VERSION ""

NS_ :

BS_:

BU_: EMS EAS

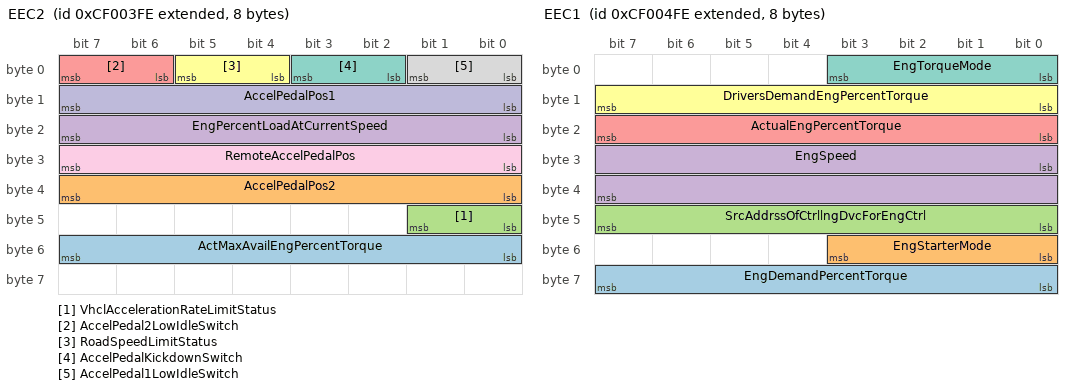
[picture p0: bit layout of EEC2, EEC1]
BO_ 2364539902 EEC2: 8 Vector__XXX
 SG_ ActMaxAvailEngPercentTorque : 48|8@1+ (0.4,0) [0|100] "%" Vector__XXX
 SG_ AccelPedalPos2 : 32|8@1+ (0.4,0) [0|100] "%" Vector__XXX
 SG_ VhclAccelerationRateLimitStatus : 40|2@1+ (1,0) [0|3] "" Vector__XXX
 SG_ EngPercentLoadAtCurrentSpeed : 16|8@1+ (1,0) [0|250] "%" Vector__XXX
 SG_ AccelPedal2LowIdleSwitch : 6|2@1+ (1,0) [0|3] "" Vector__XXX
 SG_ RoadSpeedLimitStatus : 4|2@1+ (1,0) [0|3] "" Vector__XXX
 SG_ AccelPedalKickdownSwitch : 2|2@1+ (1,0) [0|3] "" Vector__XXX
 SG_ AccelPedal1LowIdleSwitch : 0|2@1+ (1,0) [0|3] "" Vector__XXX
 SG_ RemoteAccelPedalPos : 24|8@1+ (0.4,0) [0|100] "%" Vector__XXX
 SG_ AccelPedalPos1 : 8|8@1+ (0.4,0) [0|100] "%" Vector__XXX

BO_ 2364540158 EEC1: 8 Vector__XXX
 SG_ EngDemandPercentTorque : 56|8@1+ (1,-125) [-125|125] "%" Vector__XXX
 SG_ EngStarterMode : 48|4@1+ (1,0) [0|15] "" Vector__XXX
 SG_ SrcAddrssOfCtrllngDvcForEngCtrl : 40|8@1+ (1,0) [0|255] "" Vector__XXX
 SG_ EngSpeed : 24|16@1+ (0.125,0) [0|8031.875] "rpm" Vector__XXX
 SG_ ActualEngPercentTorque : 16|8@1+ (1,-125) [-125|125] "%" Vector__XXX
 SG_ DriversDemandEngPercentTorque : 8|8@1+ (1,-125) [-125|125] "%" Vector__XXX
 SG_ EngTorqueMode : 0|4@1+ (1,0) [0|15] "" Vector__XXX

BO_ 2566768126 ECUID: 8 Vector__XXX

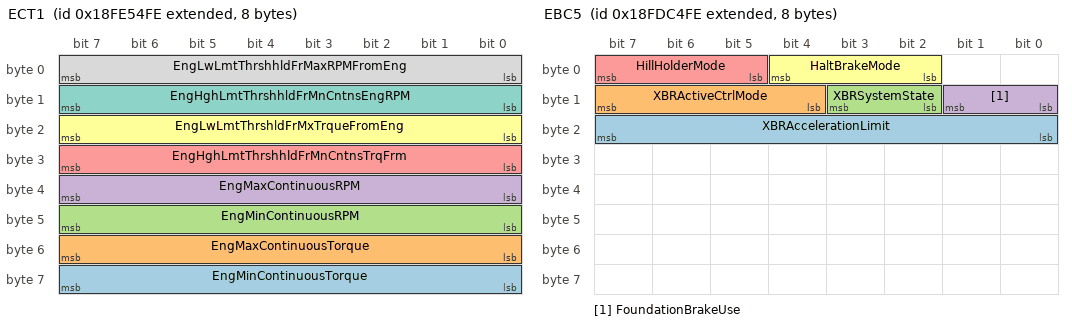
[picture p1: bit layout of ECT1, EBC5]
BO_ 2566804734 ECT1: 8 Vector__XXX
 SG_ EngMinContinuousTorque : 56|8@1+ (1,-125) [-125|125] "%" Vector__XXX
 SG_ EngMaxContinuousTorque : 48|8@1+ (1,-125) [-125|125] "%" Vector__XXX
 SG_ EngMinContinuousRPM : 40|8@1+ (32,0) [0|8000] "rpm" Vector__XXX
 SG_ EngMaxContinuousRPM : 32|8@1+ (32,0) [0|8000] "rpm" Vector__XXX
 SG_ EngHghLmtThrshhldFrMnCntnsTrqFrm : 24|8@1+ (1,-125) [-125|125] "%" Vector__XXX
 SG_ EngLwLmtThrshldFrMxTrqueFromEng : 16|8@1+ (1,-125) [-125|125] "%" Vector__XXX
 SG_ EngHghLmtThrshhldFrMnCntnsEngRPM : 8|8@1+ (32,0) [0|8000] "rpm" Vector__XXX
 SG_ EngLwLmtThrshhldFrMaxRPMFromEng : 0|8@1+ (32,0) [0|8000] "rpm" Vector__XXX

BO_ 2566841342 EC: 38 Vector__XXX
 SG_ SupportTSC1CtrlPurposeGroup4Of4 : 304|8@1+ (1,0) [0|255] "" Vector__XXX
 SG_ SupportVariableRateTSC1Message : 272|8@1+ (1,0) [0|255] "" Vector__XXX
 SG_ SupportTSC1CtrlPurposeGroup3Of4 : 296|8@1+ (1,0) [0|255] "" Vector__XXX
 SG_ SupportTSC1CtrlPurposeGroup2Of4 : 288|8@1+ (1,0) [0|255] "" Vector__XXX
 SG_ SupportTSC1CtrlPurposeGroup1Of4 : 280|8@1+ (1,0) [0|255] "" Vector__XXX
 SG_ EngDefaultTorqueLimit : 256|16@1+ (1,0) [0|64255] "Nm" Vector__XXX
 SG_ EngMomentOfInertia : 240|16@1+ (0.004,0) [0|257.02] "kg-m²" Vector__XXX
 SG_ EngExRngRqdSpdCtrlRngUpperLimit : 224|16@1+ (0.125,0) [0|8031.875] "rpm" Vector__XXX
 SG_ EngRqdTorqueCtrlRangeUpperLimit : 216|8@1+ (1,-125) [-125|125] "%" Vector__XXX
 SG_ EngRqdTorqueCtrlRangeLowerLimit : 208|8@1+ (1,-125) [-125|125] "%" Vector__XXX
 SG_ EngRqedSpeedCtrlRangeUpperLimit : 200|8@1+ (10,0) [0|2500] "rpm" Vector__XXX
 SG_ EngRqedSpeedCtrlRangeLowerLimit : 192|8@1+ (10,0) [0|2500] "rpm" Vector__XXX
 SG_ EngMxMomentaryOverrideTimeLimit : 184|8@1+ (0.1,0) [0|25] "s" Vector__XXX
 SG_ EngMxMmntaryOverrideSpeedPoint7 : 168|16@1+ (0.125,0) [0|8031.875] "rpm" Vector__XXX
 SG_ EngReferenceTorque : 152|16@1+ (1,0) [0|64255] "Nm" Vector__XXX
 SG_ EngSpeedAtHighIdlePoint6 : 120|16@1+ (0.125,0) [0|8031.875] "rpm" Vector__XXX
 SG_ EngGainOfEndspeedGovernor : 136|16@1+ (0.00078125,0) [0|50.2] "%/rpm" Vector__XXX
 SG_ EngPercentTorqueAtPoint5 : 112|8@1+ (1,-125) [-125|125] "%" Vector__XXX
 SG_ EngSpeedAtPoint5 : 96|16@1+ (0.125,0) [0|8031.875] "rpm" Vector__XXX
 SG_ EngPercentTorqueAtPoint4 : 88|8@1+ (1,-125) [-125|125] "%" Vector__XXX
 SG_ EngSpeedAtPoint4 : 72|16@1+ (0.125,0) [0|8031.875] "rpm" Vector__XXX
 SG_ EngPercentTorqueAtPoint3 : 64|8@1+ (1,-125) [-125|125] "%" Vector__XXX
 SG_ EngSpeedAtPoint3 : 48|16@1+ (0.125,0) [0|8031.875] "rpm" Vector__XXX
 SG_ EngPercentTorqueAtPoint2 : 40|8@1+ (1,-125) [-125|125] "%" Vector__XXX
 SG_ EngSpeedAtPoint2 : 24|16@1+ (0.125,0) [0|8031.875] "rpm" Vector__XXX
 SG_ EngPercentTorqueAtIdlePoint1 : 16|8@1+ (1,-125) [-125|125] "%" Vector__XXX
 SG_ EngSpeedAtIdlePoint1 : 0|16@1+ (0.125,0) [0|8031.875] "rpm" Vector__XXX

BO_ 2566767870 EBC5: 8 Vector__XXX
 SG_ XBRAccelerationLimit : 16|8@1+ (0.1,-12.5) [-12.5|12.5] "m/s²" Vector__XXX
 SG_ XBRActiveCtrlMode : 12|4@1+ (1,0) [0|15] "" Vector__XXX
 SG_ XBRSystemState : 10|2@1+ (1,0) [0|3] "" Vector__XXX
 SG_ FoundationBrakeUse : 8|2@1+ (1,0) [0|3] "" Vector__XXX
 SG_ HillHolderMode : 5|3@1+ (1,0) [0|7] "" Vector__XXX
 SG_ HaltBrakeMode : 2|3@1+ (1,0) [0|7] "" Vector__XXX

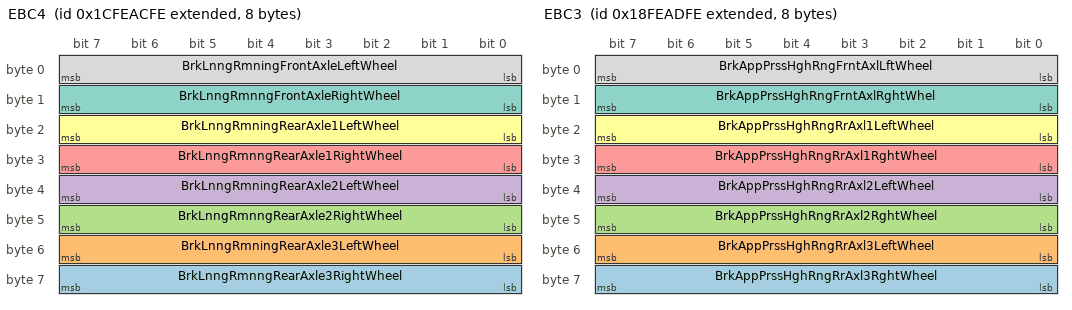
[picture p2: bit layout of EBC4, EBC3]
BO_ 2633936126 EBC4: 8 Vector__XXX
 SG_ BrkLnngRmnngRearAxle3RightWheel : 56|8@1+ (0.4,0) [0|100] "%" Vector__XXX
 SG_ BrkLnngRmningRearAxle3LeftWheel : 48|8@1+ (0.4,0) [0|100] "%" Vector__XXX
 SG_ BrkLnngRmnngRearAxle2RightWheel : 40|8@1+ (0.4,0) [0|100] "%" Vector__XXX
 SG_ BrkLnngRmningRearAxle2LeftWheel : 32|8@1+ (0.4,0) [0|100] "%" Vector__XXX
 SG_ BrkLnngRmnngRearAxle1RightWheel : 24|8@1+ (0.4,0) [0|100] "%" Vector__XXX
 SG_ BrkLnngRmningRearAxle1LeftWheel : 16|8@1+ (0.4,0) [0|100] "%" Vector__XXX
 SG_ BrkLnngRmnngFrontAxleRightWheel : 8|8@1+ (0.4,0) [0|100] "%" Vector__XXX
 SG_ BrkLnngRmningFrontAxleLeftWheel : 0|8@1+ (0.4,0) [0|100] "%" Vector__XXX

BO_ 2566827518 EBC3: 8 Vector__XXX
 SG_ BrkAppPrssHghRngRrAxl3RghtWheel : 56|8@1+ (5,0) [0|1250] "kPa" Vector__XXX
 SG_ BrkAppPrssHghRngRrAxl3LeftWheel : 48|8@1+ (5,0) [0|1250] "kPa" Vector__XXX
 SG_ BrkAppPrssHghRngRrAxl2RghtWheel : 40|8@1+ (5,0) [0|1250] "kPa" Vector__XXX
 SG_ BrkAppPrssHghRngRrAxl2LeftWheel : 32|8@1+ (5,0) [0|1250] "kPa" Vector__XXX
 SG_ BrkAppPrssHghRngRrAxl1RghtWheel : 24|8@1+ (5,0) [0|1250] "kPa" Vector__XXX
 SG_ BrkAppPrssHghRngRrAxl1LeftWheel : 16|8@1+ (5,0) [0|1250] "kPa" Vector__XXX
 SG_ BrkAppPrssHghRngFrntAxlRghtWhel : 8|8@1+ (5,0) [0|1250] "kPa" Vector__XXX
 SG_ BrkAppPrssHghRngFrntAxlLftWheel : 0|8@1+ (5,0) [0|1250] "kPa" Vector__XXX

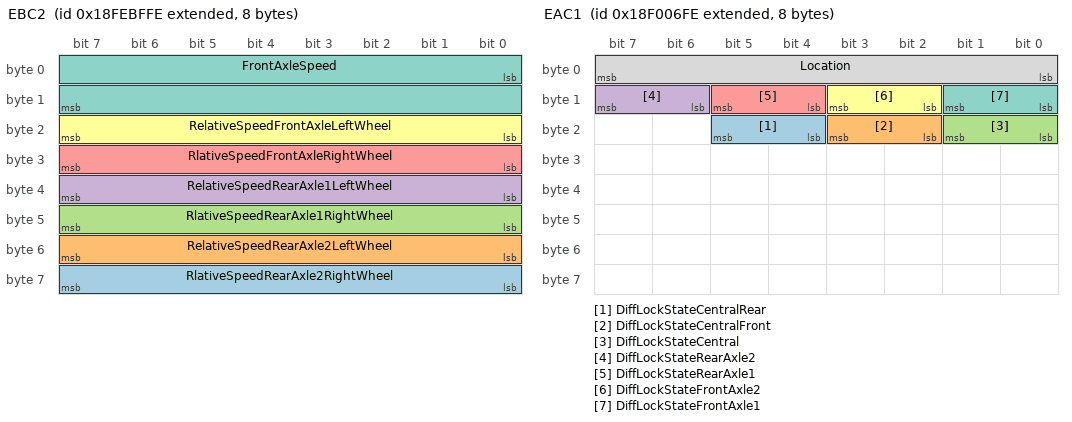
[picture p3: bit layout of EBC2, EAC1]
BO_ 2566832126 EBC2: 8 Vector__XXX
 SG_ RlativeSpeedRearAxle2RightWheel : 56|8@1+ (0.0625,-7.8125) [-7.8125|7.8125] "km/h" Vector__XXX
 SG_ RelativeSpeedRearAxle2LeftWheel : 48|8@1+ (0.0625,-7.8125) [-7.8125|7.8125] "km/h" Vector__XXX
 SG_ RlativeSpeedRearAxle1RightWheel : 40|8@1+ (0.0625,-7.8125) [-7.8125|7.8125] "km/h" Vector__XXX
 SG_ RelativeSpeedRearAxle1LeftWheel : 32|8@1+ (0.0625,-7.8125) [-7.8125|7.8125] "km/h" Vector__XXX
 SG_ RlativeSpeedFrontAxleRightWheel : 24|8@1+ (0.0625,-7.8125) [-7.8125|7.8125] "km/h" Vector__XXX
 SG_ RelativeSpeedFrontAxleLeftWheel : 16|8@1+ (0.0625,-7.8125) [-7.8125|7.8125] "km/h" Vector__XXX
 SG_ FrontAxleSpeed : 0|16@1+ (0.00390625,0) [0|250.996] "km/h" Vector__XXX

BO_ 2565865982 EBC1: 8 Vector__XXX
 SG_ SrcAddrssOfCtrllngDvcFrBrkCntrl : 48|8@1+ (1,0) [0|255] "" Vector__XXX
 SG_ BrakePedalPos : 8|8@1+ (0.4,0) [0|100] "%" Vector__XXX
 SG_ TrctrMntdTrilerABSWarningSignal : 62|2@1+ (1,0) [0|3] "" Vector__XXX
 SG_ TrailerABSStatus : 60|2@1+ (1,0) [0|3] "" Vector__XXX
 SG_ HaltBrakeSwitch : 58|2@1+ (1,0) [0|3] "" Vector__XXX
 SG_ ATC_ASRInformationSignal : 46|2@1+ (1,0) [0|3] "" Vector__XXX
 SG_ ABS_EBSAmberWarningSignal : 44|2@1+ (1,0) [0|3] "" Vector__XXX
 SG_ EBSRedWarningSignal : 42|2@1+ (1,0) [0|3] "" Vector__XXX
 SG_ ABSFullyOperational : 40|2@1+ (1,0) [0|3] "" Vector__XXX
 SG_ EngRetarderSelection : 32|8@1+ (0.4,0) [0|100] "%" Vector__XXX
 SG_ RemoteAccelEnableSwitch : 30|2@1+ (1,0) [0|3] "" Vector__XXX
 SG_ EngAuxEngShutdownSwitch : 28|2@1+ (1,0) [0|3] "" Vector__XXX
 SG_ EngDerateSwitch : 26|2@1+ (1,0) [0|3] "" Vector__XXX
 SG_ AccelInterlockSwitch : 24|2@1+ (1,0) [0|3] "" Vector__XXX
 SG_ TractionCtrlOverrideSwitch : 22|2@1+ (1,0) [0|3] "" Vector__XXX
 SG_ ASRHillHolderSwitch : 20|2@1+ (1,0) [0|3] "" Vector__XXX
 SG_ ASROffroadSwitch : 18|2@1+ (1,0) [0|3] "" Vector__XXX
 SG_ ABSOffroadSwitch : 16|2@1+ (1,0) [0|3] "" Vector__XXX
 SG_ EBSBrakeSwitch : 6|2@1+ (1,0) [0|3] "" Vector__XXX
 SG_ AntiLockBrakingActive : 4|2@1+ (1,0) [0|3] "" Vector__XXX
 SG_ ASRBrakeCtrlActive : 2|2@1+ (1,0) [0|3] "" Vector__XXX
 SG_ ASREngCtrlActive : 0|2@1+ (1,0) [0|3] "" Vector__XXX

BO_ 2565867262 EAC1: 8 Vector__XXX
 SG_ DiffLockStateCentralRear : 20|2@1+ (1,0) [0|3] "" Vector__XXX
 SG_ DiffLockStateCentralFront : 18|2@1+ (1,0) [0|3] "" Vector__XXX
 SG_ DiffLockStateCentral : 16|2@1+ (1,0) [0|3] "" Vector__XXX
 SG_ DiffLockStateRearAxle2 : 14|2@1+ (1,0) [0|3] "" Vector__XXX
 SG_ DiffLockStateRearAxle1 : 12|2@1+ (1,0) [0|3] "" Vector__XXX
 SG_ DiffLockStateFrontAxle2 : 10|2@1+ (1,0) [0|3] "" Vector__XXX
 SG_ DiffLockStateFrontAxle1 : 8|2@1+ (1,0) [0|3] "" Vector__XXX
 SG_ Location : 0|8@1+ (1,0) [0|255] "" Vector__XXX

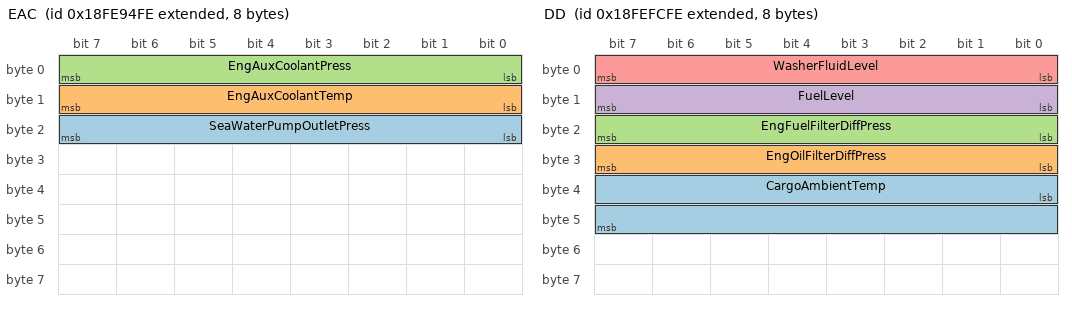
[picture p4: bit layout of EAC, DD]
BO_ 2566821118 EAC: 8 Vector__XXX
 SG_ SeaWaterPumpOutletPress : 16|8@1+ (2,0) [0|500] "kPa" Vector__XXX
 SG_ EngAuxCoolantTemp : 8|8@1+ (1,-40) [-40|210] "deg" Vector__XXX
 SG_ EngAuxCoolantPress : 0|8@1+ (4,0) [0|1000] "kPa" Vector__XXX

BO_ 2566810622 DI: 8 Vector__XXX

BO_ 2566847742 DD: 8 Vector__XXX
 SG_ CargoAmbientTemp : 32|16@1+ (0.03125,-273) [-273|1735] "deg" Vector__XXX
 SG_ EngOilFilterDiffPress : 24|8@1+ (0.5,0) [0|125] "kPa" Vector__XXX
 SG_ EngFuelFilterDiffPress : 16|8@1+ (2,0) [0|500] "kPa" Vector__XXX
 SG_ FuelLevel : 8|8@1+ (0.4,0) [0|100] "%" Vector__XXX
 SG_ WasherFluidLevel : 0|8@1+ (0.4,0) [0|100] "%" Vector__XXX

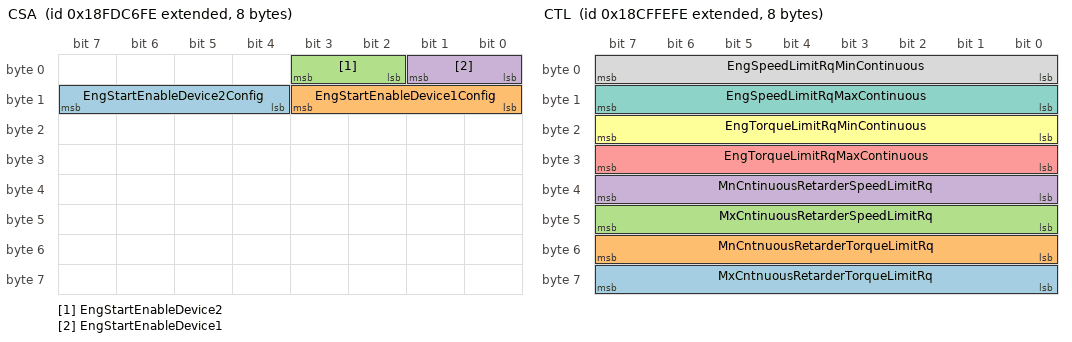
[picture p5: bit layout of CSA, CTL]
BO_ 2566768382 CSA: 8 Vector__XXX
 SG_ EngStartEnableDevice2Config : 12|4@1+ (1,0) [0|15] "" Vector__XXX
 SG_ EngStartEnableDevice1Config : 8|4@1+ (1,0) [0|15] "" Vector__XXX
 SG_ EngStartEnableDevice2 : 2|2@1+ (1,0) [0|3] "" Vector__XXX
 SG_ EngStartEnableDevice1 : 0|2@1+ (1,0) [0|3] "" Vector__XXX

BO_ 2566811902 CVW: 8 Vector__XXX
 SG_ PoweredVehicleWeight : 0|16@1+ (10,0) [0|642550] "kg" Vector__XXX
 SG_ GrossCombinationVehicleWeight : 16|16@1+ (10,0) [0|642550] "kg" Vector__XXX

BO_ 2563768062 CTL: 8 Vector__XXX
 SG_ MxCntnuousRetarderTorqueLimitRq : 56|8@1+ (1,-125) [-125|125] "%" Vector__XXX
 SG_ MnCntnuousRetarderTorqueLimitRq : 48|8@1+ (1,-125) [-125|125] "%" Vector__XXX
 SG_ MxCntinuousRetarderSpeedLimitRq : 40|8@1+ (32,0) [0|8000] "rpm" Vector__XXX
 SG_ MnCntinuousRetarderSpeedLimitRq : 32|8@1+ (32,0) [0|8000] "rpm" Vector__XXX
 SG_ EngTorqueLimitRqMaxContinuous : 24|8@1+ (1,-125) [-125|125] "%" Vector__XXX
 SG_ EngTorqueLimitRqMinContinuous : 16|8@1+ (1,-125) [-125|125] "%" Vector__XXX
 SG_ EngSpeedLimitRqMaxContinuous : 8|8@1+ (32,0) [0|8000] "rpm" Vector__XXX
 SG_ EngSpeedLimitRqMinContinuous : 0|8@1+ (32,0) [0|8000] "rpm" Vector__XXX

BO_ 2633924862 CT6: 8 Vector__XXX
 SG_ EngAverageCombustionTime : 16|16@1+ (0.01,0) [0|642.55] "ms" Vector__XXX
 SG_ EngDesiredCombustionTime : 0|16@1+ (0.01,0) [0|642.55] "ms" Vector__XXX

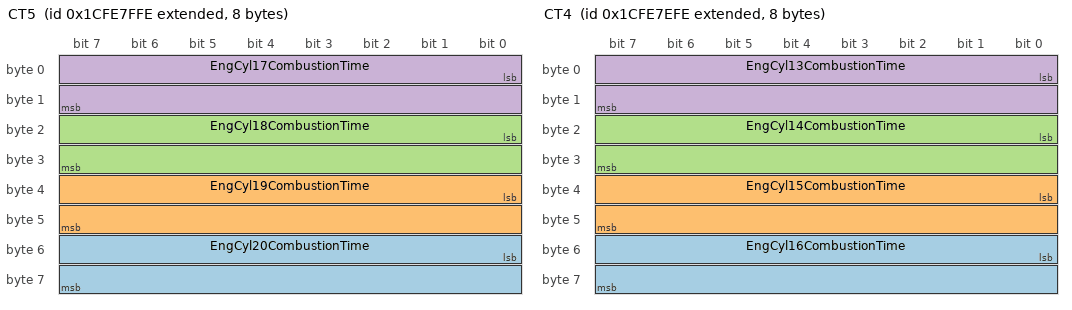
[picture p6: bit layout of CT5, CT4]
BO_ 2633924606 CT5: 8 Vector__XXX
 SG_ EngCyl20CombustionTime : 48|16@1+ (0.01,0) [0|642.55] "ms" Vector__XXX
 SG_ EngCyl19CombustionTime : 32|16@1+ (0.01,0) [0|642.55] "ms" Vector__XXX
 SG_ EngCyl18CombustionTime : 16|16@1+ (0.01,0) [0|642.55] "ms" Vector__XXX
 SG_ EngCyl17CombustionTime : 0|16@1+ (0.01,0) [0|642.55] "ms" Vector__XXX

BO_ 2633924350 CT4: 8 Vector__XXX
 SG_ EngCyl16CombustionTime : 48|16@1+ (0.01,0) [0|642.55] "ms" Vector__XXX
 SG_ EngCyl15CombustionTime : 32|16@1+ (0.01,0) [0|642.55] "ms" Vector__XXX
 SG_ EngCyl14CombustionTime : 16|16@1+ (0.01,0) [0|642.55] "ms" Vector__XXX
 SG_ EngCyl13CombustionTime : 0|16@1+ (0.01,0) [0|642.55] "ms" Vector__XXX

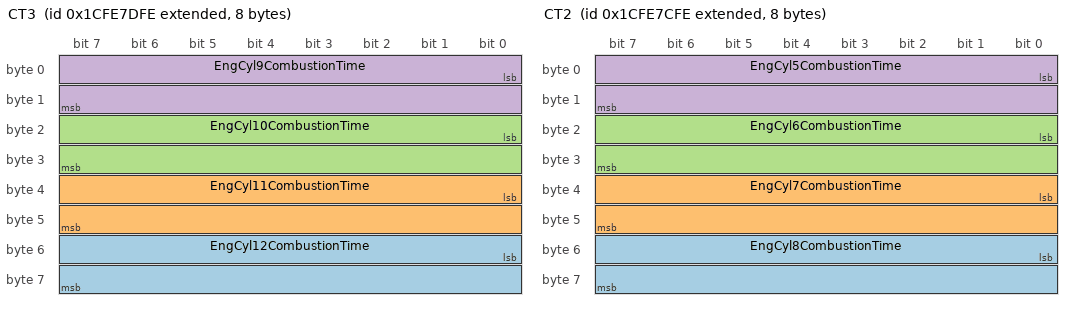
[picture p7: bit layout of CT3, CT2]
BO_ 2633924094 CT3: 8 Vector__XXX
 SG_ EngCyl12CombustionTime : 48|16@1+ (0.01,0) [0|642.55] "ms" Vector__XXX
 SG_ EngCyl11CombustionTime : 32|16@1+ (0.01,0) [0|642.55] "ms" Vector__XXX
 SG_ EngCyl10CombustionTime : 16|16@1+ (0.01,0) [0|642.55] "ms" Vector__XXX
 SG_ EngCyl9CombustionTime : 0|16@1+ (0.01,0) [0|642.55] "ms" Vector__XXX

BO_ 2633923838 CT2: 8 Vector__XXX
 SG_ EngCyl8CombustionTime : 48|16@1+ (0.01,0) [0|642.55] "ms" Vector__XXX
 SG_ EngCyl7CombustionTime : 32|16@1+ (0.01,0) [0|642.55] "ms" Vector__XXX
 SG_ EngCyl6CombustionTime : 16|16@1+ (0.01,0) [0|642.55] "ms" Vector__XXX
 SG_ EngCyl5CombustionTime : 0|16@1+ (0.01,0) [0|642.55] "ms" Vector__XXX

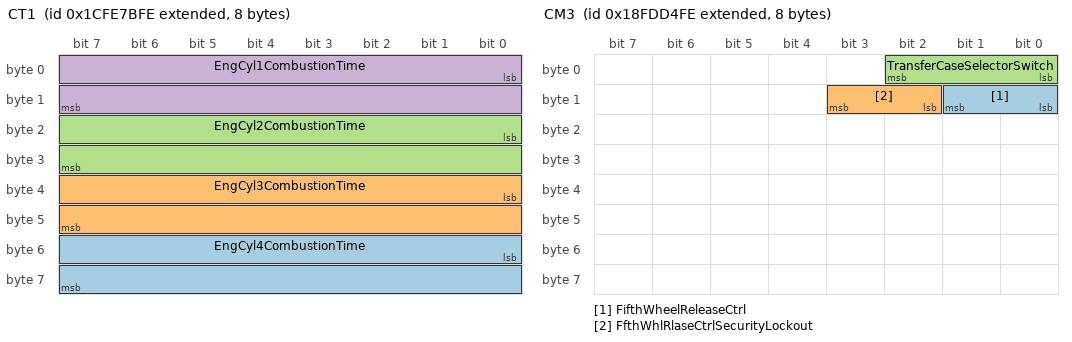
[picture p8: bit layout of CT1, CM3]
BO_ 2633923582 CT1: 8 Vector__XXX
 SG_ EngCyl4CombustionTime : 48|16@1+ (0.01,0) [0|642.55] "ms" Vector__XXX
 SG_ EngCyl3CombustionTime : 32|16@1+ (0.01,0) [0|642.55] "ms" Vector__XXX
 SG_ EngCyl2CombustionTime : 16|16@1+ (0.01,0) [0|642.55] "ms" Vector__XXX
 SG_ EngCyl1CombustionTime : 0|16@1+ (0.01,0) [0|642.55] "ms" Vector__XXX

BO_ 2633878014 CMI: 8 Vector__XXX
 SG_ TotalCountOfConfigChangesMade : 0|16@1+ (1,0) [0|64255] "counts" Vector__XXX

BO_ 2566771966 CM3: 8 Vector__XXX
 SG_ FifthWheelReleaseCtrl : 8|2@1+ (1,0) [0|3] "" Vector__XXX
 SG_ FfthWhlRlaseCtrlSecurityLockout : 10|2@1+ (1,0) [0|3] "" Vector__XXX
 SG_ TransferCaseSelectorSwitch : 0|3@1+ (1,0) [0|7] "" Vector__XXX

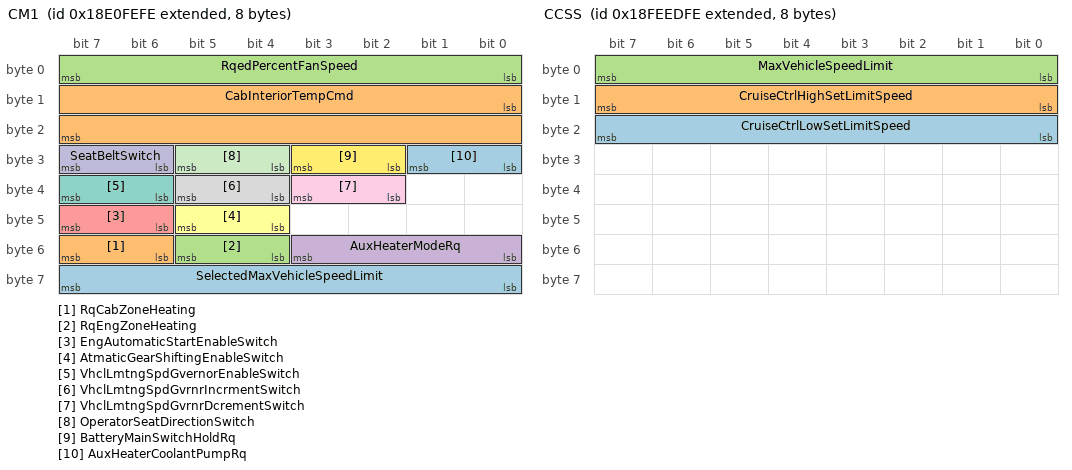
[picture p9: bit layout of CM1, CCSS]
BO_ 2564882174 CM1: 8 Vector__XXX
 SG_ SelectedMaxVehicleSpeedLimit : 56|8@1+ (1,0) [0|250] "" Vector__XXX
 SG_ RqCabZoneHeating : 54|2@1+ (1,0) [0|3] "" Vector__XXX
 SG_ RqEngZoneHeating : 52|2@1+ (1,0) [0|3] "" Vector__XXX
 SG_ AuxHeaterModeRq : 48|4@1+ (1,0) [0|15] "" Vector__XXX
 SG_ EngAutomaticStartEnableSwitch : 46|2@1+ (1,0) [0|3] "" Vector__XXX
 SG_ AtmaticGearShiftingEnableSwitch : 44|2@1+ (1,0) [0|3] "" Vector__XXX
 SG_ VhclLmtngSpdGvernorEnableSwitch : 38|2@1+ (1,0) [0|3] "" Vector__XXX
 SG_ VhclLmtngSpdGvrnrIncrmentSwitch : 36|2@1+ (1,0) [0|3] "" Vector__XXX
 SG_ VhclLmtngSpdGvrnrDcrementSwitch : 34|2@1+ (1,0) [0|3] "" Vector__XXX
 SG_ SeatBeltSwitch : 30|2@1+ (1,0) [0|3] "" Vector__XXX
 SG_ OperatorSeatDirectionSwitch : 28|2@1+ (1,0) [0|3] "" Vector__XXX
 SG_ BatteryMainSwitchHoldRq : 26|2@1+ (1,0) [0|3] "" Vector__XXX
 SG_ AuxHeaterCoolantPumpRq : 24|2@1+ (1,0) [0|3] "" Vector__XXX
 SG_ CabInteriorTempCmd : 8|16@1+ (0.03125,-273) [-273|1735] "deg" Vector__XXX
 SG_ RqedPercentFanSpeed : 0|8@1+ (0.4,0) [0|100] "%" Vector__XXX

BO_ 2563833598 CL: 8 Vector__XXX
 SG_ IlluminationBrightnessPercent : 0|8@1+ (0.4,0) [0|100] "%" Vector__XXX

BO_ 2566843390 CI: 8 Vector__XXX

BO_ 2566844926 CCVS: 8 Vector__XXX
 SG_ EngShutdownOverrideSwitch : 62|2@1+ (1,0) [0|3] "" Vector__XXX
 SG_ EngTestModeSwitch : 60|2@1+ (1,0) [0|3] "" Vector__XXX
 SG_ EngIdleDecrementSwitch : 58|2@1+ (1,0) [0|3] "" Vector__XXX
 SG_ EngIdleIncrementSwitch : 56|2@1+ (1,0) [0|3] "" Vector__XXX
 SG_ CruiseCtrlStates : 53|3@1+ (1,0) [0|7] "" Vector__XXX
 SG_ PTOState : 48|5@1+ (1,0) [0|31] "" Vector__XXX
 SG_ CruiseCtrlSetSpeed : 40|8@1+ (1,0) [0|250] "km/h" Vector__XXX
 SG_ CruiseCtrlAccelerateSwitch : 38|2@1+ (1,0) [0|3] "" Vector__XXX
 SG_ CruiseCtrlResumeSwitch : 36|2@1+ (1,0) [0|3] "" Vector__XXX
 SG_ CruiseCtrlCoastSwitch : 34|2@1+ (1,0) [0|3] "" Vector__XXX
 SG_ CruiseCtrlSetSwitch : 32|2@1+ (1,0) [0|3] "" Vector__XXX
 SG_ ClutchSwitch : 30|2@1+ (1,0) [0|3] "" Vector__XXX
 SG_ BrakeSwitch : 28|2@1+ (1,0) [0|3] "" Vector__XXX
 SG_ CruiseCtrlEnableSwitch : 26|2@1+ (1,0) [0|3] "" Vector__XXX
 SG_ CruiseCtrlActive : 24|2@1+ (1,0) [0|3] "" Vector__XXX
 SG_ WheelBasedVehicleSpeed : 8|16@1+ (0.00390625,0) [0|250.996] "km/h" Vector__XXX
 SG_ CruiseCtrlPauseSwitch : 4|2@1+ (1,0) [0|3] "" Vector__XXX
 SG_ ParkingBrakeSwitch : 2|2@1+ (1,0) [0|3] "" Vector__XXX
 SG_ TwoSpeedAxleSwitch : 0|2@1+ (1,0) [0|3] "" Vector__XXX

BO_ 2566843902 CCSS: 8 Vector__XXX
 SG_ CruiseCtrlLowSetLimitSpeed : 16|8@1+ (1,0) [0|250] "km/h" Vector__XXX
 SG_ CruiseCtrlHighSetLimitSpeed : 8|8@1+ (1,0) [0|250] "km/h" Vector__XXX
 SG_ MaxVehicleSpeedLimit : 0|8@1+ (1,0) [0|250] "km/h" Vector__XXX

BO_ 2566809598 CCC: 8 Vector__XXX
 SG_ AuxHeaterMaxOutputPower : 0|16@1+ (2,0) [0|128510] "W" Vector__XXX

BO_ 2633940222 CBI: 16 Vector__XXX
 SG_ TripServiceBrakeApps : 96|2@1+ (1,0) [0|3] "" Vector__XXX
 SG_ TripServiceBrakeDistance : 64|32@1+ (0.125,0) [0|526385151.9] "km" Vector__XXX
 SG_ TripCompressionBrakeDistance : 32|32@1+ (0.125,0) [0|526385151.9] "km" Vector__XXX
 SG_ TotalCompressionBrakeDistance : 0|32@1+ (0.125,0) [0|526385151.9] "km" Vector__XXX

BO_ 2566775294 CACI: 8 Vector__XXX
 SG_ CbA_CRfrgrntCmprssorOutletPress : 0|8@1+ (16,0) [0|4000] "kPa" Vector__XXX

BO_ 2566803710 BT1: 8 Vector__XXX
 SG_ Battery2Temp : 8|8@1+ (1,-40) [-40|210] "deg" Vector__XXX
 SG_ Battery1Temp : 0|8@1+ (1,-40) [-40|210] "deg" Vector__XXX

BO_ 2566809342 BM: 8 Vector__XXX
 SG_ BatteryMainSwitchHoldState : 0|2@1+ (1,0) [0|3] "" Vector__XXX

BO_ 2365446910 BJM3: 8 Vector__XXX
 SG_ Joystick3XAxisDetentPosStatus : 38|2@1+ (1,0) [0|3] "" Vector__XXX
 SG_ Joystick3Button9PressedStatus : 62|2@1+ (1,0) [0|3] "" Vector__XXX
 SG_ Joystick3Button10PressedStatus : 60|2@1+ (1,0) [0|3] "" Vector__XXX
 SG_ Joystick3Button11PressedStatus : 58|2@1+ (1,0) [0|3] "" Vector__XXX
 SG_ Joystick3Button12PressedStatus : 56|2@1+ (1,0) [0|3] "" Vector__XXX
 SG_ Joystick3YAxisDetentPosStatus : 36|2@1+ (1,0) [0|3] "" Vector__XXX
 SG_ Joystick3YAxisPos : 22|10@1+ (0.1,0) [0|102] "%" Vector__XXX
 SG_ Jystck3YAxsLvrFrwrdPstvPsStatus : 20|2@1+ (1,0) [0|3] "" Vector__XXX
 SG_ Jystck3YAxsLvrBckNgtvePosStatus : 18|2@1+ (1,0) [0|3] "" Vector__XXX
 SG_ Joystick3YAxisNeutralPosStatus : 16|2@1+ (1,0) [0|3] "" Vector__XXX
 SG_ Joystick3XAxisPos : 6|10@1+ (0.1,0) [0|102] "%" Vector__XXX
 SG_ Jystck3XAxsLvrRghtPstvPosStatus : 4|2@1+ (1,0) [0|3] "" Vector__XXX
 SG_ Jystck3XAxsLvrLftNgtvePosStatus : 2|2@1+ (1,0) [0|3] "" Vector__XXX
 SG_ Joystick3XAxisNeutralPosStatus : 0|2@1+ (1,0) [0|3] "" Vector__XXX
 SG_ Joystick3Button5PressedStatus : 54|2@1+ (1,0) [0|3] "" Vector__XXX
 SG_ Joystick3Button6PressedStatus : 52|2@1+ (1,0) [0|3] "" Vector__XXX
 SG_ Joystick3Button7PressedStatus : 50|2@1+ (1,0) [0|3] "" Vector__XXX
 SG_ Joystick3Button8PressedStatus : 48|2@1+ (1,0) [0|3] "" Vector__XXX
 SG_ Joystick3Button1PressedStatus : 46|2@1+ (1,0) [0|3] "" Vector__XXX
 SG_ Joystick3Button2PressedStatus : 44|2@1+ (1,0) [0|3] "" Vector__XXX
 SG_ Joystick3Button3PressedStatus : 42|2@1+ (1,0) [0|3] "" Vector__XXX
 SG_ Joystick3Button4PressedStatus : 40|2@1+ (1,0) [0|3] "" Vector__XXX

BO_ 2365446398 BJM2: 8 Vector__XXX
 SG_ Joystick2XAxisDetentPosStatus : 38|2@1+ (1,0) [0|3] "" Vector__XXX
 SG_ Joystick2YAxisDetentPosStatus : 36|2@1+ (1,0) [0|3] "" Vector__XXX
 SG_ Joystick2YAxisPos : 22|10@1+ (0.1,0) [0|102] "%" Vector__XXX
 SG_ Jystck2YAxsLvrFrwrdPstvPsStatus : 20|2@1+ (1,0) [0|3] "" Vector__XXX
 SG_ Jystck2YAxsLvrBckNgtvePosStatus : 18|2@1+ (1,0) [0|3] "" Vector__XXX
 SG_ Joystick2YAxisNeutralPosStatus : 16|2@1+ (1,0) [0|3] "" Vector__XXX
 SG_ Joystick2XAxisPos : 6|10@1+ (0.1,0) [0|102] "%" Vector__XXX
 SG_ Jystck2XAxsLvrRghtPstvPosStatus : 4|2@1+ (1,0) [0|3] "" Vector__XXX
 SG_ Jystck2XAxsLvrLftNgtvePosStatus : 2|2@1+ (1,0) [0|3] "" Vector__XXX
 SG_ Joystick2XAxisNeutralPosStatus : 0|2@1+ (1,0) [0|3] "" Vector__XXX
 SG_ Joystick2Button9PressedStatus : 62|2@1+ (1,0) [0|3] "" Vector__XXX
 SG_ Joystick2Button10PressedStatus : 60|2@1+ (1,0) [0|3] "" Vector__XXX
 SG_ Joystick2Button11PressedStatus : 58|2@1+ (1,0) [0|3] "" Vector__XXX
 SG_ Joystick2Button12PressedStatus : 56|2@1+ (1,0) [0|3] "" Vector__XXX
 SG_ Joystick2Button5PressedStatus : 54|2@1+ (1,0) [0|3] "" Vector__XXX
 SG_ Joystick2Button6PressedStatus : 52|2@1+ (1,0) [0|3] "" Vector__XXX
 SG_ Joystick2Button7PressedStatus : 50|2@1+ (1,0) [0|3] "" Vector__XXX
 SG_ Joystick2Button8PressedStatus : 48|2@1+ (1,0) [0|3] "" Vector__XXX
 SG_ Joystick2Button1PressedStatus : 46|2@1+ (1,0) [0|3] "" Vector__XXX
 SG_ Joystick2Button2PressedStatus : 44|2@1+ (1,0) [0|3] "" Vector__XXX
 SG_ Joystick2Button3PressedStatus : 42|2@1+ (1,0) [0|3] "" Vector__XXX
 SG_ Joystick2Button4PressedStatus : 40|2@1+ (1,0) [0|3] "" Vector__XXX

BO_ 2365445886 BJM1: 8 Vector__XXX
 SG_ Joystick1XAxisDetentPosStatus : 38|2@1+ (1,0) [0|3] "" Vector__XXX
 SG_ Joystick1YAxisDetentPosStatus : 36|2@1+ (1,0) [0|3] "" Vector__XXX
 SG_ Joystick1YAxisPos : 22|10@1+ (0.1,0) [0|102] "%" Vector__XXX
 SG_ Jystck1YAxsLvrFrwrdPstvPsStatus : 20|2@1+ (1,0) [0|3] "" Vector__XXX
 SG_ Jystck1YAxsLvrBckNgtvePosStatus : 18|2@1+ (1,0) [0|3] "" Vector__XXX
 SG_ Joystick1YAxisNeutralPosStatus : 16|2@1+ (1,0) [0|3] "" Vector__XXX
 SG_ Joystick1XAxisPos : 6|10@1+ (0.1,0) [0|102] "%" Vector__XXX
 SG_ Joystick1Button9PressedStatus : 62|2@1+ (1,0) [0|3] "" Vector__XXX
 SG_ Joystick1Button10PressedStatus : 60|2@1+ (1,0) [0|3] "" Vector__XXX
 SG_ Joystick1Button11PressedStatus : 58|2@1+ (1,0) [0|3] "" Vector__XXX
 SG_ Joystick1Button12PressedStatus : 56|2@1+ (1,0) [0|3] "" Vector__XXX
 SG_ Joystick1Button5PressedStatus : 54|2@1+ (1,0) [0|3] "" Vector__XXX
 SG_ Joystick1Button6PressedStatus : 52|2@1+ (1,0) [0|3] "" Vector__XXX
 SG_ Joystick1Button7PressedStatus : 50|2@1+ (1,0) [0|3] "" Vector__XXX
 SG_ Joystick1Button8PressedStatus : 48|2@1+ (1,0) [0|3] "" Vector__XXX
 SG_ Joystick1Button1PressedStatus : 46|2@1+ (1,0) [0|3] "" Vector__XXX
 SG_ Joystick1Button2PressedStatus : 44|2@1+ (1,0) [0|3] "" Vector__XXX
 SG_ Joystick1Button3PressedStatus : 42|2@1+ (1,0) [0|3] "" Vector__XXX
 SG_ Joystick1Button4PressedStatus : 40|2@1+ (1,0) [0|3] "" Vector__XXX
 SG_ Jystck1XAxsLvrRghtPstvPosStatus : 4|2@1+ (1,0) [0|3] "" Vector__XXX
 SG_ Jystck1XAxsLvrLftNgtvePosStatus : 2|2@1+ (1,0) [0|3] "" Vector__XXX
 SG_ Joystick1XAxisNeutralPosStatus : 0|2@1+ (1,0) [0|3] "" Vector__XXX

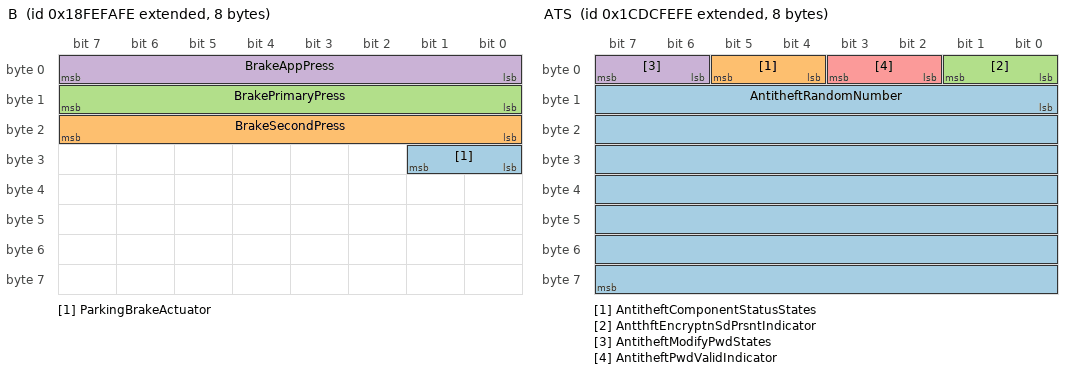
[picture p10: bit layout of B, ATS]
BO_ 2566847230 B: 8 Vector__XXX
 SG_ ParkingBrakeActuator : 24|2@1+ (1,0) [0|3] "" Vector__XXX
 SG_ BrakeSecondPress : 16|8@1+ (4,0) [0|1000] "kPa" Vector__XXX
 SG_ BrakePrimaryPress : 8|8@1+ (4,0) [0|1000] "kPa" Vector__XXX
 SG_ BrakeAppPress : 0|8@1+ (4,0) [0|1000] "kPa" Vector__XXX

BO_ 2566848254 AWPP: 8 Vector__XXX
 SG_ AuxPumpPress : 0|8@1+ (16,0) [0|4000] "kPa" Vector__XXX

BO_ 2566838782 AUXIO: 8 Vector__XXX
 SG_ AuxI_OChannel2 : 48|16@1+ (1,0) [0|64255] "counts" Vector__XXX
 SG_ AuxI_OChannel1 : 32|16@1+ (1,0) [0|64255] "counts" Vector__XXX
 SG_ AuxI_O13 : 30|2@1+ (1,0) [0|3] "" Vector__XXX
 SG_ AuxI_O14 : 28|2@1+ (1,0) [0|3] "" Vector__XXX
 SG_ AuxI_O15 : 26|2@1+ (1,0) [0|3] "" Vector__XXX
 SG_ AuxI_O16 : 24|2@1+ (1,0) [0|3] "" Vector__XXX
 SG_ AuxI_O09 : 22|2@1+ (1,0) [0|3] "" Vector__XXX
 SG_ AuxI_O10 : 20|2@1+ (1,0) [0|3] "" Vector__XXX
 SG_ AuxI_O11 : 18|2@1+ (1,0) [0|3] "" Vector__XXX
 SG_ AuxI_O12 : 16|2@1+ (1,0) [0|3] "" Vector__XXX
 SG_ AuxI_O05 : 14|2@1+ (1,0) [0|3] "" Vector__XXX
 SG_ AuxI_O06 : 12|2@1+ (1,0) [0|3] "" Vector__XXX
 SG_ AuxI_O07 : 10|2@1+ (1,0) [0|3] "" Vector__XXX
 SG_ AuxI_O08 : 8|2@1+ (1,0) [0|3] "" Vector__XXX
 SG_ AuxI_O01 : 6|2@1+ (1,0) [0|3] "" Vector__XXX
 SG_ AuxI_O02 : 4|2@1+ (1,0) [0|3] "" Vector__XXX
 SG_ AuxI_O03 : 2|2@1+ (1,0) [0|3] "" Vector__XXX
 SG_ AuxI_O04 : 0|2@1+ (1,0) [0|3] "" Vector__XXX

BO_ 2631728894 ATS: 8 Vector__XXX
 SG_ AntitheftRandomNumber : 8|56@1+ (1,0) [0|255] "" Vector__XXX
 SG_ AntitheftComponentStatusStates : 4|2@1+ (1,0) [0|3] "" Vector__XXX
 SG_ AntthftEncryptnSdPrsntIndicator : 0|2@1+ (1,0) [0|3] "" Vector__XXX
 SG_ AntitheftModifyPwdStates : 6|2@1+ (1,0) [0|3] "" Vector__XXX
 SG_ AntitheftPwdValidIndicator : 2|2@1+ (1,0) [0|3] "" Vector__XXX

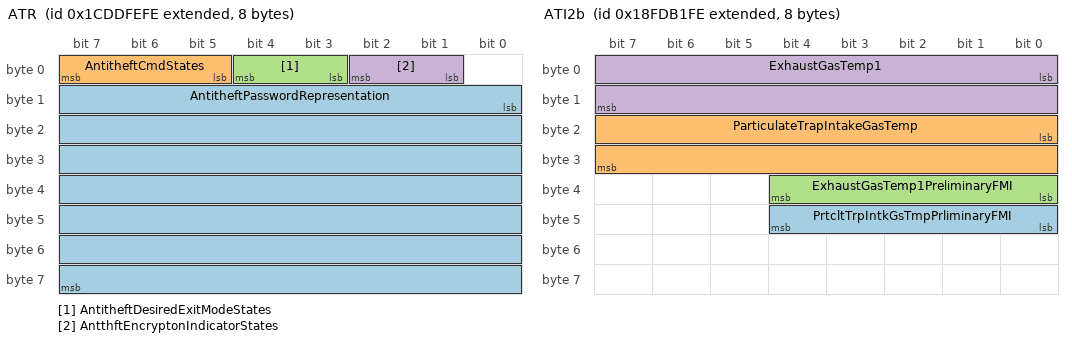
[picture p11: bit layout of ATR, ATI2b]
BO_ 2631794430 ATR: 8 Vector__XXX
 SG_ AntitheftPasswordRepresentation : 8|56@1+ (1,0) [0|255] "" Vector__XXX
 SG_ AntitheftCmdStates : 5|3@1+ (1,0) [0|7] "" Vector__XXX
 SG_ AntitheftDesiredExitModeStates : 3|2@1+ (1,0) [0|3] "" Vector__XXX
 SG_ AntthftEncryptonIndicatorStates : 1|2@1+ (1,0) [0|3] "" Vector__XXX

BO_ 2566763006 ATI2b: 8 Vector__XXX
 SG_ PrtcltTrpIntkGsTmpPrliminaryFMI : 40|5@1+ (1,0) [0|31] "" Vector__XXX
 SG_ ParticulateTrapIntakeGasTemp : 16|16@1+ (0.03125,-273) [-273|1735] "deg" Vector__XXX
 SG_ ExhaustGasTemp1PreliminaryFMI : 32|5@1+ (1,0) [0|31] "" Vector__XXX
 SG_ ExhaustGasTemp1 : 0|16@1+ (0.03125,-273) [-273|1735] "deg" Vector__XXX

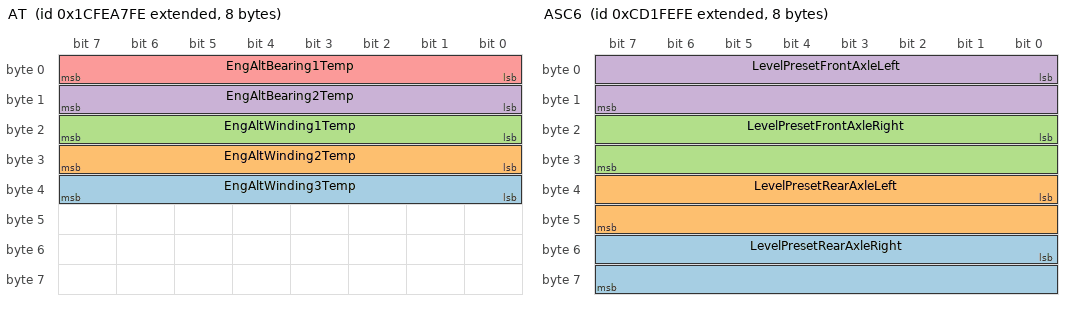
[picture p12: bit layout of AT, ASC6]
BO_ 2633934846 AT: 8 Vector__XXX
 SG_ EngAltWinding3Temp : 32|8@1+ (1,-40) [-40|210] "deg" Vector__XXX
 SG_ EngAltWinding2Temp : 24|8@1+ (1,-40) [-40|210] "deg" Vector__XXX
 SG_ EngAltWinding1Temp : 16|8@1+ (1,-40) [-40|210] "deg" Vector__XXX
 SG_ EngAltBearing2Temp : 8|8@1+ (1,-40) [-40|210] "deg" Vector__XXX
 SG_ EngAltBearing1Temp : 0|8@1+ (1,-40) [-40|210] "deg" Vector__XXX

BO_ 2362572542 ASC6: 8 Vector__XXX
 SG_ LevelPresetRearAxleRight : 48|16@1+ (0.1,-2800) [-2800|3225.5] "mm" Vector__XXX
 SG_ LevelPresetRearAxleLeft : 32|16@1+ (0.1,-2800) [-2800|3225.5] "mm" Vector__XXX
 SG_ LevelPresetFrontAxleRight : 16|16@1+ (0.1,-2800) [-2800|3225.5] "mm" Vector__XXX
 SG_ LevelPresetFrontAxleLeft : 0|16@1+ (0.1,-2800) [-2800|3225.5] "mm" Vector__XXX

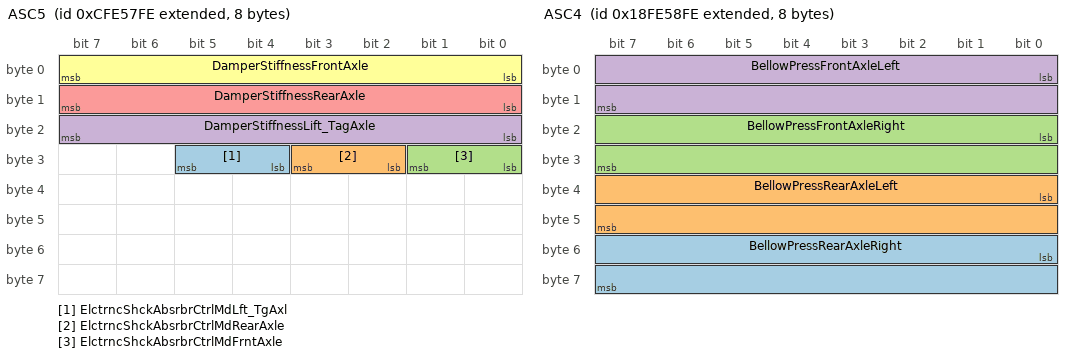
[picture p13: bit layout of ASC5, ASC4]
BO_ 2365478910 ASC5: 8 Vector__XXX
 SG_ ElctrncShckAbsrbrCtrlMdLft_TgAxl : 28|2@1+ (1,0) [0|3] "" Vector__XXX
 SG_ ElctrncShckAbsrbrCtrlMdRearAxle : 26|2@1+ (1,0) [0|3] "" Vector__XXX
 SG_ ElctrncShckAbsrbrCtrlMdFrntAxle : 24|2@1+ (1,0) [0|3] "" Vector__XXX
 SG_ DamperStiffnessLift_TagAxle : 16|8@1+ (0.4,0) [0|100] "%" Vector__XXX
 SG_ DamperStiffnessRearAxle : 8|8@1+ (0.4,0) [0|100] "%" Vector__XXX
 SG_ DamperStiffnessFrontAxle : 0|8@1+ (0.4,0) [0|100] "%" Vector__XXX

BO_ 2566805758 ASC4: 8 Vector__XXX
 SG_ BellowPressRearAxleRight : 48|16@1+ (0.1,0) [0|6425.5] "kPa" Vector__XXX
 SG_ BellowPressRearAxleLeft : 32|16@1+ (0.1,0) [0|6425.5] "kPa" Vector__XXX
 SG_ BellowPressFrontAxleRight : 16|16@1+ (0.1,0) [0|6425.5] "kPa" Vector__XXX
 SG_ BellowPressFrontAxleLeft : 0|16@1+ (0.1,0) [0|6425.5] "kPa" Vector__XXX

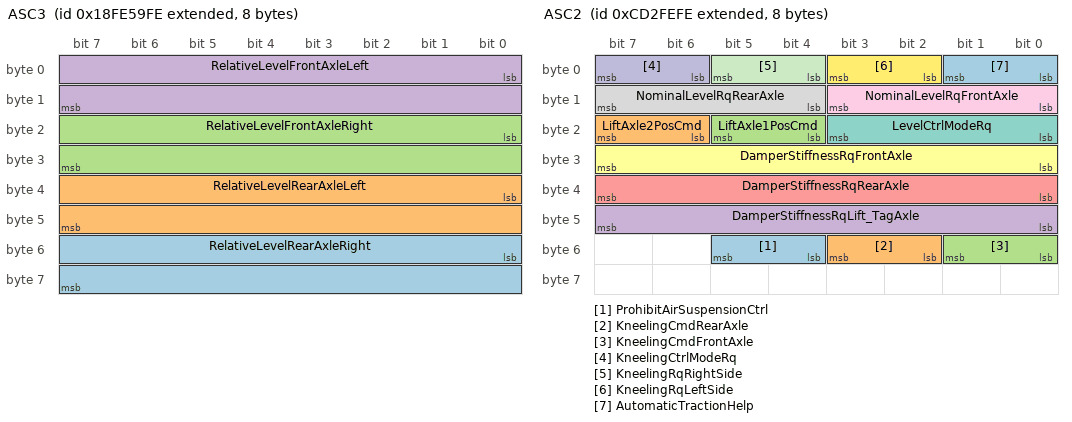
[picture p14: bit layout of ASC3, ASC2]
BO_ 2566806014 ASC3: 8 Vector__XXX
 SG_ RelativeLevelRearAxleRight : 48|16@1+ (0.1,-2800) [-2800|3225.5] "mm" Vector__XXX
 SG_ RelativeLevelRearAxleLeft : 32|16@1+ (0.1,-2800) [-2800|3225.5] "mm" Vector__XXX
 SG_ RelativeLevelFrontAxleRight : 16|16@1+ (0.1,-2800) [-2800|3225.5] "mm" Vector__XXX
 SG_ RelativeLevelFrontAxleLeft : 0|16@1+ (0.1,-2800) [-2800|3225.5] "mm" Vector__XXX

BO_ 2362638078 ASC2: 8 Vector__XXX
 SG_ ProhibitAirSuspensionCtrl : 52|2@1+ (1,0) [0|3] "" Vector__XXX
 SG_ KneelingCmdRearAxle : 50|2@1+ (1,0) [0|3] "" Vector__XXX
 SG_ KneelingCmdFrontAxle : 48|2@1+ (1,0) [0|3] "" Vector__XXX
 SG_ DamperStiffnessRqLift_TagAxle : 40|8@1+ (0.4,0) [0|100] "%" Vector__XXX
 SG_ DamperStiffnessRqRearAxle : 32|8@1+ (0.4,0) [0|100] "%" Vector__XXX
 SG_ DamperStiffnessRqFrontAxle : 24|8@1+ (0.4,0) [0|100] "%" Vector__XXX
 SG_ LevelCtrlModeRq : 16|4@1+ (1,0) [0|15] "" Vector__XXX
 SG_ NominalLevelRqRearAxle : 12|4@1+ (1,0) [0|15] "" Vector__XXX
 SG_ NominalLevelRqFrontAxle : 8|4@1+ (1,0) [0|15] "" Vector__XXX
 SG_ KneelingCtrlModeRq : 6|2@1+ (1,0) [0|3] "" Vector__XXX
 SG_ KneelingRqRightSide : 4|2@1+ (1,0) [0|3] "" Vector__XXX
 SG_ KneelingRqLeftSide : 2|2@1+ (1,0) [0|3] "" Vector__XXX
 SG_ AutomaticTractionHelp : 0|2@1+ (1,0) [0|3] "" Vector__XXX
 SG_ LiftAxle2PosCmd : 22|2@1+ (1,0) [0|3] "" Vector__XXX
 SG_ LiftAxle1PosCmd : 20|2@1+ (1,0) [0|3] "" Vector__XXX

BO_ 2365479678 ASC1: 8 Vector__XXX
 SG_ SspensionCtrlRefusalInformation : 56|4@1+ (1,0) [0|15] "" Vector__XXX
 SG_ SuspensionRemoteCtrl2 : 50|2@1+ (1,0) [0|3] "" Vector__XXX
 SG_ SuspensionRemoteCtrl1 : 48|2@1+ (1,0) [0|3] "" Vector__XXX
 SG_ RearAxleInBumperRange : 42|2@1+ (1,0) [0|3] "" Vector__XXX
 SG_ FrontAxleInBumperRange : 40|2@1+ (1,0) [0|3] "" Vector__XXX
 SG_ DoorRelease : 36|2@1+ (1,0) [0|3] "" Vector__XXX
 SG_ VehicleMotionInhibit : 34|2@1+ (1,0) [0|3] "" Vector__XXX
 SG_ SecurityDevice : 32|2@1+ (1,0) [0|3] "" Vector__XXX
 SG_ LevelCtrlMode : 28|4@1+ (1,0) [0|15] "" Vector__XXX
 SG_ KneelingInformation : 24|4@1+ (1,0) [0|15] "" Vector__XXX
 SG_ LiftingCtrlModeRearAxle : 22|2@1+ (1,0) [0|3] "" Vector__XXX
 SG_ LiftingCtrlModeFrontAxle : 20|2@1+ (1,0) [0|3] "" Vector__XXX
 SG_ LoweringCtrlModeRearAxle : 18|2@1+ (1,0) [0|3] "" Vector__XXX
 SG_ LoweringCtrlModeFrontAxle : 16|2@1+ (1,0) [0|3] "" Vector__XXX
 SG_ AboveNominalLevelRearAxle : 14|2@1+ (1,0) [0|3] "" Vector__XXX
 SG_ AboveNominalLevelFrontAxle : 12|2@1+ (1,0) [0|3] "" Vector__XXX
 SG_ BelowNominalLevelRearAxle : 10|2@1+ (1,0) [0|3] "" Vector__XXX
 SG_ BelowNominalLevelFrontAxle : 8|2@1+ (1,0) [0|3] "" Vector__XXX
 SG_ NominalLevelRearAxle : 4|4@1+ (1,0) [0|15] "" Vector__XXX
 SG_ NominalLevelFrontAxle : 0|4@1+ (1,0) [0|15] "" Vector__XXX
 SG_ LiftAxle2Pos : 46|2@1+ (1,0) [0|3] "" Vector__XXX
 SG_ LiftAxle1Pos : 38|2@1+ (1,0) [0|3] "" Vector__XXX

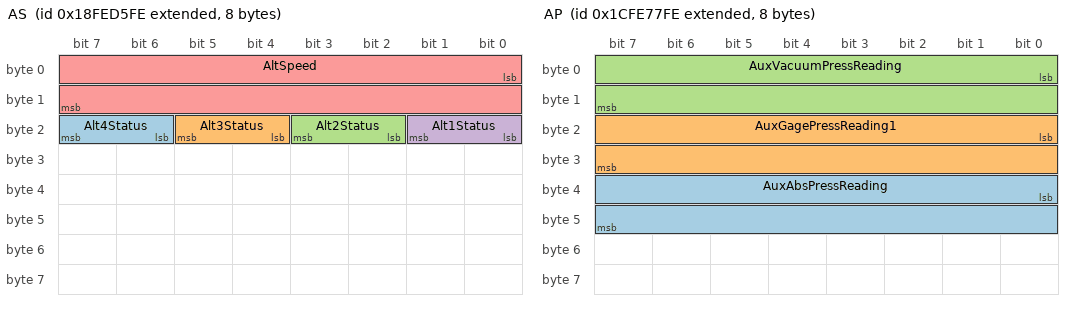
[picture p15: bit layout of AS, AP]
BO_ 2566837758 AS: 8 Vector__XXX
 SG_ Alt4Status : 22|2@1+ (1,0) [0|3] "" Vector__XXX
 SG_ Alt3Status : 20|2@1+ (1,0) [0|3] "" Vector__XXX
 SG_ Alt2Status : 18|2@1+ (1,0) [0|3] "" Vector__XXX
 SG_ Alt1Status : 16|2@1+ (1,0) [0|3] "" Vector__XXX
 SG_ AltSpeed : 0|16@1+ (0.5,0) [0|32127.5] "rpm" Vector__XXX

BO_ 2633922558 AP: 8 Vector__XXX
 SG_ AuxAbsPressReading : 32|16@1+ (0.5,0) [0|32127.5] "kPa" Vector__XXX
 SG_ AuxGagePressReading1 : 16|16@1+ (0.5,0) [0|32127.5] "kPa" Vector__XXX
 SG_ AuxVacuumPressReading : 0|16@1+ (0.5,0) [0|32127.5] "kPa" Vector__XXX

BO_ 2566775038 AMB2: 8 Vector__XXX
 SG_ SolarSensorMax : 8|8@1+ (0.4,0) [0|100] "mW/cm²" Vector__XXX
 SG_ SolarIntensityPercent : 0|8@1+ (0.4,0) [0|100] "%" Vector__XXX

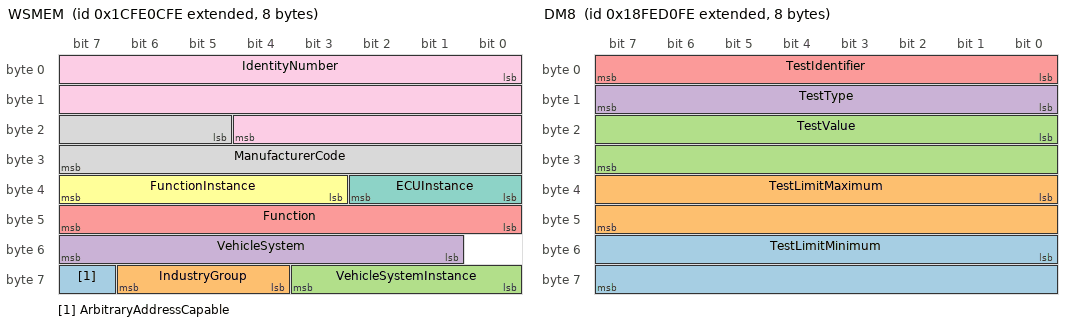
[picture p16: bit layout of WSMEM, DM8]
BO_ 2633895166 WSMEM: 8 Vector__XXX
 SG_ ArbitraryAddressCapable : 63|1@1+ (1,0) [0|1] "" Vector__XXX
 SG_ IndustryGroup : 60|3@1+ (1,0) [0|7] "" Vector__XXX
 SG_ VehicleSystemInstance : 56|4@1+ (1,0) [0|15] "" Vector__XXX
 SG_ VehicleSystem : 49|7@1+ (1,0) [0|127] "" Vector__XXX
 SG_ Function : 40|8@1+ (1,0) [0|255] "" Vector__XXX
 SG_ FunctionInstance : 35|5@1+ (1,0) [0|31] "" Vector__XXX
 SG_ ECUInstance : 32|3@1+ (1,0) [0|7] "" Vector__XXX
 SG_ ManufacturerCode : 21|11@1+ (1,0) [0|2047] "" Vector__XXX
 SG_ IdentityNumber : 0|21@1+ (1,0) [0|2097152] "" Vector__XXX

BO_ 2566836478 DM8: 8 Vector__XXX
 SG_ TestLimitMinimum : 48|16@1+ (1,0) [0|64255] "" Vector__XXX
 SG_ TestLimitMaximum : 32|16@1+ (1,0) [0|64255] "" Vector__XXX
 SG_ TestValue : 16|16@1+ (1,0) [0|64255] "" Vector__XXX
 SG_ TestType : 8|8@1+ (1,0) [1|64] "" Vector__XXX
 SG_ TestIdentifier : 0|8@1+ (1,0) [1|64] "" Vector__XXX

BO_ 2565078782 DM7: 8 Vector__XXX
 SG_ TestIdentifier : 0|8@1+ (1,0) [1|64] "" Vector__XXX

BO_ 2566836222 DM6: 22 Vector__XXX
 SG_ SPN5 : 144|16@1+ (1,0) [0|65536] "" Vector__XXX
 SG_ SPN4 : 112|16@1+ (1,0) [0|65536] "" Vector__XXX
 SG_ SPN3 : 80|16@1+ (1,0) [0|65536] "" Vector__XXX
 SG_ SPN2 : 48|16@1+ (1,0) [0|65536] "" Vector__XXX
 SG_ FailureModeIdentifier5 : 160|5@1+ (1,0) [0|0] "" Vector__XXX
 SG_ FailureModeIdentifier4 : 128|5@1+ (1,0) [0|0] "" Vector__XXX
 SG_ FlashRedStopLamp : 12|2@1+ (1,0) [0|3] "" Vector__XXX
 SG_ FlashProtectLamp : 8|2@1+ (1,0) [0|3] "" Vector__XXX
 SG_ FlashMalfuncIndicatorLamp : 14|2@1+ (1,0) [0|3] "" Vector__XXX
 SG_ FlashAmberWarningLamp : 10|2@1+ (1,0) [0|3] "" Vector__XXX
 SG_ FailureModeIdentifier3 : 96|5@1+ (1,0) [0|0] "" Vector__XXX
 SG_ FailureModeIdentifier2 : 64|5@1+ (1,0) [0|0] "" Vector__XXX
 SG_ SPNConversionMethod5 : 175|1@1+ (1,0) [0|1] "" Vector__XXX
 SG_ SPNConversionMethod4 : 143|1@1+ (1,0) [0|1] "" Vector__XXX
 SG_ SPNConversionMethod3 : 111|1@1+ (1,0) [0|1] "" Vector__XXX
 SG_ SPNConversionMethod2 : 79|1@1+ (1,0) [0|1] "" Vector__XXX
 SG_ OccurenceCount5 : 168|7@1+ (1,0) [0|126] "" Vector__XXX
 SG_ OccurenceCount4 : 136|7@1+ (1,0) [0|126] "" Vector__XXX
 SG_ OccurenceCount3 : 104|7@1+ (1,0) [0|126] "" Vector__XXX
 SG_ OccurenceCount2 : 72|7@1+ (1,0) [0|126] "" Vector__XXX
 SG_ OccurenceCount1 : 40|7@1+ (1,0) [0|126] "" Vector__XXX
 SG_ SPNConversionMethod1 : 47|1@1+ (1,0) [0|1] "" Vector__XXX
 SG_ FailureModeIdentifier1 : 32|5@1+ (1,0) [0|0] "" Vector__XXX
 SG_ SPN1 : 16|16@1+ (1,0) [0|65536] "" Vector__XXX
 SG_ MalfunctionIndicatorLampStatus : 6|2@1+ (1,0) [0|3] "" Vector__XXX
 SG_ RedStopLampState : 4|2@1+ (1,0) [0|3] "" Vector__XXX
 SG_ AmberWarningLampStatus : 2|2@1+ (1,0) [0|3] "" Vector__XXX
 SG_ ProtectLampStatus : 0|2@1+ (1,0) [0|3] "" Vector__XXX
 SG_ SPN5High : 165|3@1+ (1,0) [0|7] "" Vector__XXX
 SG_ SPN4High : 133|3@1+ (1,0) [0|7] "" Vector__XXX
 SG_ SPN3High : 101|3@1+ (1,0) [0|7] "" Vector__XXX
 SG_ SPN2High : 69|3@1+ (1,0) [0|7] "" Vector__XXX
 SG_ SPN1High : 37|3@1+ (1,0) [0|7] "" Vector__XXX

BO_ 2566835966 DM5: 8 Vector__XXX
 SG_ MisfireMonitoringSupport : 24|1@1+ (1,0) [0|0] "" Vector__XXX
 SG_ OBDCompliance : 16|8@1+ (1,0) [0|240] "" Vector__XXX
 SG_ PreviouslyActiveTroubleCodes : 8|8@1+ (1,0) [0|240] "" Vector__XXX
 SG_ ActiveTroubleCodes : 0|8@1+ (1,0) [0|240] "" Vector__XXX
 SG_ SecondAirSystemMonStatus : 51|1@1+ (1,0) [0|1] "" Vector__XXX
 SG_ EvaporativeSystemMonStatus : 50|1@1+ (1,0) [0|1] "" Vector__XXX
 SG_ ACSystemRefrigerantMonStatus : 52|1@1+ (1,0) [0|1] "" Vector__XXX
 SG_ OxygenSensorHeaterMonStatus : 54|1@1+ (1,0) [0|1] "" Vector__XXX
 SG_ OxygenSensorMonStatus : 53|1@1+ (1,0) [0|1] "" Vector__XXX
 SG_ EGRSystemMonitoringStatus : 55|1@1+ (1,0) [0|1] "" Vector__XXX
 SG_ CatalystMonStatus : 48|1@1+ (1,0) [0|1] "" Vector__XXX
 SG_ ColdStartAidSystemMonStatus : 56|1@1+ (1,0) [0|1] "" Vector__XXX
 SG_ HeatedCatalystMonStatus : 49|1@1+ (1,0) [0|0] "" Vector__XXX
 SG_ CatalystMonSupp : 32|1@1+ (1,0) [0|1] "" Vector__XXX
 SG_ ColdStartAidSystemMonSupp : 40|1@1+ (1,0) [0|1] "" Vector__XXX
 SG_ HeatedCatalystMonSupp : 33|1@1+ (1,0) [0|0] "" Vector__XXX
 SG_ EvaporativeSystemMonSupp : 34|1@1+ (1,0) [0|1] "" Vector__XXX
 SG_ SecondAirSystemMonSupp : 35|1@1+ (1,0) [0|1] "" Vector__XXX
 SG_ ACSystemRefrigerantMonSupp : 36|1@1+ (1,0) [0|1] "" Vector__XXX
 SG_ OxygenSensorMonSupp : 37|1@1+ (1,0) [0|1] "" Vector__XXX
 SG_ OxygenSensorHeaterMonSupp : 38|1@1+ (1,0) [0|1] "" Vector__XXX
 SG_ EGRSystemMonitoringSupp : 39|1@1+ (1,0) [0|1] "" Vector__XXX
 SG_ MisfireMonitoringStatus : 28|1@1+ (1,0) [0|0] "" Vector__XXX
 SG_ ComprehensiveCompMonStatus : 30|1@1+ (1,0) [0|1] "" Vector__XXX
 SG_ FuelSystemMonitoringStatus : 29|1@1+ (1,0) [0|1] "" Vector__XXX
 SG_ ComprehensiveComponentMonSupp : 26|1@1+ (1,0) [0|0] "" Vector__XXX
 SG_ FuelSystemMonitoringSupport : 25|1@1+ (1,0) [0|1] "" Vector__XXX

BO_ 2566835710 DM4: 13 Vector__XXX
 SG_ OccurenceCount1 : 32|7@1+ (1,0) [0|126] "" Vector__XXX
 SG_ SPNConversionMethod1 : 39|1@1+ (1,0) [0|1] "" Vector__XXX
 SG_ FailureModeIdentifier1 : 24|5@1+ (1,0) [0|0] "" Vector__XXX
 SG_ SPN1 : 8|16@1+ (1,0) [0|65536] "" Vector__XXX
 SG_ FreezeFrameLength : 0|8@1+ (1,0) [0|255] "byte" Vector__XXX
 SG_ EngSpeed : 56|16@1+ (0.125,0) [0|8031.875] "rpm" Vector__XXX
 SG_ EngTorqueMode : 40|4@1+ (1,0) [0|15] "" Vector__XXX
 SG_ EngTurboBoostPress : 48|8@1+ (2,0) [0|500] "kPa" Vector__XXX
 SG_ WheelBasedVehicleSpeed : 88|16@1+ (0.00390625,0) [0|250.996] "km/h" Vector__XXX
 SG_ EngPercentLoadAtCurrentSpeed : 72|8@1+ (1,0) [0|250] "%" Vector__XXX
 SG_ EngineCoolantTemperature : 80|8@1+ (1,-40) [-40|210] "°C" Vector__XXX
 SG_ SPN1High : 29|3@1+ (1,0) [0|7] "" Vector__XXX

BO_ 2566835454 DM3: 0 Vector__XXX

CM_ BO_ 2364539902 "Electronic Engine Controller 2";
CM_ SG_ 2364539902 ActMaxAvailEngPercentTorque "This is the maximum amount of torque that the engine can immediately deliver as a percentage of the reference engine torque.";
CM_ SG_ 2364539902 VhclAccelerationRateLimitStatus "Status (active or not active) of the system used to limit maximum forward vehicle acceleration.";
CM_ SG_ 2364539902 AccelPedal2LowIdleSwitch "Switch signal which indicates the state of the accelerator pedal 2 low idle switch.";
CM_ SG_ 2364539902 RoadSpeedLimitStatus "Status (active or not active) of the system used to limit maximum vehicle velocity.";
CM_ SG_ 2364539902 AccelPedalKickdownSwitch "Switch signal which indicates whether the accelerator pedal kickdown switch is opened or closed.";
CM_ SG_ 2364539902 AccelPedal1LowIdleSwitch "Switch signal which indicates the state of the accelerator pedal 1 low idle switch.";
CM_ BO_ 2364540158 "Electronic Engine Controller 1";
CM_ SG_ 2364540158 EngStarterMode "There are several phases in a starting action and different reasons why a start cannot take place.";
CM_ SG_ 2364540158 SrcAddrssOfCtrllngDvcForEngCtrl "The source address of the SAE J1939 device currently controlling the engine.";
CM_ SG_ 2364540158 EngSpeed "Actual engine speed which is calculated over a minimum crankshaft angle of 720 degrees divided by the number of cylinders.";
CM_ SG_ 2364540158 ActualEngPercentTorque "The calculated output torque of the engine.";
CM_ SG_ 2364540158 DriversDemandEngPercentTorque "The requested torque output of the engine by the driver.";
CM_ SG_ 2364540158 EngTorqueMode "State signal which indicates which engine torque mode is currently generating, limiting, or controlling the torque.";
CM_ BO_ 2566768126 "ECU Identification Information";
CM_ BO_ 2566804734 "Engine Continuous Torque & Speed Limit";
CM_ SG_ 2566804734 EngMaxContinuousTorque "Applied limit for maximum continuous engine torque.";
CM_ SG_ 2566804734 EngHghLmtThrshhldFrMnCntnsTrqFrm "Maximum allowable value for minimum continuous torque.";
CM_ SG_ 2566804734 EngLwLmtThrshldFrMxTrqueFromEng "Minimum allowable value for maximum continuous torque.";
CM_ BO_ 2566841342 "Engine Configuration";
CM_ SG_ 2566841342 SupportTSC1CtrlPurposeGroup4Of4 "This parameter indicates which TSC1 control purposes are supported in group 4 of 4.";
CM_ SG_ 2566841342 SupportTSC1CtrlPurposeGroup3Of4 "This parameter indicates which TSC1 control purposes are supported in group 3 of 4.";
CM_ SG_ 2566841342 SupportTSC1CtrlPurposeGroup2Of4 "This parameter indicates which TSC1 control purposes are supported in group 2 of 4.";
CM_ SG_ 2566841342 SupportTSC1CtrlPurposeGroup1Of4 "This parameter indicates which TSC1 control purposes are supported in group 1 of 4.";
CM_ SG_ 2566841342 EngDefaultTorqueLimit "Companion parameter to Transmission Torque Limit (SPN 1845).";
CM_ SG_ 2566841342 EngMomentOfInertia "Moment of inertia for the engine, including items driven full-time by the engine such as fuel, oil and cooling pumps.";
CM_ SG_ 2566841342 EngRqdTorqueCtrlRangeUpperLimit "The maximum engine torque that the engine will allow when operating in a torque control/limit mode.";
CM_ SG_ 2566841342 EngRqdTorqueCtrlRangeLowerLimit "The minimum engine torque that the engine will allow when operating in a torque control/limit mode.";
CM_ SG_ 2566841342 EngRqedSpeedCtrlRangeLowerLimit "The minimum engine speed that the engine will allow when operating in a speed control/limit mode.";
CM_ SG_ 2566841342 EngMxMomentaryOverrideTimeLimit "The maximum time limit allowed to override the engine's high idle speed.";
CM_ SG_ 2566841342 EngMxMmntaryOverrideSpeedPoint7 "The maximum engine speed above high idle allowed by the engine control during a momentary high idle override.";
CM_ SG_ 2566841342 EngReferenceTorque "This parameter is the 100% reference value for all defined indicated engine torque parameters.";
CM_ SG_ 2566841342 EngSpeedAtHighIdlePoint6 "Engine speed of high idle (point 6) of the engine torque map (see PGN 65251 and supporting document).";
CM_ SG_ 2566841342 EngSpeedAtPoint5 "Engine speed of point 3, 4, and 5 of the engine torque map (see PGN 65251 and supporting document).";
CM_ SG_ 2566841342 EngSpeedAtPoint4 "Engine speed of point 3, 4, and 5 of the engine torque map (see PGN 65251 and supporting document).";
CM_ SG_ 2566841342 EngSpeedAtPoint3 "Engine speed of point 3, 4, and 5 of the engine torque map (see PGN 65251 and supporting document).";
CM_ SG_ 2566841342 EngSpeedAtPoint2 "Engine speed of point 2 of the engine torque map (see PGN 65251 and supporting document).";
CM_ SG_ 2566841342 EngPercentTorqueAtIdlePoint1 "The torque limit that indicates the available engine torque which can be provided by the engine at idle speed.";
CM_ BO_ 2566767870 "Electronic Brake Controller 5";
CM_ SG_ 2566767870 XBRAccelerationLimit "The brake system may temporarily or generally limit the maximum brake performance available for external systems.";
CM_ SG_ 2566767870 XBRActiveCtrlMode "This parameter indicates which XBR Control Mode is executed by the brake system.";
CM_ SG_ 2566767870 XBRSystemState "This parameter indicates which external brake control is allowed.";
CM_ SG_ 2566767870 FoundationBrakeUse "This parameter indicates if the brake system presently uses the foundation brakes.";
CM_ SG_ 2566767870 HillHolderMode "Signal which indicates the current mode of the hill holder function.";
CM_ SG_ 2566767870 HaltBrakeMode "Signal which indicates the current mode of the halt brake function.";
CM_ BO_ 2633936126 "Wheel Brake Lining Remaining Information";
CM_ SG_ 2633936126 BrkLnngRmnngRearAxle3RightWheel "The percentage of brake lining which can still be measured for the right wheel on the rear axle #3.";
CM_ SG_ 2633936126 BrkLnngRmningRearAxle3LeftWheel "The percentage of brake lining which can still be measured for the left wheel on the rear axle #3.";
CM_ SG_ 2633936126 BrkLnngRmnngRearAxle2RightWheel "The percentage of brake lining which can still be measured for the right wheel on the rear axle #2.";
CM_ SG_ 2633936126 BrkLnngRmningRearAxle2LeftWheel "The percentage of brake lining which can still be measured for the left wheel on the rear axle #2.";
CM_ SG_ 2633936126 BrkLnngRmnngRearAxle1RightWheel "The percentage of brake lining which can still be measured for the right wheel on the rear axle #1.";
CM_ SG_ 2633936126 BrkLnngRmningRearAxle1LeftWheel "The percentage of brake lining which can still be measured for the left wheel on the rear axle #1.";
CM_ SG_ 2633936126 BrkLnngRmnngFrontAxleRightWheel "The percentage of brake lining which can still be measured for the right wheel on the front axle.";
CM_ SG_ 2633936126 BrkLnngRmningFrontAxleLeftWheel "The percentage of brake lining which can still be measured for the left wheel on the front axle.";
CM_ BO_ 2566827518 "Wheel Application Pressure High Range Information";
CM_ SG_ 2566827518 BrkAppPrssHghRngRrAxl3RghtWheel "The brake application pressure for the right wheel on the rear axle #3.";
CM_ SG_ 2566827518 BrkAppPrssHghRngRrAxl3LeftWheel "The brake application pressure for the left wheel on the rear axle #3.";
CM_ SG_ 2566827518 BrkAppPrssHghRngRrAxl2RghtWheel "The brake application pressure for the right wheel on the rear axle #2.";
CM_ SG_ 2566827518 BrkAppPrssHghRngRrAxl2LeftWheel "The brake application pressure for the left wheel on the rear axle #2.";
CM_ SG_ 2566827518 BrkAppPrssHghRngRrAxl1RghtWheel "The brake application pressure for the right wheel on the rear axle #1.";
CM_ SG_ 2566827518 BrkAppPrssHghRngRrAxl1LeftWheel "The brake application pressure for the left wheel on the rear axle #1.";
CM_ SG_ 2566827518 BrkAppPrssHghRngFrntAxlRghtWhel "The brake application pressure for the right wheel on the front axle.";
CM_ SG_ 2566827518 BrkAppPrssHghRngFrntAxlLftWheel "The brake application pressure for the left wheel on the front axle.";
CM_ BO_ 2566832126 "Wheel Speed Information";
CM_ SG_ 2566832126 RlativeSpeedRearAxle2RightWheel "The speed of the rear axle #2, right wheel relative to the front axle speed, SPN 904.";
CM_ SG_ 2566832126 RelativeSpeedRearAxle2LeftWheel "The speed of the rear axle #2, left wheel relative to the front axle speed, SPN 904.";
CM_ SG_ 2566832126 RlativeSpeedRearAxle1RightWheel "The speed of the rear axle #1, right wheel relative to the front axle speed, SPN 904.";
CM_ SG_ 2566832126 RelativeSpeedRearAxle1LeftWheel "The speed of the rear axle #1, left wheel relative to the front axle speed, SPN 904.";
CM_ SG_ 2566832126 RlativeSpeedFrontAxleRightWheel "The speed of the front axle, right wheel relative to the front axle speed, SPN 904.";
CM_ SG_ 2566832126 RelativeSpeedFrontAxleLeftWheel "The speed of the front axle, left wheel relative to the front axle speed, SPN 904.";
CM_ SG_ 2566832126 FrontAxleSpeed "The average speed of the two front wheels.";
CM_ BO_ 2565865982 "Electronic Brake Controller 1";
CM_ SG_ 2565865982 SrcAddrssOfCtrllngDvcFrBrkCntrl "The source address of the SAE J1939 device currently controlling the brake system.";
CM_ SG_ 2565865982 BrakePedalPos "Ratio of brake pedal position to maximum pedal position.";
CM_ SG_ 2565865982 TrctrMntdTrilerABSWarningSignal "This parameter commands the tractor-mounted trailer ABS optical warning signal.";
CM_ SG_ 2565865982 TrailerABSStatus "State signal which indicates that ABS in the trailer is actively controlling the brakes.";
CM_ SG_ 2565865982 HaltBrakeSwitch "Switch signal which indicates the position of the halt brake switch.";
CM_ SG_ 2565865982 ATC_ASRInformationSignal "This parameter commands the ATC/ASR driver information signal, for example a dash lamp.";
CM_ SG_ 2565865982 RemoteAccelEnableSwitch "Switch signal which indicates that the remote accelerator has been enabled and controls the engine.";
CM_ SG_ 2565865982 EngAuxEngShutdownSwitch "Switch signal which requests that all engine fueling stop.";
CM_ SG_ 2565865982 EngDerateSwitch "Switch signal used to activate the torque limiting feature of the engine.";
CM_ SG_ 2565865982 AccelInterlockSwitch "Switch signal used to disable the accelerator and remote accelerator inputs, causing the engine to return to idle.";
CM_ SG_ 2565865982 TractionCtrlOverrideSwitch "Switch signal which indicates the position of the traction control override switch.";
CM_ SG_ 2565865982 ASRHillHolderSwitch "Switch signal which indicates the position of the ASR “hill holder” switch.";
CM_ SG_ 2565865982 ASROffroadSwitch "Switch signal which indicates the position of the ASR off-road switch.";
CM_ SG_ 2565865982 ABSOffroadSwitch "Switch signal which indicates the position of the ABS off-road switch.";
CM_ SG_ 2565865982 EBSBrakeSwitch "Switch signal which indicates that the brake pedal is being pressed.";
CM_ SG_ 2565865982 AntiLockBrakingActive "State signal which indicates that the ABS is active.";
CM_ SG_ 2565865982 ASRBrakeCtrlActive "State signal which indicates that ASR brake control is active.";
CM_ SG_ 2565865982 ASREngCtrlActive "State signal which indicates that ASR engine control has been commanded to be active.";
CM_ BO_ 2565867262 "Electronic Axle Controller 1";
CM_ SG_ 2565867262 DiffLockStateCentralRear "State used which indicates the condition of the central rear differential lock.";
CM_ SG_ 2565867262 DiffLockStateCentralFront "State used which indicates the condition of the central front differential lock.";
CM_ SG_ 2565867262 DiffLockStateCentral "State used which indicates the condition of the central differential lock.";
CM_ SG_ 2565867262 DiffLockStateRearAxle2 "State used which indicates the condition of the rear axle 2 differential lock.";
CM_ SG_ 2565867262 DiffLockStateRearAxle1 "State used which indicates the condition of the rear axle 1 differential lock.";
CM_ SG_ 2565867262 DiffLockStateFrontAxle2 "State used which indicates the condition of the front axle 2 differential lock.";
CM_ SG_ 2565867262 DiffLockStateFrontAxle1 "State used which indicates the condition of the front axle 1 differential lock.";
CM_ SG_ 2565867262 Location "To identify to which of several similar devices (such as tires or fuel tanks) the information applies.";
CM_ BO_ 2566821118 "Engine Auxiliary Coolant";
CM_ SG_ 2566821118 SeaWaterPumpOutletPress "Gauge pressure of liquid found at outlet of sea water pump in sea water cooling system.";
CM_ SG_ 2566821118 EngAuxCoolantTemp "Temperature of coolant found in the intercooler which is located after the turbocharger.";
CM_ SG_ 2566821118 EngAuxCoolantPress "Gage pressure of coolant found in the intercooler which is located after the turbocharger.";
CM_ BO_ 2566810622 "Driver's Identification";
CM_ BO_ 2566847742 "Dash Display";
CM_ SG_ 2566847742 CargoAmbientTemp "Temperature of air inside vehicle container used to accommodate cargo.";
CM_ SG_ 2566847742 EngFuelFilterDiffPress "Differential pressure measured across the fuel filter located between the fuel tank and the supply pump.";
CM_ SG_ 2566847742 FuelLevel "Ratio of volume of fuel to the total volume of fuel storage container.";
CM_ SG_ 2566847742 WasherFluidLevel "Ratio of volume of liquid to total container volume of fluid reservoir in windshield wash system.";
CM_ BO_ 2566768382 "Cold Start Aids";
CM_ SG_ 2566768382 EngStartEnableDevice2Config "The start enable device installed for start enable device 2.";
CM_ SG_ 2566768382 EngStartEnableDevice1Config "The start enable device installed for start enable device 1.";
CM_ SG_ 2566768382 EngStartEnableDevice2 "Devices that assist an engine in starting, e.";
CM_ SG_ 2566768382 EngStartEnableDevice1 "Devices that assist an Engine in starting, e.";
CM_ BO_ 2566811902 "Combination Vehicle Weight";
CM_ SG_ 2566811902 PoweredVehicleWeight "Total mass imposed by the tires of the powered vehicle on the road surface.";
CM_ SG_ 2566811902 GrossCombinationVehicleWeight "The total weight of the truck and all attached trailers.";
CM_ BO_ 2563768062 "Continuous Torque & Speed Limit Request";
CM_ BO_ 2633924862 "Combustion Time 6";
CM_ SG_ 2633924862 EngAverageCombustionTime "The average combustion time of all cylinders of an engine.";
CM_ SG_ 2633924862 EngDesiredCombustionTime "The desired combustion time based upon engine load and speed lookup maps.";
CM_ BO_ 2633924606 "Combustion Time 5";
CM_ SG_ 2633924606 EngCyl20CombustionTime "The amount of time from when the ignition of the fuel is initiated to when the fuel is completely ignited (i.";
CM_ SG_ 2633924606 EngCyl19CombustionTime "The amount of time from when the ignition of the fuel is initiated to when the fuel is completely ignited (i.";
CM_ SG_ 2633924606 EngCyl18CombustionTime "The amount of time from when the ignition of the fuel is initiated to when the fuel is completely ignited (i.";
CM_ SG_ 2633924606 EngCyl17CombustionTime "The amount of time from when the ignition of the fuel is initiated to when the fuel is completely ignited (i.";
CM_ BO_ 2633924350 "Combustion Time 4";
CM_ SG_ 2633924350 EngCyl16CombustionTime "The amount of time from when the ignition of the fuel is initiated to when the fuel is completely ignited (i.";
CM_ SG_ 2633924350 EngCyl15CombustionTime "The amount of time from when the ignition of the fuel is initiated to when the fuel is completely ignited (i.";
CM_ SG_ 2633924350 EngCyl14CombustionTime "The amount of time from when the ignition of the fuel is initiated to when the fuel is completely ignited (i.";
CM_ SG_ 2633924350 EngCyl13CombustionTime "The amount of time from when the ignition of the fuel is initiated to when the fuel is completely ignited (i.";
CM_ BO_ 2633924094 "Combustion Time 3";
CM_ SG_ 2633924094 EngCyl12CombustionTime "The amount of time from when the ignition of the fuel is initiated to when the fuel is completely ignited (i.";
CM_ SG_ 2633924094 EngCyl11CombustionTime "The amount of time from when the ignition of the fuel is initiated to when the fuel is completely ignited (i.";
CM_ SG_ 2633924094 EngCyl10CombustionTime "The amount of time from when the ignition of the fuel is initiated to when the fuel is completely ignited (i.";
CM_ SG_ 2633924094 EngCyl9CombustionTime "The amount of time from when the ignition of the fuel is initiated to when the fuel is completely ignited (i.";
CM_ BO_ 2633923838 "Combustion Time 2";
CM_ SG_ 2633923838 EngCyl8CombustionTime "The amount of time from when the ignition of the fuel is initiated to when the fuel is completely ignited (i.";
CM_ SG_ 2633923838 EngCyl7CombustionTime "The amount of time from when the ignition of the fuel is initiated to when the fuel is completely ignited (i.";
CM_ SG_ 2633923838 EngCyl6CombustionTime "The amount of time from when the ignition of the fuel is initiated to when the fuel is completely ignited (i.";
CM_ SG_ 2633923838 EngCyl5CombustionTime "The amount of time from when the ignition of the fuel is initiated to when the fuel is completely ignited (i.";
CM_ BO_ 2633923582 "Combustion Time 1";
CM_ SG_ 2633923582 EngCyl4CombustionTime "The amount of time from when the ignition of the fuel is initiated to when the fuel is completely ignited (i.";
CM_ SG_ 2633923582 EngCyl3CombustionTime "The amount of time from when the ignition of the fuel is initiated to when the fuel is completely ignited (i.";
CM_ SG_ 2633923582 EngCyl2CombustionTime "The amount of time from when the ignition of the fuel is initiated to when the fuel is completely ignited (i.";
CM_ SG_ 2633923582 EngCyl1CombustionTime "The amount of time from when the ignition of the fuel is initiated to when the fuel is completely ignited (i.";
CM_ BO_ 2633878014 "Electronic Control Module Information";
CM_ SG_ 2633878014 TotalCountOfConfigChangesMade "Total number of times changes have been made to any of the configurable parameters.";
CM_ BO_ 2566771966 "Cab Message 3";
CM_ SG_ 2566771966 FifthWheelReleaseCtrl "Operator input used to release the fifth wheel.";
CM_ SG_ 2566771966 FfthWhlRlaseCtrlSecurityLockout "Operator's fifth wheel release control interlock.";
CM_ SG_ 2566771966 TransferCaseSelectorSwitch "Operator switch to select the condition of the transfer case.";
CM_ BO_ 2564882174 "Cab Message 1";
CM_ SG_ 2564882174 RqCabZoneHeating "Request to activate cab zone heating.";
CM_ SG_ 2564882174 RqEngZoneHeating "Request to activate engine zone heating.";
CM_ SG_ 2564882174 AuxHeaterModeRq "Request to activate the auxiliary heater.";
CM_ SG_ 2564882174 EngAutomaticStartEnableSwitch "Switch signal which enables the idle management system to be enabled.";
CM_ SG_ 2564882174 VhclLmtngSpdGvrnrIncrmentSwitch "Switch signal which increases the Vehicle Limiting Speed Governor (VLSG).";
CM_ SG_ 2564882174 VhclLmtngSpdGvrnrDcrementSwitch "Switch signal which decreases the Vehicle Limiting Speed Governor (VLSG).";
CM_ SG_ 2564882174 BatteryMainSwitchHoldRq "Request to hold the battery main switch.";
CM_ SG_ 2564882174 AuxHeaterCoolantPumpRq "Indicates whether to activate the auxiliary heater coolant water pump.";
CM_ SG_ 2564882174 CabInteriorTempCmd "Parameter used to command a certain cab interior temperature.";
CM_ SG_ 2564882174 RqedPercentFanSpeed "Fan speed as a ratio of the actual fan drive (current speed) to the fully engaged fan drive (maximum fan speed).";
CM_ BO_ 2563833598 "Cab Illumination Message";
CM_ BO_ 2566843390 "Component Identification";
CM_ BO_ 2566844926 "Cruise Control/Vehicle Speed";
CM_ SG_ 2566844926 EngShutdownOverrideSwitch "Switch signal which indicates the position of the engine shutdown override switch.";
CM_ SG_ 2566844926 EngTestModeSwitch "Switch signal which indicates the position of the engine test mode switch.";
CM_ SG_ 2566844926 EngIdleDecrementSwitch "Switch signal which indicates the position of the idle decrement switch.";
CM_ SG_ 2566844926 EngIdleIncrementSwitch "Switch signal which indicates the position of the idle increment switch.";
CM_ SG_ 2566844926 CruiseCtrlStates "This parameter is used to indicate the current state, or mode, of operation by the cruise control device.";
CM_ SG_ 2566844926 PTOState "This parameter is used to indicate the current state or mode of operation by the power takeoff (PTO) device.";
CM_ SG_ 2566844926 CruiseCtrlSetSpeed "Value of set (chosen) velocity of velocity control system.";
CM_ SG_ 2566844926 CruiseCtrlAccelerateSwitch "Switch signal of the cruise control activator which indicates that the activator is in the position “accelerate.";
CM_ SG_ 2566844926 CruiseCtrlResumeSwitch "Switch signal of the cruise control activator which indicates that the activator is in the position “resume.";
CM_ SG_ 2566844926 CruiseCtrlCoastSwitch "Switch signal of the cruise control activator which indicates that the activator is in the position “coast (decelerate).";
CM_ SG_ 2566844926 CruiseCtrlSetSwitch "Switch signal of the cruise control activator which indicates that the activator is in the position “set.";
CM_ SG_ 2566844926 ClutchSwitch "Switch signal which indicates that the clutch pedal is being pressed.";
CM_ SG_ 2566844926 BrakeSwitch "Switch signal which indicates that the driver operated brake foot pedal is being pressed.";
CM_ SG_ 2566844926 CruiseCtrlEnableSwitch "Switch signal which indicates that it is possible to manage the cruise control function.";
CM_ SG_ 2566844926 CruiseCtrlActive "Cruise control is switched on.";
CM_ SG_ 2566844926 WheelBasedVehicleSpeed "Speed of the vehicle as calculated from wheel or tailshaft speed.";
CM_ SG_ 2566844926 CruiseCtrlPauseSwitch "Switch signal which indicates the position of the Cruise Control Pause Switch used on Remote Cruise Control applications.";
CM_ SG_ 2566844926 ParkingBrakeSwitch "Switch signal which indicates when the parking brake is set.";
CM_ SG_ 2566844926 TwoSpeedAxleSwitch "Switch signal which indicates the current axle range.";
CM_ BO_ 2566843902 "Cruise Control/Vehicle Speed Setup";
CM_ SG_ 2566843902 CruiseCtrlHighSetLimitSpeed "Maximum vehicle velocity at which cruise can be set.";
CM_ SG_ 2566843902 MaxVehicleSpeedLimit "Maximum vehicle velocity allowed.";
CM_ BO_ 2566809598 "Climate Control Configuration";
CM_ SG_ 2566809598 AuxHeaterMaxOutputPower "The maximum output power of the auxiliary heater.";
CM_ BO_ 2633940222 "Compression/Service Brake Information";
CM_ SG_ 2633940222 TripServiceBrakeApps "Total number of times the service brakes have been activated since the last trip reset.";
CM_ SG_ 2633940222 TripServiceBrakeDistance "Total distance over which the service brakes have been active since the last trip reset.";
CM_ SG_ 2633940222 TripCompressionBrakeDistance "Total distance over which the compression brakes have been active since the last trip reset.";
CM_ SG_ 2633940222 TotalCompressionBrakeDistance "Total distance over which the compression brakes have been active for the life of the engine.";
CM_ BO_ 2566775294 "Cab A/C Climate System Information";
CM_ SG_ 2566775294 CbA_CRfrgrntCmprssorOutletPress "This is the gage pressure at the compressor outlet in the cab air conditioning system.";
CM_ BO_ 2566803710 "Battery Temperature";
CM_ SG_ 2566803710 Battery2Temp "Temperature of the battery 2.";
CM_ SG_ 2566803710 Battery1Temp "Temperature of the battery 1.";
CM_ BO_ 2566809342 "Battery Main Switch Information";
CM_ SG_ 2566809342 BatteryMainSwitchHoldState "Parameter indicating whether the battery main switch is held due to an external request or not.";
CM_ BO_ 2365446910 "Basic Joystick Message 3";
CM_ SG_ 2365446910 Joystick3XAxisDetentPosStatus "Reports when the current joystick position is in the detent position for that axis of travel.";
CM_ SG_ 2365446910 Joystick3Button9PressedStatus "Reports when the joystick button has been pressed.";
CM_ SG_ 2365446910 Joystick3Button10PressedStatus "Reports when the joystick button has been pressed.";
CM_ SG_ 2365446910 Joystick3Button11PressedStatus "Reports when the joystick button has been pressed.";
CM_ SG_ 2365446910 Joystick3Button12PressedStatus "Reports when the joystick button has been pressed.";
CM_ SG_ 2365446910 Joystick3YAxisDetentPosStatus "Reports when the current joystick position is in the detent position for that axis of travel.";
CM_ SG_ 2365446910 Joystick3YAxisPos "The position of the joystick in the relative motion of travel from the neutral position.";
CM_ SG_ 2365446910 Joystick3YAxisNeutralPosStatus "Reports when the current joystick position is in the neutral position for that axis of travel.";
CM_ SG_ 2365446910 Joystick3XAxisPos "The position of the joystick in the relative motion of travel from the neutral position.";
CM_ SG_ 2365446910 Joystick3XAxisNeutralPosStatus "Reports when the current joystick position is in the neutral position for that axis of travel.";
CM_ SG_ 2365446910 Joystick3Button5PressedStatus "Reports when the joystick button has been pressed.";
CM_ SG_ 2365446910 Joystick3Button6PressedStatus "Reports when the joystick button has been pressed.";
CM_ SG_ 2365446910 Joystick3Button7PressedStatus "Reports when the joystick button has been pressed.";
CM_ SG_ 2365446910 Joystick3Button8PressedStatus "Reports when the joystick button has been pressed.";
CM_ SG_ 2365446910 Joystick3Button1PressedStatus "Reports when the joystick button has been pressed.";
CM_ SG_ 2365446910 Joystick3Button2PressedStatus "Reports when the joystick button has been pressed.";
CM_ SG_ 2365446910 Joystick3Button3PressedStatus "Reports when the joystick button has been pressed.";
CM_ SG_ 2365446910 Joystick3Button4PressedStatus "Reports when the joystick button has been pressed.";
CM_ BO_ 2365446398 "Basic Joystick Message 2";
CM_ SG_ 2365446398 Joystick2XAxisDetentPosStatus "Reports when the current joystick position is in the detent position for that axis of travel.";
CM_ SG_ 2365446398 Joystick2YAxisDetentPosStatus "Reports when the current joystick position is in the detent position for that axis of travel.";
CM_ SG_ 2365446398 Joystick2YAxisPos "The position of the joystick in the relative motion of travel from the neutral position.";
CM_ SG_ 2365446398 Joystick2YAxisNeutralPosStatus "Reports when the current joystick position is in the neutral position for that axis of travel.";
CM_ SG_ 2365446398 Joystick2XAxisPos "The position of the joystick in the relative motion of travel from the neutral position.";
CM_ SG_ 2365446398 Joystick2XAxisNeutralPosStatus "Reports when the current joystick position is in the neutral position for that axis of travel.";
CM_ SG_ 2365446398 Joystick2Button9PressedStatus "Reports when the joystick button has been pressed.";
CM_ SG_ 2365446398 Joystick2Button10PressedStatus "Reports when the joystick button has been pressed.";
CM_ SG_ 2365446398 Joystick2Button11PressedStatus "Reports when the joystick button has been pressed.";
CM_ SG_ 2365446398 Joystick2Button12PressedStatus "Reports when the joystick button has been pressed.";
CM_ SG_ 2365446398 Joystick2Button5PressedStatus "Reports when the joystick button has been pressed.";
CM_ SG_ 2365446398 Joystick2Button6PressedStatus "Reports when the joystick button has been pressed.";
CM_ SG_ 2365446398 Joystick2Button7PressedStatus "Reports when the joystick button has been pressed.";
CM_ SG_ 2365446398 Joystick2Button8PressedStatus "Reports when the joystick button has been pressed.";
CM_ SG_ 2365446398 Joystick2Button1PressedStatus "Reports when the joystick button has been pressed.";
CM_ SG_ 2365446398 Joystick2Button2PressedStatus "Reports when the joystick button has been pressed.";
CM_ SG_ 2365446398 Joystick2Button3PressedStatus "Reports when the joystick button has been pressed.";
CM_ SG_ 2365446398 Joystick2Button4PressedStatus "Reports when the joystick button has been pressed.";
CM_ BO_ 2365445886 "Basic Joystick Message 1";
CM_ SG_ 2365445886 Joystick1XAxisDetentPosStatus "Reports when the current joystick position is in the detent position for that axis of travel.";
CM_ SG_ 2365445886 Joystick1YAxisDetentPosStatus "Reports when the current joystick position is in the detent position for that axis of travel.";
CM_ SG_ 2365445886 Joystick1YAxisPos "The position of the joystick in the relative motion of travel from the neutral position.";
CM_ SG_ 2365445886 Joystick1YAxisNeutralPosStatus "Reports when the current joystick position is in the neutral position for that axis of travel.";
CM_ SG_ 2365445886 Joystick1XAxisPos "The position of the joystick in the relative motion of travel from the neutral position.";
CM_ SG_ 2365445886 Joystick1Button9PressedStatus "Reports when the joystick button has been pressed.";
CM_ SG_ 2365445886 Joystick1Button10PressedStatus "Reports when the joystick button has been pressed.";
CM_ SG_ 2365445886 Joystick1Button11PressedStatus "Reports when the joystick button has been pressed.";
CM_ SG_ 2365445886 Joystick1Button12PressedStatus "Reports when the joystick button has been pressed.";
CM_ SG_ 2365445886 Joystick1Button5PressedStatus "Reports when the joystick button has been pressed.";
CM_ SG_ 2365445886 Joystick1Button6PressedStatus "Reports when the joystick button has been pressed.";
CM_ SG_ 2365445886 Joystick1Button7PressedStatus "Reports when the joystick button has been pressed.";
CM_ SG_ 2365445886 Joystick1Button8PressedStatus "Reports when the joystick button has been pressed.";
CM_ SG_ 2365445886 Joystick1Button1PressedStatus "Reports when the joystick button has been pressed.";
CM_ SG_ 2365445886 Joystick1Button2PressedStatus "Reports when the joystick button has been pressed.";
CM_ SG_ 2365445886 Joystick1Button3PressedStatus "Reports when the joystick button has been pressed.";
CM_ SG_ 2365445886 Joystick1Button4PressedStatus "Reports when the joystick button has been pressed.";
CM_ SG_ 2365445886 Joystick1XAxisNeutralPosStatus "Reports when the current joystick position is in the neutral position for that axis of travel.";
CM_ BO_ 2566847230 "Brakes";
CM_ SG_ 2566847230 ParkingBrakeActuator "Signal which indicates the current state of the actuator(s) that control the parking brake (see also SPN 70).";
CM_ SG_ 2566847230 BrakeSecondPress "Gage pressure of air in the secondary, or service side, of the air brake system.";
CM_ SG_ 2566847230 BrakePrimaryPress "Gage pressure of air in the primary, or supply side, of the air brake system.";
CM_ BO_ 2566848254 "Auxiliary Water Pump Pressure";
CM_ SG_ 2566848254 AuxPumpPress "Gage pressure of auxiliary water pump driven as a PTO device.";
CM_ BO_ 2566838782 "Auxiliary Input/Output Status";
CM_ SG_ 2566838782 AuxI_OChannel2 "Auxiliary channel of data (16 bit) read by the ECU.";
CM_ SG_ 2566838782 AuxI_OChannel1 "Auxiliary channel of data (16 bit) read by the ECU.";
CM_ SG_ 2566838782 AuxI_O13 "Identifies the current status of auxiliary input/output functions that are configured uniquely per application.";
CM_ SG_ 2566838782 AuxI_O14 "Identifies the current status of auxiliary input/output functions that are configured uniquely per application.";
CM_ SG_ 2566838782 AuxI_O15 "Identifies the current status of auxiliary input/output functions that are configured uniquely per application.";
CM_ SG_ 2566838782 AuxI_O16 "Identifies the current status of auxiliary input/output functions that are configured uniquely per application.";
CM_ SG_ 2566838782 AuxI_O09 "Identifies the current status of auxiliary input/output functions that are configured uniquely per application.";
CM_ SG_ 2566838782 AuxI_O10 "Identifies the current status of auxiliary input/output functions that are configured uniquely per application.";
CM_ SG_ 2566838782 AuxI_O11 "Identifies the current status of auxiliary input/output functions that are configured uniquely per application.";
CM_ SG_ 2566838782 AuxI_O12 "Identifies the current status of auxiliary input/output functions that are configured uniquely per application.";
CM_ SG_ 2566838782 AuxI_O05 "Identifies the current status of auxiliary input/output functions that are configured uniquely per application.";
CM_ SG_ 2566838782 AuxI_O06 "Identifies the current status of auxiliary input/output functions that are configured uniquely per application.";
CM_ SG_ 2566838782 AuxI_O07 "Identifies the current status of auxiliary input/output functions that are configured uniquely per application.";
CM_ SG_ 2566838782 AuxI_O08 "Identifies the current status of auxiliary input/output functions that are configured uniquely per application.";
CM_ SG_ 2566838782 AuxI_O01 "Identifies the current status of auxiliary input/output functions that are configured uniquely per application.";
CM_ SG_ 2566838782 AuxI_O02 "Identifies the current status of auxiliary input/output functions that are configured uniquely per application.";
CM_ SG_ 2566838782 AuxI_O03 "Identifies the current status of auxiliary input/output functions that are configured uniquely per application.";
CM_ SG_ 2566838782 AuxI_O04 "Identifies the current status of auxiliary input/output functions that are configured uniquely per application.";
CM_ BO_ 2631728894 "Anti-theft Status";
CM_ SG_ 2631728894 AntitheftRandomNumber "A seven byte random numeric code provided by the component in response to an anti-theft request.";
CM_ SG_ 2631728894 AntitheftComponentStatusStates "Indicates whether or not the component can be started.";
CM_ SG_ 2631728894 AntthftEncryptnSdPrsntIndicator "Indicates the presence of the encryption seed random number.";
CM_ SG_ 2631728894 AntitheftPwdValidIndicator "Indicates the presence of a validated password.";
CM_ BO_ 2631794430 "Anti-theft Request";
CM_ SG_ 2631794430 AntitheftPasswordRepresentation "This parameter is the seven byte numeric code (i.";
CM_ SG_ 2631794430 AntitheftCmdStates "This parameter is used to identify the specific requests being sent to the component.";
CM_ BO_ 2566763006 "After Treatment Intake Gas 2-b";
CM_ SG_ 2566763006 ParticulateTrapIntakeGasTemp "Temperature of engine combustion byproducts entering the particulate trap.";
CM_ SG_ 2566763006 ExhaustGasTemp1 "The reading from the exhaust gas temperature sensor located farthest upstream in the after-treatment system.";
CM_ BO_ 2633934846 "Alternator Temperature";
CM_ SG_ 2633934846 EngAltWinding3Temp "Temperature of the windings inside the alternator.";
CM_ SG_ 2633934846 EngAltWinding2Temp "Temperature of the windings inside the alternator.";
CM_ SG_ 2633934846 EngAltWinding1Temp "Temperature of the windings inside the alternator.";
CM_ SG_ 2633934846 EngAltBearing2Temp "Temperature of the bearing inside the alternator.";
CM_ SG_ 2633934846 EngAltBearing1Temp "Temperature of the bearing inside the alternator.";
CM_ BO_ 2362572542 "Air Suspension Control 6";
CM_ SG_ 2362572542 LevelPresetRearAxleRight "Set value for nominal level 'preset level' at the right side of the rear axle.";
CM_ SG_ 2362572542 LevelPresetRearAxleLeft "Set value for nominal level 'preset level' at the left side of the rear axle.";
CM_ SG_ 2362572542 LevelPresetFrontAxleRight "Set value for nominal level 'preset level' at the right side of the front axle.";
CM_ SG_ 2362572542 LevelPresetFrontAxleLeft "Set value for nominal level 'preset level' at the left side of the front axle.";
CM_ BO_ 2365478910 "Air Suspension Control 5";
CM_ SG_ 2365478910 ElctrncShckAbsrbrCtrlMdLft_TgAxl "Signal which indicates the current mode of operation of the electronic shock absorber control at the lift/tag axle.";
CM_ SG_ 2365478910 ElctrncShckAbsrbrCtrlMdRearAxle "Signal which indicates the current mode of operation of the electronic shock absorber control at the rear axle.";
CM_ SG_ 2365478910 ElctrncShckAbsrbrCtrlMdFrntAxle "Signal which indicates the current mode of operation of the electronic shock absorber control at the front axle.";
CM_ BO_ 2566805758 "Air Suspension Control 4";
CM_ BO_ 2566806014 "Air Suspension Control 3";
CM_ SG_ 2566806014 RelativeLevelRearAxleRight "Information of the height at the left side of the rear axle referred to normal level 1.";
CM_ SG_ 2566806014 RelativeLevelRearAxleLeft "Information of the height at the left side of the rear axle referred to normal level 1.";
CM_ SG_ 2566806014 RelativeLevelFrontAxleRight "Information of the height at the right side of the front axle referred to normal level 1.";
CM_ SG_ 2566806014 RelativeLevelFrontAxleLeft "Information of the height at the left side of the front axle referred to normal level 1.";
CM_ BO_ 2362638078 "Air Suspension Control 2";
CM_ SG_ 2362638078 ProhibitAirSuspensionCtrl "This parameter contains an external request to prohibit all air suspension control.";
CM_ SG_ 2362638078 KneelingCmdRearAxle "Command signal to activate the kneeling functionality at the rear axle of the vehicle.";
CM_ SG_ 2362638078 DamperStiffnessRqRearAxle "Demand value for the shock absorber control at the rear axle.";
CM_ SG_ 2362638078 DamperStiffnessRqFrontAxle "Demand value for the shock absorber control at the front axle.";
CM_ SG_ 2362638078 NominalLevelRqRearAxle "Command signal to activate a level of the rear axle programmed and/or memorised in the ECU.";
CM_ SG_ 2362638078 LiftAxle2PosCmd "Signal to command the position / load condition of lift / tag axle #2.";
CM_ SG_ 2362638078 LiftAxle1PosCmd "Signal to command the position/load condition of lift/tag axle #1.";
CM_ BO_ 2365479678 "Air Suspension Control 1";
CM_ SG_ 2365479678 SspensionCtrlRefusalInformation "Signal which indicates that the air suspension control cannot perform a request due to the operating conditions.";
CM_ SG_ 2365479678 SuspensionRemoteCtrl2 "Signal which indicates that the suspension system is controlled by remote control #2.";
CM_ SG_ 2365479678 SuspensionRemoteCtrl1 "Signal which indicates that the suspension system is controlled by remote control #1.";
CM_ SG_ 2365479678 RearAxleInBumperRange "Signal which indicates that the vehicle height at the rear axle (SPNs 1723 and 1724) is within the bumper range.";
CM_ SG_ 2365479678 FrontAxleInBumperRange "Signal which indicates that the vehicle height at the front axle (SPNs 1721 and 1722) is within the bumper range.";
CM_ SG_ 2365479678 DoorRelease "Signal which indicates that the doors may be opened.";
CM_ SG_ 2365479678 VehicleMotionInhibit "Signal which indicates whether vehicle motion is inhibited.";
CM_ SG_ 2365479678 SecurityDevice "The signal which indicates the status of the security device.";
CM_ SG_ 2365479678 AboveNominalLevelRearAxle "Signal which indicates whether the actual height of the rear axle is above the nominal (desired) level of the rear axle.";
CM_ SG_ 2365479678 AboveNominalLevelFrontAxle "Signal which indicates whether the actual height of the front axle is above the nominal (desired) level of the front axle.";
CM_ SG_ 2365479678 BelowNominalLevelRearAxle "Signal which indicates whether the actual height of the rear axle is below the nominal (desired) level for the rear axle.";
CM_ SG_ 2365479678 BelowNominalLevelFrontAxle "Signal which indicates whether the actual height of the front axle is below the nominal (desired) level for the front axle.";
CM_ SG_ 2365479678 NominalLevelRearAxle "Signal which indicates the nominal (desired) height of the rear axle to be controlled by the suspension system.";
CM_ SG_ 2365479678 NominalLevelFrontAxle "Signal which indicates the nominal (desired) height of the front axle to be controlled by the suspension system.";
CM_ SG_ 2365479678 LiftAxle2Pos "Signal which indicates the position / load condition of lift axle / tag axle #2.";
CM_ SG_ 2365479678 LiftAxle1Pos "Signal which indicates the position / load condition of lift axle / tag axle #1.";
CM_ BO_ 2566837758 "Alternator Information";
CM_ SG_ 2566837758 Alt4Status "Alternator 4 operating status.";
CM_ SG_ 2566837758 Alt3Status "Alternator 3 operating status.";
CM_ SG_ 2566837758 Alt2Status "Alternator 2 operating status.";
CM_ SG_ 2566837758 Alt1Status "Alternator 1 operating status.";
CM_ SG_ 2566837758 AltSpeed "Actual rotation speed of the alternator.";
CM_ BO_ 2633922558 "Auxiliary Pressures";
CM_ SG_ 2633922558 AuxAbsPressReading "Identifies the current absolute pressure (relative to 0 pressure) that is configured uniquely per application.";
CM_ SG_ 2633922558 AuxGagePressReading1 "Identifies the current gage pressure (relative to atmosphere) that is configured uniquely per application.";
CM_ SG_ 2633922558 AuxVacuumPressReading "Identifies the current vacuum pressure (relative to atmosphere) that is configured uniquely per application.";
CM_ BO_ 2566775038 "Ambient Conditions 2";
CM_ SG_ 2566775038 SolarSensorMax "This is the maximum value which can be reported by the sensor for the solar intensity.";
CM_ SG_ 2566775038 SolarIntensityPercent "This is the solar radiation (power density) falling on the vehicle in percent of the maximum sensor value (SPN 2611).";
CM_ BO_ 2633895166 "Working Set Member";
CM_ BO_ 2566836478 "Test results for non-continously monitored systems.";
CM_ SG_ 2566836478 TestLimitMinimum "The threshold which the test value must be above to pass the test.";
CM_ SG_ 2566836478 TestLimitMaximum "The threshold which the test value must be below to pass the test.";
CM_ SG_ 2566836478 TestValue "The test value collected during the test.";
CM_ SG_ 2566836478 TestType "Identifies the non-continously monitored component identifier that was tested.";
CM_ SG_ 2566836478 TestIdentifier "Designates the test to be run.";
CM_ BO_ 2565078782 "Command non-continously monitored test";
CM_ SG_ 2565078782 TestIdentifier "Designates the test to be run.";
CM_ BO_ 2566836222 "Continously monitored systems test results";
CM_ SG_ 2566836222 SPN5 "SPN #5 (Conversion Version 4)";
CM_ SG_ 2566836222 SPN4 "SPN #4 (Conversion Version 4)";
CM_ SG_ 2566836222 SPN3 "SPN #3 (Conversion Version 4)";
CM_ SG_ 2566836222 SPN2 "SPN #2 (Conversion Version 4)";
CM_ SG_ 2566836222 FailureModeIdentifier5 "The FMI defines the type of failure detected in the subsystem identified by an SPN.";
CM_ SG_ 2566836222 FailureModeIdentifier4 "The FMI defines the type of failure detected in the subsystem identified by an SPN.";
CM_ SG_ 2566836222 FlashRedStopLamp "This parameter provides the capability to flash the RSL (SPN 3039).";
CM_ SG_ 2566836222 FlashProtectLamp "This parameter provides the capability to flash the engine protect lamp (SPN 3041).";
CM_ SG_ 2566836222 FlashMalfuncIndicatorLamp "This parameter provides the capability to flash the MIL (SPN 3038).";
CM_ SG_ 2566836222 FlashAmberWarningLamp "This parameter provides the capability to flash the AWL (SPN 3040). ";
CM_ SG_ 2566836222 FailureModeIdentifier3 "The FMI defines the type of failure detected in the subsystem identified by an SPN.";
CM_ SG_ 2566836222 FailureModeIdentifier2 "The FMI defines the type of failure detected in the subsystem identified by an SPN.";
CM_ SG_ 2566836222 OccurenceCount5 "The 7 bit occurence count field contains the number of times a fault has gone from active to previously active.";
CM_ SG_ 2566836222 OccurenceCount4 "The 7 bit occurence count field contains the number of times a fault has gone from active to previously active.";
CM_ SG_ 2566836222 OccurenceCount3 "The 7 bit occurence count field contains the number of times a fault has gone from active to previously active.";
CM_ SG_ 2566836222 OccurenceCount2 "The 7 bit occurence count field contains the number of times a fault has gone from active to previously active.";
CM_ SG_ 2566836222 OccurenceCount1 "The 7 bit occurence count field contains the number of times a fault has gone from active to previously active.";
CM_ SG_ 2566836222 FailureModeIdentifier1 "The FMI defines the type of failure detected in the subsystem identified by an SPN.";
CM_ SG_ 2566836222 SPN1 "SPN #1 (Conversion Version 4)";
CM_ SG_ 2566836222 MalfunctionIndicatorLampStatus "A lamp used to relay only emissions-related trouble code information.";
CM_ SG_ 2566836222 RedStopLampState "This lamp is uesed to relay trouble code information that is of a severe enought condition that it warrants stopping the vehicle.";
CM_ SG_ 2566836222 AmberWarningLampStatus "This lamp is used to relay trouble code information that is reporting a problem with the vehicle system but the vehicle need
not be immediately stopped.";
CM_ SG_ 2566836222 ProtectLampStatus "This lamp is used to relay trouble code informatio that is reporting a problem with a vehicle system that is most
probably not electronic subsystem related.";
CM_ SG_ 2566836222 SPN5High "SPN #5 (Conversion Version 4)";
CM_ SG_ 2566836222 SPN4High "SPN #4 (Conversion Version 4)";
CM_ SG_ 2566836222 SPN3High "SPN #3 (Conversion Version 4)";
CM_ SG_ 2566836222 SPN2High "SPN #2 (Conversion Version 4)";
CM_ SG_ 2566836222 SPN1High "SPN #1 (Conversion Version 4)";
CM_ BO_ 2566835966 "Diagnostic readiness 1";
CM_ SG_ 2566835966 OBDCompliance "Identifies the OBD compliance capabilityof the responding controller.";
CM_ SG_ 2566835966 PreviouslyActiveTroubleCodes "Identifies the number of previously active trouble codes that are present in a specific controller.";
CM_ SG_ 2566835966 ActiveTroubleCodes "Identifies the number of active trouble codes that are present in a specific controller.";
CM_ BO_ 2566835710 "Freeze frame parameters";
CM_ SG_ 2566835710 OccurenceCount1 "The 7 bit occurence count field contains the number of times a fault has gone from active to previously active.";
CM_ SG_ 2566835710 FailureModeIdentifier1 "The FMI defines the type of failure detected in the subsystem identified by an SPN.";
CM_ SG_ 2566835710 SPN1 "SPN #1 (Conversion Version 4)";
CM_ SG_ 2566835710 FreezeFrameLength "The freeze frame length shall be equal to the number of bytes in the required parameters plus the number of bytes in the
manufacturer specific parameters.";
CM_ SG_ 2566835710 EngSpeed "Actual engine speed which is calculated over a minimum crankshaft angle of 720 degrees divided by the number of cylinders.";
CM_ SG_ 2566835710 EngTorqueMode "State signal which indicates which engine torque mode is currently generating, limiting, or controlling the torque.";
CM_ SG_ 2566835710 EngTurboBoostPress "Gage pressure of air measured downstream on the compressor discharge side of the turbocharger.";
CM_ SG_ 2566835710 WheelBasedVehicleSpeed "Speed of the vehicle as calculated from wheel or tailshaft speed.";
CM_ SG_ 2566835710 SPN1High "SPN #1 (Conversion Version 4)";
CM_ BO_ 2566835454 "Diagnostic data clear/reset of previously active DTCs.";
BA_DEF_ BO_  "FrameFormat" ENUM  "StandardCAN","ExtendedCAN","reserved","J1939PG";
BA_DEF_ SG_  "SigType" STRING ;
BA_DEF_ SG_  "SPN" INT 0 524287;
BA_DEF_ BO_  "GenMsgRequestable" INT 0 1;
BA_DEF_ BO_  "GenMsgSendType" ENUM  "cyclic","spontan","cyclicIfActive","spontanWithDelay","cyclicAndSpontan","cyclicAndSpontanWithDelay","spontanWithRepetition","cyclicIfActiveAndSpontanWD","noMsgSendType";
BA_DEF_ BO_  "VFrameFormat" ENUM  "StandardCAN","ExtendedCAN","reserved","J1939PG";
BA_DEF_ BO_  "GenMsgCycleTime" INT 0 3600000;
BA_DEF_DEF_  "FrameFormat" "J1939PG";
BA_DEF_DEF_  "SigType" "";
BA_DEF_DEF_  "SPN" 0;
BA_DEF_DEF_  "GenMsgRequestable" 1;
BA_DEF_DEF_  "GenMsgSendType" "noMsgSendType";
BA_DEF_DEF_  "VFrameFormat" "J1939PG";
BA_DEF_DEF_  "GenMsgCycleTime" 0;
BA_ "GenMsgSendType" BO_ 2364539902 0;
BA_ "GenMsgCycleTime" BO_ 2364539902 50;
BA_ "GenMsgSendType" BO_ 2364540158 0;
BA_ "GenMsgCycleTime" BO_ 2364540158 100;
BA_ "GenMsgSendType" BO_ 2566804734 0;
BA_ "GenMsgCycleTime" BO_ 2566804734 5000;
BA_ "GenMsgSendType" BO_ 2566767870 0;
BA_ "GenMsgCycleTime" BO_ 2566767870 100;
BA_ "GenMsgSendType" BO_ 2566827518 0;
BA_ "GenMsgCycleTime" BO_ 2566827518 100;
BA_ "GenMsgSendType" BO_ 2566832126 0;
BA_ "GenMsgCycleTime" BO_ 2566832126 100;
BA_ "GenMsgSendType" BO_ 2565865982 0;
BA_ "GenMsgCycleTime" BO_ 2565865982 100;
BA_ "GenMsgSendType" BO_ 2565867262 0;
BA_ "GenMsgCycleTime" BO_ 2565867262 500;
BA_ "GenMsgSendType" BO_ 2566821118 0;
BA_ "GenMsgCycleTime" BO_ 2566821118 500;
BA_ "GenMsgSendType" BO_ 2566847742 0;
BA_ "GenMsgCycleTime" BO_ 2566847742 1000;
BA_ "GenMsgSendType" BO_ 2563768062 0;
BA_ "GenMsgCycleTime" BO_ 2563768062 5000;
BA_ "GenMsgSendType" BO_ 2564882174 0;
BA_ "GenMsgCycleTime" BO_ 2564882174 1000;
BA_ "GenMsgSendType" BO_ 2566844926 0;
BA_ "GenMsgCycleTime" BO_ 2566844926 100;
BA_ "GenMsgSendType" BO_ 2566775294 0;
BA_ "GenMsgCycleTime" BO_ 2566775294 1000;
BA_ "GenMsgSendType" BO_ 2566803710 0;
BA_ "GenMsgCycleTime" BO_ 2566803710 1000;
BA_ "GenMsgSendType" BO_ 2566809342 0;
BA_ "GenMsgCycleTime" BO_ 2566809342 1000;
BA_ "GenMsgSendType" BO_ 2365446910 0;
BA_ "GenMsgCycleTime" BO_ 2365446910 100;
BA_ "GenMsgSendType" BO_ 2365446398 0;
BA_ "GenMsgCycleTime" BO_ 2365446398 100;
BA_ "GenMsgSendType" BO_ 2365445886 0;
BA_ "GenMsgCycleTime" BO_ 2365445886 100;
BA_ "GenMsgSendType" BO_ 2566847230 0;
BA_ "GenMsgCycleTime" BO_ 2566847230 1000;
BA_ "GenMsgSendType" BO_ 2566848254 0;
BA_ "GenMsgCycleTime" BO_ 2566848254 1000;
BA_ "GenMsgSendType" BO_ 2566763006 0;
BA_ "GenMsgCycleTime" BO_ 2566763006 500;
BA_ "GenMsgSendType" BO_ 2633934846 0;
BA_ "GenMsgCycleTime" BO_ 2633934846 1000;
BA_ "GenMsgSendType" BO_ 2362572542 2;
BA_ "GenMsgCycleTime" BO_ 2362572542 100;
BA_ "GenMsgSendType" BO_ 2365478910 0;
BA_ "GenMsgCycleTime" BO_ 2365478910 100;
BA_ "GenMsgSendType" BO_ 2566805758 0;
BA_ "GenMsgCycleTime" BO_ 2566805758 100;
BA_ "GenMsgSendType" BO_ 2566806014 0;
BA_ "GenMsgCycleTime" BO_ 2566806014 100;
BA_ "GenMsgSendType" BO_ 2362638078 0;
BA_ "GenMsgCycleTime" BO_ 2362638078 100;
BA_ "GenMsgSendType" BO_ 2365479678 0;
BA_ "GenMsgCycleTime" BO_ 2365479678 100;
BA_ "GenMsgSendType" BO_ 2566837758 0;
BA_ "GenMsgCycleTime" BO_ 2566837758 1000;
BA_ "GenMsgSendType" BO_ 2566775038 0;
BA_ "GenMsgCycleTime" BO_ 2566775038 1000;
BA_ "SigType" SG_ 2364539902 ActMaxAvailEngPercentTorque "RANGE";
BA_ "SPN" SG_ 2364539902 ActMaxAvailEngPercentTorque 3357;
BA_ "SigType" SG_ 2364539902 AccelPedalPos2 "RANGE";
BA_ "SPN" SG_ 2364539902 AccelPedalPos2 29;
BA_ "SigType" SG_ 2364539902 VhclAccelerationRateLimitStatus "DISCRETE";
BA_ "SPN" SG_ 2364539902 VhclAccelerationRateLimitStatus 2979;
BA_ "SigType" SG_ 2364539902 EngPercentLoadAtCurrentSpeed "RANGE";
BA_ "SPN" SG_ 2364539902 EngPercentLoadAtCurrentSpeed 92;
BA_ "SigType" SG_ 2364539902 AccelPedal2LowIdleSwitch "DISCRETE";
BA_ "SPN" SG_ 2364539902 AccelPedal2LowIdleSwitch 2970;
BA_ "SigType" SG_ 2364539902 RoadSpeedLimitStatus "DISCRETE";
BA_ "SPN" SG_ 2364539902 RoadSpeedLimitStatus 1437;
BA_ "SigType" SG_ 2364539902 AccelPedalKickdownSwitch "DISCRETE";
BA_ "SPN" SG_ 2364539902 AccelPedalKickdownSwitch 559;
BA_ "SigType" SG_ 2364539902 AccelPedal1LowIdleSwitch "DISCRETE";
BA_ "SPN" SG_ 2364539902 AccelPedal1LowIdleSwitch 558;
BA_ "SigType" SG_ 2364539902 RemoteAccelPedalPos "RANGE";
BA_ "SPN" SG_ 2364539902 RemoteAccelPedalPos 974;
BA_ "SigType" SG_ 2364539902 AccelPedalPos1 "RANGE";
BA_ "SPN" SG_ 2364539902 AccelPedalPos1 91;
BA_ "SigType" SG_ 2364540158 EngDemandPercentTorque "RANGE";
BA_ "SPN" SG_ 2364540158 EngDemandPercentTorque 2432;
BA_ "SigType" SG_ 2364540158 EngStarterMode "DISCRETE";
BA_ "SPN" SG_ 2364540158 EngStarterMode 1675;
BA_ "SigType" SG_ 2364540158 SrcAddrssOfCtrllngDvcForEngCtrl "RANGE";
BA_ "SPN" SG_ 2364540158 SrcAddrssOfCtrllngDvcForEngCtrl 1483;
BA_ "SigType" SG_ 2364540158 EngSpeed "RANGE";
BA_ "SPN" SG_ 2364540158 EngSpeed 190;
BA_ "SigType" SG_ 2364540158 ActualEngPercentTorque "RANGE";
BA_ "SPN" SG_ 2364540158 ActualEngPercentTorque 513;
BA_ "SigType" SG_ 2364540158 DriversDemandEngPercentTorque "RANGE";
BA_ "SPN" SG_ 2364540158 DriversDemandEngPercentTorque 512;
BA_ "SigType" SG_ 2364540158 EngTorqueMode "DISCRETE";
BA_ "SPN" SG_ 2364540158 EngTorqueMode 899;
BA_ "SigType" SG_ 2566804734 EngMinContinuousTorque "RANGE";
BA_ "SPN" SG_ 2566804734 EngMinContinuousTorque 1775;
BA_ "SigType" SG_ 2566804734 EngMaxContinuousTorque "RANGE";
BA_ "SPN" SG_ 2566804734 EngMaxContinuousTorque 1774;
BA_ "SigType" SG_ 2566804734 EngMinContinuousRPM "RANGE";
BA_ "SPN" SG_ 2566804734 EngMinContinuousRPM 1773;
BA_ "SigType" SG_ 2566804734 EngMaxContinuousRPM "RANGE";
BA_ "SPN" SG_ 2566804734 EngMaxContinuousRPM 1772;
BA_ "SigType" SG_ 2566804734 EngHghLmtThrshhldFrMnCntnsTrqFrm "RANGE";
BA_ "SPN" SG_ 2566804734 EngHghLmtThrshhldFrMnCntnsTrqFrm 1771;
BA_ "SigType" SG_ 2566804734 EngLwLmtThrshldFrMxTrqueFromEng "RANGE";
BA_ "SPN" SG_ 2566804734 EngLwLmtThrshldFrMxTrqueFromEng 1770;
BA_ "SigType" SG_ 2566804734 EngHghLmtThrshhldFrMnCntnsEngRPM "RANGE";
BA_ "SPN" SG_ 2566804734 EngHghLmtThrshhldFrMnCntnsEngRPM 1769;
BA_ "SigType" SG_ 2566804734 EngLwLmtThrshhldFrMaxRPMFromEng "RANGE";
BA_ "SPN" SG_ 2566804734 EngLwLmtThrshhldFrMaxRPMFromEng 1768;
BA_ "SigType" SG_ 2566841342 SupportTSC1CtrlPurposeGroup4Of4 "RANGE";
BA_ "SPN" SG_ 2566841342 SupportTSC1CtrlPurposeGroup4Of4 3348;
BA_ "SigType" SG_ 2566841342 SupportVariableRateTSC1Message "RANGE";
BA_ "SPN" SG_ 2566841342 SupportVariableRateTSC1Message 3344;
BA_ "SigType" SG_ 2566841342 SupportTSC1CtrlPurposeGroup3Of4 "RANGE";
BA_ "SPN" SG_ 2566841342 SupportTSC1CtrlPurposeGroup3Of4 3347;
BA_ "SigType" SG_ 2566841342 SupportTSC1CtrlPurposeGroup2Of4 "RANGE";
BA_ "SPN" SG_ 2566841342 SupportTSC1CtrlPurposeGroup2Of4 3346;
BA_ "SigType" SG_ 2566841342 SupportTSC1CtrlPurposeGroup1Of4 "RANGE";
BA_ "SPN" SG_ 2566841342 SupportTSC1CtrlPurposeGroup1Of4 3345;
BA_ "SigType" SG_ 2566841342 EngDefaultTorqueLimit "RANGE";
BA_ "SPN" SG_ 2566841342 EngDefaultTorqueLimit 1846;
BA_ "SigType" SG_ 2566841342 EngMomentOfInertia "RANGE";
BA_ "SPN" SG_ 2566841342 EngMomentOfInertia 1794;
BA_ "SigType" SG_ 2566841342 EngExRngRqdSpdCtrlRngUpperLimit "RANGE";
BA_ "SPN" SG_ 2566841342 EngExRngRqdSpdCtrlRngUpperLimit 1712;
BA_ "SigType" SG_ 2566841342 EngRqdTorqueCtrlRangeUpperLimit "RANGE";
BA_ "SPN" SG_ 2566841342 EngRqdTorqueCtrlRangeUpperLimit 538;
BA_ "SigType" SG_ 2566841342 EngRqdTorqueCtrlRangeLowerLimit "RANGE";
BA_ "SPN" SG_ 2566841342 EngRqdTorqueCtrlRangeLowerLimit 537;
BA_ "SigType" SG_ 2566841342 EngRqedSpeedCtrlRangeUpperLimit "RANGE";
BA_ "SPN" SG_ 2566841342 EngRqedSpeedCtrlRangeUpperLimit 536;
BA_ "SigType" SG_ 2566841342 EngRqedSpeedCtrlRangeLowerLimit "RANGE";
BA_ "SPN" SG_ 2566841342 EngRqedSpeedCtrlRangeLowerLimit 535;
BA_ "SigType" SG_ 2566841342 EngMxMomentaryOverrideTimeLimit "RANGE";
BA_ "SPN" SG_ 2566841342 EngMxMomentaryOverrideTimeLimit 534;
BA_ "SigType" SG_ 2566841342 EngMxMmntaryOverrideSpeedPoint7 "RANGE";
BA_ "SPN" SG_ 2566841342 EngMxMmntaryOverrideSpeedPoint7 533;
BA_ "SigType" SG_ 2566841342 EngReferenceTorque "RANGE";
BA_ "SPN" SG_ 2566841342 EngReferenceTorque 544;
BA_ "SigType" SG_ 2566841342 EngSpeedAtHighIdlePoint6 "RANGE";
BA_ "SPN" SG_ 2566841342 EngSpeedAtHighIdlePoint6 532;
BA_ "SigType" SG_ 2566841342 EngGainOfEndspeedGovernor "RANGE";
BA_ "SPN" SG_ 2566841342 EngGainOfEndspeedGovernor 545;
BA_ "SigType" SG_ 2566841342 EngPercentTorqueAtPoint5 "RANGE";
BA_ "SPN" SG_ 2566841342 EngPercentTorqueAtPoint5 543;
BA_ "SigType" SG_ 2566841342 EngSpeedAtPoint5 "RANGE";
BA_ "SPN" SG_ 2566841342 EngSpeedAtPoint5 531;
BA_ "SigType" SG_ 2566841342 EngPercentTorqueAtPoint4 "RANGE";
BA_ "SPN" SG_ 2566841342 EngPercentTorqueAtPoint4 542;
BA_ "SigType" SG_ 2566841342 EngSpeedAtPoint4 "RANGE";
BA_ "SPN" SG_ 2566841342 EngSpeedAtPoint4 530;
BA_ "SigType" SG_ 2566841342 EngPercentTorqueAtPoint3 "RANGE";
BA_ "SPN" SG_ 2566841342 EngPercentTorqueAtPoint3 541;
BA_ "SigType" SG_ 2566841342 EngSpeedAtPoint3 "RANGE";
BA_ "SPN" SG_ 2566841342 EngSpeedAtPoint3 529;
BA_ "SigType" SG_ 2566841342 EngPercentTorqueAtPoint2 "RANGE";
BA_ "SPN" SG_ 2566841342 EngPercentTorqueAtPoint2 540;
BA_ "SigType" SG_ 2566841342 EngSpeedAtPoint2 "RANGE";
BA_ "SPN" SG_ 2566841342 EngSpeedAtPoint2 528;
BA_ "SigType" SG_ 2566841342 EngPercentTorqueAtIdlePoint1 "RANGE";
BA_ "SPN" SG_ 2566841342 EngPercentTorqueAtIdlePoint1 539;
BA_ "SigType" SG_ 2566841342 EngSpeedAtIdlePoint1 "RANGE";
BA_ "SPN" SG_ 2566841342 EngSpeedAtIdlePoint1 188;
BA_ "SigType" SG_ 2566767870 XBRAccelerationLimit "RANGE";
BA_ "SPN" SG_ 2566767870 XBRAccelerationLimit 2921;
BA_ "SigType" SG_ 2566767870 XBRActiveCtrlMode "DISCRETE";
BA_ "SPN" SG_ 2566767870 XBRActiveCtrlMode 2918;
BA_ "SigType" SG_ 2566767870 XBRSystemState "DISCRETE";
BA_ "SPN" SG_ 2566767870 XBRSystemState 2917;
BA_ "SigType" SG_ 2566767870 FoundationBrakeUse "DISCRETE";
BA_ "SPN" SG_ 2566767870 FoundationBrakeUse 2919;
BA_ "SigType" SG_ 2566767870 HillHolderMode "DISCRETE";
BA_ "SPN" SG_ 2566767870 HillHolderMode 2912;
BA_ "SigType" SG_ 2566767870 HaltBrakeMode "DISCRETE";
BA_ "SPN" SG_ 2566767870 HaltBrakeMode 2913;
BA_ "SigType" SG_ 2633936126 BrkLnngRmnngRearAxle3RightWheel "RANGE";
BA_ "SPN" SG_ 2633936126 BrkLnngRmnngRearAxle3RightWheel 1106;
BA_ "SigType" SG_ 2633936126 BrkLnngRmningRearAxle3LeftWheel "RANGE";
BA_ "SPN" SG_ 2633936126 BrkLnngRmningRearAxle3LeftWheel 1105;
BA_ "SigType" SG_ 2633936126 BrkLnngRmnngRearAxle2RightWheel "RANGE";
BA_ "SPN" SG_ 2633936126 BrkLnngRmnngRearAxle2RightWheel 1104;
BA_ "SigType" SG_ 2633936126 BrkLnngRmningRearAxle2LeftWheel "RANGE";
BA_ "SPN" SG_ 2633936126 BrkLnngRmningRearAxle2LeftWheel 1103;
BA_ "SigType" SG_ 2633936126 BrkLnngRmnngRearAxle1RightWheel "RANGE";
BA_ "SPN" SG_ 2633936126 BrkLnngRmnngRearAxle1RightWheel 1102;
BA_ "SigType" SG_ 2633936126 BrkLnngRmningRearAxle1LeftWheel "RANGE";
BA_ "SPN" SG_ 2633936126 BrkLnngRmningRearAxle1LeftWheel 1101;
BA_ "SigType" SG_ 2633936126 BrkLnngRmnngFrontAxleRightWheel "RANGE";
BA_ "SPN" SG_ 2633936126 BrkLnngRmnngFrontAxleRightWheel 1100;
BA_ "SigType" SG_ 2633936126 BrkLnngRmningFrontAxleLeftWheel "RANGE";
BA_ "SPN" SG_ 2633936126 BrkLnngRmningFrontAxleLeftWheel 1099;
BA_ "SigType" SG_ 2566827518 BrkAppPrssHghRngRrAxl3RghtWheel "RANGE";
BA_ "SPN" SG_ 2566827518 BrkAppPrssHghRngRrAxl3RghtWheel 1098;
BA_ "SigType" SG_ 2566827518 BrkAppPrssHghRngRrAxl3LeftWheel "RANGE";
BA_ "SPN" SG_ 2566827518 BrkAppPrssHghRngRrAxl3LeftWheel 1097;
BA_ "SigType" SG_ 2566827518 BrkAppPrssHghRngRrAxl2RghtWheel "RANGE";
BA_ "SPN" SG_ 2566827518 BrkAppPrssHghRngRrAxl2RghtWheel 1096;
BA_ "SigType" SG_ 2566827518 BrkAppPrssHghRngRrAxl2LeftWheel "RANGE";
BA_ "SPN" SG_ 2566827518 BrkAppPrssHghRngRrAxl2LeftWheel 1095;
BA_ "SigType" SG_ 2566827518 BrkAppPrssHghRngRrAxl1RghtWheel "RANGE";
BA_ "SPN" SG_ 2566827518 BrkAppPrssHghRngRrAxl1RghtWheel 1094;
BA_ "SigType" SG_ 2566827518 BrkAppPrssHghRngRrAxl1LeftWheel "RANGE";
BA_ "SPN" SG_ 2566827518 BrkAppPrssHghRngRrAxl1LeftWheel 1093;
BA_ "SigType" SG_ 2566827518 BrkAppPrssHghRngFrntAxlRghtWhel "RANGE";
BA_ "SPN" SG_ 2566827518 BrkAppPrssHghRngFrntAxlRghtWhel 1092;
BA_ "SigType" SG_ 2566827518 BrkAppPrssHghRngFrntAxlLftWheel "RANGE";
BA_ "SPN" SG_ 2566827518 BrkAppPrssHghRngFrntAxlLftWheel 1091;
BA_ "SigType" SG_ 2566832126 RlativeSpeedRearAxle2RightWheel "RANGE";
BA_ "SPN" SG_ 2566832126 RlativeSpeedRearAxle2RightWheel 910;
BA_ "SigType" SG_ 2566832126 RelativeSpeedRearAxle2LeftWheel "RANGE";
BA_ "SPN" SG_ 2566832126 RelativeSpeedRearAxle2LeftWheel 909;
BA_ "SigType" SG_ 2566832126 RlativeSpeedRearAxle1RightWheel "RANGE";
BA_ "SPN" SG_ 2566832126 RlativeSpeedRearAxle1RightWheel 908;
BA_ "SigType" SG_ 2566832126 RelativeSpeedRearAxle1LeftWheel "RANGE";
BA_ "SPN" SG_ 2566832126 RelativeSpeedRearAxle1LeftWheel 907;
BA_ "SigType" SG_ 2566832126 RlativeSpeedFrontAxleRightWheel "RANGE";
BA_ "SPN" SG_ 2566832126 RlativeSpeedFrontAxleRightWheel 906;
BA_ "SigType" SG_ 2566832126 RelativeSpeedFrontAxleLeftWheel "RANGE";
BA_ "SPN" SG_ 2566832126 RelativeSpeedFrontAxleLeftWheel 905;
BA_ "SigType" SG_ 2566832126 FrontAxleSpeed "RANGE";
BA_ "SPN" SG_ 2566832126 FrontAxleSpeed 904;
BA_ "SigType" SG_ 2565865982 SrcAddrssOfCtrllngDvcFrBrkCntrl "RANGE";
BA_ "SPN" SG_ 2565865982 SrcAddrssOfCtrllngDvcFrBrkCntrl 1481;
BA_ "SigType" SG_ 2565865982 BrakePedalPos "RANGE";
BA_ "SPN" SG_ 2565865982 BrakePedalPos 521;
BA_ "SigType" SG_ 2565865982 TrctrMntdTrilerABSWarningSignal "DISCRETE";
BA_ "SPN" SG_ 2565865982 TrctrMntdTrilerABSWarningSignal 1792;
BA_ "SigType" SG_ 2565865982 TrailerABSStatus "DISCRETE";
BA_ "SPN" SG_ 2565865982 TrailerABSStatus 1836;
BA_ "SigType" SG_ 2565865982 HaltBrakeSwitch "DISCRETE";
BA_ "SPN" SG_ 2565865982 HaltBrakeSwitch 2911;
BA_ "SigType" SG_ 2565865982 ATC_ASRInformationSignal "DISCRETE";
BA_ "SPN" SG_ 2565865982 ATC_ASRInformationSignal 1793;
BA_ "SigType" SG_ 2565865982 ABS_EBSAmberWarningSignal "DISCRETE";
BA_ "SPN" SG_ 2565865982 ABS_EBSAmberWarningSignal 1438;
BA_ "SigType" SG_ 2565865982 EBSRedWarningSignal "DISCRETE";
BA_ "SPN" SG_ 2565865982 EBSRedWarningSignal 1439;
BA_ "SigType" SG_ 2565865982 ABSFullyOperational "DISCRETE";
BA_ "SPN" SG_ 2565865982 ABSFullyOperational 1243;
BA_ "SigType" SG_ 2565865982 EngRetarderSelection "RANGE";
BA_ "SPN" SG_ 2565865982 EngRetarderSelection 973;
BA_ "SigType" SG_ 2565865982 RemoteAccelEnableSwitch "DISCRETE";
BA_ "SPN" SG_ 2565865982 RemoteAccelEnableSwitch 969;
BA_ "SigType" SG_ 2565865982 EngAuxEngShutdownSwitch "DISCRETE";
BA_ "SPN" SG_ 2565865982 EngAuxEngShutdownSwitch 970;
BA_ "SigType" SG_ 2565865982 EngDerateSwitch "DISCRETE";
BA_ "SPN" SG_ 2565865982 EngDerateSwitch 971;
BA_ "SigType" SG_ 2565865982 AccelInterlockSwitch "DISCRETE";
BA_ "SPN" SG_ 2565865982 AccelInterlockSwitch 972;
BA_ "SigType" SG_ 2565865982 TractionCtrlOverrideSwitch "DISCRETE";
BA_ "SPN" SG_ 2565865982 TractionCtrlOverrideSwitch 1238;
BA_ "SigType" SG_ 2565865982 ASRHillHolderSwitch "DISCRETE";
BA_ "SPN" SG_ 2565865982 ASRHillHolderSwitch 577;
BA_ "SigType" SG_ 2565865982 ASROffroadSwitch "DISCRETE";
BA_ "SPN" SG_ 2565865982 ASROffroadSwitch 576;
BA_ "SigType" SG_ 2565865982 ABSOffroadSwitch "DISCRETE";
BA_ "SPN" SG_ 2565865982 ABSOffroadSwitch 575;
BA_ "SigType" SG_ 2565865982 EBSBrakeSwitch "DISCRETE";
BA_ "SPN" SG_ 2565865982 EBSBrakeSwitch 1121;
BA_ "SigType" SG_ 2565865982 AntiLockBrakingActive "DISCRETE";
BA_ "SPN" SG_ 2565865982 AntiLockBrakingActive 563;
BA_ "SigType" SG_ 2565865982 ASRBrakeCtrlActive "DISCRETE";
BA_ "SPN" SG_ 2565865982 ASRBrakeCtrlActive 562;
BA_ "SigType" SG_ 2565865982 ASREngCtrlActive "DISCRETE";
BA_ "SPN" SG_ 2565865982 ASREngCtrlActive 561;
BA_ "SigType" SG_ 2565867262 DiffLockStateCentralRear "DISCRETE";
BA_ "SPN" SG_ 2565867262 DiffLockStateCentralRear 566;
BA_ "SigType" SG_ 2565867262 DiffLockStateCentralFront "DISCRETE";
BA_ "SPN" SG_ 2565867262 DiffLockStateCentralFront 565;
BA_ "SigType" SG_ 2565867262 DiffLockStateCentral "DISCRETE";
BA_ "SPN" SG_ 2565867262 DiffLockStateCentral 564;
BA_ "SigType" SG_ 2565867262 DiffLockStateRearAxle2 "DISCRETE";
BA_ "SPN" SG_ 2565867262 DiffLockStateRearAxle2 570;
BA_ "SigType" SG_ 2565867262 DiffLockStateRearAxle1 "DISCRETE";
BA_ "SPN" SG_ 2565867262 DiffLockStateRearAxle1 569;
BA_ "SigType" SG_ 2565867262 DiffLockStateFrontAxle2 "DISCRETE";
BA_ "SPN" SG_ 2565867262 DiffLockStateFrontAxle2 568;
BA_ "SigType" SG_ 2565867262 DiffLockStateFrontAxle1 "DISCRETE";
BA_ "SPN" SG_ 2565867262 DiffLockStateFrontAxle1 567;
BA_ "SigType" SG_ 2565867262 Location "RANGE";
BA_ "SPN" SG_ 2565867262 Location 927;
BA_ "SigType" SG_ 2566821118 SeaWaterPumpOutletPress "RANGE";
BA_ "SPN" SG_ 2566821118 SeaWaterPumpOutletPress 2435;
BA_ "SigType" SG_ 2566821118 EngAuxCoolantTemp "RANGE";
BA_ "SPN" SG_ 2566821118 EngAuxCoolantTemp 1212;
BA_ "SigType" SG_ 2566821118 EngAuxCoolantPress "RANGE";
BA_ "SPN" SG_ 2566821118 EngAuxCoolantPress 1203;
BA_ "SigType" SG_ 2566847742 CargoAmbientTemp "RANGE";
BA_ "SPN" SG_ 2566847742 CargoAmbientTemp 169;
BA_ "SigType" SG_ 2566847742 EngOilFilterDiffPress "RANGE";
BA_ "SPN" SG_ 2566847742 EngOilFilterDiffPress 99;
BA_ "SigType" SG_ 2566847742 EngFuelFilterDiffPress "RANGE";
BA_ "SPN" SG_ 2566847742 EngFuelFilterDiffPress 95;
BA_ "SigType" SG_ 2566847742 FuelLevel "RANGE";
BA_ "SPN" SG_ 2566847742 FuelLevel 96;
BA_ "SigType" SG_ 2566847742 WasherFluidLevel "RANGE";
BA_ "SPN" SG_ 2566847742 WasherFluidLevel 80;
BA_ "SigType" SG_ 2566768382 EngStartEnableDevice2Config "DISCRETE";
BA_ "SPN" SG_ 2566768382 EngStartEnableDevice2Config 2898;
BA_ "SigType" SG_ 2566768382 EngStartEnableDevice1Config "DISCRETE";
BA_ "SPN" SG_ 2566768382 EngStartEnableDevice1Config 2899;
BA_ "SigType" SG_ 2566768382 EngStartEnableDevice2 "DISCRETE";
BA_ "SPN" SG_ 2566768382 EngStartEnableDevice2 1804;
BA_ "SigType" SG_ 2566768382 EngStartEnableDevice1 "DISCRETE";
BA_ "SPN" SG_ 2566768382 EngStartEnableDevice1 626;
BA_ "SigType" SG_ 2566811902 PoweredVehicleWeight "RANGE";
BA_ "SPN" SG_ 2566811902 PoweredVehicleWeight 1585;
BA_ "SigType" SG_ 2566811902 GrossCombinationVehicleWeight "RANGE";
BA_ "SPN" SG_ 2566811902 GrossCombinationVehicleWeight 1760;
BA_ "SigType" SG_ 2563768062 MxCntnuousRetarderTorqueLimitRq "RANGE";
BA_ "SPN" SG_ 2563768062 MxCntnuousRetarderTorqueLimitRq 1791;
BA_ "SigType" SG_ 2563768062 MnCntnuousRetarderTorqueLimitRq "RANGE";
BA_ "SPN" SG_ 2563768062 MnCntnuousRetarderTorqueLimitRq 1790;
BA_ "SigType" SG_ 2563768062 MxCntinuousRetarderSpeedLimitRq "RANGE";
BA_ "SPN" SG_ 2563768062 MxCntinuousRetarderSpeedLimitRq 1789;
BA_ "SigType" SG_ 2563768062 MnCntinuousRetarderSpeedLimitRq "RANGE";
BA_ "SPN" SG_ 2563768062 MnCntinuousRetarderSpeedLimitRq 1788;
BA_ "SigType" SG_ 2563768062 EngTorqueLimitRqMaxContinuous "RANGE";
BA_ "SPN" SG_ 2563768062 EngTorqueLimitRqMaxContinuous 1787;
BA_ "SigType" SG_ 2563768062 EngTorqueLimitRqMinContinuous "RANGE";
BA_ "SPN" SG_ 2563768062 EngTorqueLimitRqMinContinuous 1786;
BA_ "SigType" SG_ 2563768062 EngSpeedLimitRqMaxContinuous "RANGE";
BA_ "SPN" SG_ 2563768062 EngSpeedLimitRqMaxContinuous 1785;
BA_ "SigType" SG_ 2563768062 EngSpeedLimitRqMinContinuous "RANGE";
BA_ "SPN" SG_ 2563768062 EngSpeedLimitRqMinContinuous 1784;
BA_ "SigType" SG_ 2633924862 EngAverageCombustionTime "RANGE";
BA_ "SPN" SG_ 2633924862 EngAverageCombustionTime 1465;
BA_ "SigType" SG_ 2633924862 EngDesiredCombustionTime "RANGE";
BA_ "SPN" SG_ 2633924862 EngDesiredCombustionTime 1464;
BA_ "SigType" SG_ 2633924606 EngCyl20CombustionTime "RANGE";
BA_ "SPN" SG_ 2633924606 EngCyl20CombustionTime 1463;
BA_ "SigType" SG_ 2633924606 EngCyl19CombustionTime "RANGE";
BA_ "SPN" SG_ 2633924606 EngCyl19CombustionTime 1462;
BA_ "SigType" SG_ 2633924606 EngCyl18CombustionTime "RANGE";
BA_ "SPN" SG_ 2633924606 EngCyl18CombustionTime 1461;
BA_ "SigType" SG_ 2633924606 EngCyl17CombustionTime "RANGE";
BA_ "SPN" SG_ 2633924606 EngCyl17CombustionTime 1460;
BA_ "SigType" SG_ 2633924350 EngCyl16CombustionTime "RANGE";
BA_ "SPN" SG_ 2633924350 EngCyl16CombustionTime 1459;
BA_ "SigType" SG_ 2633924350 EngCyl15CombustionTime "RANGE";
BA_ "SPN" SG_ 2633924350 EngCyl15CombustionTime 1458;
BA_ "SigType" SG_ 2633924350 EngCyl14CombustionTime "RANGE";
BA_ "SPN" SG_ 2633924350 EngCyl14CombustionTime 1457;
BA_ "SigType" SG_ 2633924350 EngCyl13CombustionTime "RANGE";
BA_ "SPN" SG_ 2633924350 EngCyl13CombustionTime 1456;
BA_ "SigType" SG_ 2633924094 EngCyl12CombustionTime "RANGE";
BA_ "SPN" SG_ 2633924094 EngCyl12CombustionTime 1455;
BA_ "SigType" SG_ 2633924094 EngCyl11CombustionTime "RANGE";
BA_ "SPN" SG_ 2633924094 EngCyl11CombustionTime 1454;
BA_ "SigType" SG_ 2633924094 EngCyl10CombustionTime "RANGE";
BA_ "SPN" SG_ 2633924094 EngCyl10CombustionTime 1453;
BA_ "SigType" SG_ 2633924094 EngCyl9CombustionTime "RANGE";
BA_ "SPN" SG_ 2633924094 EngCyl9CombustionTime 1452;
BA_ "SigType" SG_ 2633923838 EngCyl8CombustionTime "RANGE";
BA_ "SPN" SG_ 2633923838 EngCyl8CombustionTime 1451;
BA_ "SigType" SG_ 2633923838 EngCyl7CombustionTime "RANGE";
BA_ "SPN" SG_ 2633923838 EngCyl7CombustionTime 1450;
BA_ "SigType" SG_ 2633923838 EngCyl6CombustionTime "RANGE";
BA_ "SPN" SG_ 2633923838 EngCyl6CombustionTime 1449;
BA_ "SigType" SG_ 2633923838 EngCyl5CombustionTime "RANGE";
BA_ "SPN" SG_ 2633923838 EngCyl5CombustionTime 1448;
BA_ "SigType" SG_ 2633923582 EngCyl4CombustionTime "RANGE";
BA_ "SPN" SG_ 2633923582 EngCyl4CombustionTime 1447;
BA_ "SigType" SG_ 2633923582 EngCyl3CombustionTime "RANGE";
BA_ "SPN" SG_ 2633923582 EngCyl3CombustionTime 1446;
BA_ "SigType" SG_ 2633923582 EngCyl2CombustionTime "RANGE";
BA_ "SPN" SG_ 2633923582 EngCyl2CombustionTime 1445;
BA_ "SigType" SG_ 2633923582 EngCyl1CombustionTime "RANGE";
BA_ "SPN" SG_ 2633923582 EngCyl1CombustionTime 1444;
BA_ "SigType" SG_ 2633878014 TotalCountOfConfigChangesMade "RANGE";
BA_ "SPN" SG_ 2633878014 TotalCountOfConfigChangesMade 2887;
BA_ "SigType" SG_ 2566771966 FifthWheelReleaseCtrl "DISCRETE";
BA_ "SPN" SG_ 2566771966 FifthWheelReleaseCtrl 3314;
BA_ "SigType" SG_ 2566771966 FfthWhlRlaseCtrlSecurityLockout "DISCRETE";
BA_ "SPN" SG_ 2566771966 FfthWhlRlaseCtrlSecurityLockout 3315;
BA_ "SigType" SG_ 2566771966 TransferCaseSelectorSwitch "DISCRETE";
BA_ "SPN" SG_ 2566771966 TransferCaseSelectorSwitch 2796;
BA_ "SigType" SG_ 2564882174 SelectedMaxVehicleSpeedLimit "RANGE";
BA_ "SPN" SG_ 2564882174 SelectedMaxVehicleSpeedLimit 2596;
BA_ "SigType" SG_ 2564882174 RqCabZoneHeating "DISCRETE";
BA_ "SPN" SG_ 2564882174 RqCabZoneHeating 1686;
BA_ "SigType" SG_ 2564882174 RqEngZoneHeating "DISCRETE";
BA_ "SPN" SG_ 2564882174 RqEngZoneHeating 1685;
BA_ "SigType" SG_ 2564882174 AuxHeaterModeRq "DISCRETE";
BA_ "SPN" SG_ 2564882174 AuxHeaterModeRq 1683;
BA_ "SigType" SG_ 2564882174 EngAutomaticStartEnableSwitch "DISCRETE";
BA_ "SPN" SG_ 2564882174 EngAutomaticStartEnableSwitch 1656;
BA_ "SigType" SG_ 2564882174 AtmaticGearShiftingEnableSwitch "DISCRETE";
BA_ "SPN" SG_ 2564882174 AtmaticGearShiftingEnableSwitch 1666;
BA_ "SigType" SG_ 2564882174 VhclLmtngSpdGvernorEnableSwitch "DISCRETE";
BA_ "SPN" SG_ 2564882174 VhclLmtngSpdGvernorEnableSwitch 1653;
BA_ "SigType" SG_ 2564882174 VhclLmtngSpdGvrnrIncrmentSwitch "DISCRETE";
BA_ "SPN" SG_ 2564882174 VhclLmtngSpdGvrnrIncrmentSwitch 1654;
BA_ "SigType" SG_ 2564882174 VhclLmtngSpdGvrnrDcrementSwitch "DISCRETE";
BA_ "SPN" SG_ 2564882174 VhclLmtngSpdGvrnrDcrementSwitch 1655;
BA_ "SigType" SG_ 2564882174 SeatBeltSwitch "DISCRETE";
BA_ "SPN" SG_ 2564882174 SeatBeltSwitch 1856;
BA_ "SigType" SG_ 2564882174 OperatorSeatDirectionSwitch "DISCRETE";
BA_ "SPN" SG_ 2564882174 OperatorSeatDirectionSwitch 1714;
BA_ "SigType" SG_ 2564882174 BatteryMainSwitchHoldRq "DISCRETE";
BA_ "SPN" SG_ 2564882174 BatteryMainSwitchHoldRq 1682;
BA_ "SigType" SG_ 2564882174 AuxHeaterCoolantPumpRq "DISCRETE";
BA_ "SPN" SG_ 2564882174 AuxHeaterCoolantPumpRq 1684;
BA_ "SigType" SG_ 2564882174 CabInteriorTempCmd "RANGE";
BA_ "SPN" SG_ 2564882174 CabInteriorTempCmd 1691;
BA_ "SigType" SG_ 2564882174 RqedPercentFanSpeed "RANGE";
BA_ "SPN" SG_ 2564882174 RqedPercentFanSpeed 986;
BA_ "SigType" SG_ 2563833598 IlluminationBrightnessPercent "RANGE";
BA_ "SPN" SG_ 2563833598 IlluminationBrightnessPercent 1487;
BA_ "SigType" SG_ 2566844926 EngShutdownOverrideSwitch "DISCRETE";
BA_ "SPN" SG_ 2566844926 EngShutdownOverrideSwitch 1237;
BA_ "SigType" SG_ 2566844926 EngTestModeSwitch "DISCRETE";
BA_ "SPN" SG_ 2566844926 EngTestModeSwitch 966;
BA_ "SigType" SG_ 2566844926 EngIdleDecrementSwitch "DISCRETE";
BA_ "SPN" SG_ 2566844926 EngIdleDecrementSwitch 967;
BA_ "SigType" SG_ 2566844926 EngIdleIncrementSwitch "DISCRETE";
BA_ "SPN" SG_ 2566844926 EngIdleIncrementSwitch 968;
BA_ "SigType" SG_ 2566844926 CruiseCtrlStates "DISCRETE";
BA_ "SPN" SG_ 2566844926 CruiseCtrlStates 527;
BA_ "SigType" SG_ 2566844926 PTOState "DISCRETE";
BA_ "SPN" SG_ 2566844926 PTOState 976;
BA_ "SigType" SG_ 2566844926 CruiseCtrlSetSpeed "RANGE";
BA_ "SPN" SG_ 2566844926 CruiseCtrlSetSpeed 86;
BA_ "SigType" SG_ 2566844926 CruiseCtrlAccelerateSwitch "DISCRETE";
BA_ "SPN" SG_ 2566844926 CruiseCtrlAccelerateSwitch 602;
BA_ "SigType" SG_ 2566844926 CruiseCtrlResumeSwitch "DISCRETE";
BA_ "SPN" SG_ 2566844926 CruiseCtrlResumeSwitch 601;
BA_ "SigType" SG_ 2566844926 CruiseCtrlCoastSwitch "DISCRETE";
BA_ "SPN" SG_ 2566844926 CruiseCtrlCoastSwitch 600;
BA_ "SigType" SG_ 2566844926 CruiseCtrlSetSwitch "DISCRETE";
BA_ "SPN" SG_ 2566844926 CruiseCtrlSetSwitch 599;
BA_ "SigType" SG_ 2566844926 ClutchSwitch "DISCRETE";
BA_ "SPN" SG_ 2566844926 ClutchSwitch 598;
BA_ "SigType" SG_ 2566844926 BrakeSwitch "DISCRETE";
BA_ "SPN" SG_ 2566844926 BrakeSwitch 597;
BA_ "SigType" SG_ 2566844926 CruiseCtrlEnableSwitch "DISCRETE";
BA_ "SPN" SG_ 2566844926 CruiseCtrlEnableSwitch 596;
BA_ "SigType" SG_ 2566844926 CruiseCtrlActive "DISCRETE";
BA_ "SPN" SG_ 2566844926 CruiseCtrlActive 595;
BA_ "SigType" SG_ 2566844926 WheelBasedVehicleSpeed "RANGE";
BA_ "SPN" SG_ 2566844926 WheelBasedVehicleSpeed 84;
BA_ "SigType" SG_ 2566844926 CruiseCtrlPauseSwitch "DISCRETE";
BA_ "SPN" SG_ 2566844926 CruiseCtrlPauseSwitch 1633;
BA_ "SigType" SG_ 2566844926 ParkingBrakeSwitch "DISCRETE";
BA_ "SPN" SG_ 2566844926 ParkingBrakeSwitch 70;
BA_ "SigType" SG_ 2566844926 TwoSpeedAxleSwitch "DISCRETE";
BA_ "SPN" SG_ 2566844926 TwoSpeedAxleSwitch 69;
BA_ "SigType" SG_ 2566843902 CruiseCtrlLowSetLimitSpeed "RANGE";
BA_ "SPN" SG_ 2566843902 CruiseCtrlLowSetLimitSpeed 88;
BA_ "SigType" SG_ 2566843902 CruiseCtrlHighSetLimitSpeed "RANGE";
BA_ "SPN" SG_ 2566843902 CruiseCtrlHighSetLimitSpeed 87;
BA_ "SigType" SG_ 2566843902 MaxVehicleSpeedLimit "RANGE";
BA_ "SPN" SG_ 2566843902 MaxVehicleSpeedLimit 74;
BA_ "SigType" SG_ 2566809598 AuxHeaterMaxOutputPower "RANGE";
BA_ "SPN" SG_ 2566809598 AuxHeaterMaxOutputPower 1690;
BA_ "SigType" SG_ 2633940222 TripServiceBrakeApps "DISCRETE";
BA_ "SPN" SG_ 2633940222 TripServiceBrakeApps 993;
BA_ "SigType" SG_ 2633940222 TripServiceBrakeDistance "RANGE";
BA_ "SPN" SG_ 2633940222 TripServiceBrakeDistance 992;
BA_ "SigType" SG_ 2633940222 TripCompressionBrakeDistance "RANGE";
BA_ "SPN" SG_ 2633940222 TripCompressionBrakeDistance 991;
BA_ "SigType" SG_ 2633940222 TotalCompressionBrakeDistance "RANGE";
BA_ "SPN" SG_ 2633940222 TotalCompressionBrakeDistance 990;
BA_ "SigType" SG_ 2566775294 CbA_CRfrgrntCmprssorOutletPress "RANGE";
BA_ "SPN" SG_ 2566775294 CbA_CRfrgrntCmprssorOutletPress 2609;
BA_ "SigType" SG_ 2566803710 Battery2Temp "RANGE";
BA_ "SPN" SG_ 2566803710 Battery2Temp 1801;
BA_ "SigType" SG_ 2566803710 Battery1Temp "RANGE";
BA_ "SPN" SG_ 2566803710 Battery1Temp 1800;
BA_ "SigType" SG_ 2566809342 BatteryMainSwitchHoldState "DISCRETE";
BA_ "SPN" SG_ 2566809342 BatteryMainSwitchHoldState 1681;
BA_ "SigType" SG_ 2365446910 Joystick3XAxisDetentPosStatus "DISCRETE";
BA_ "SPN" SG_ 2365446910 Joystick3XAxisDetentPosStatus 2754;
BA_ "SigType" SG_ 2365446910 Joystick3Button9PressedStatus "DISCRETE";
BA_ "SPN" SG_ 2365446910 Joystick3Button9PressedStatus 2767;
BA_ "SigType" SG_ 2365446910 Joystick3Button10PressedStatus "DISCRETE";
BA_ "SPN" SG_ 2365446910 Joystick3Button10PressedStatus 2768;
BA_ "SigType" SG_ 2365446910 Joystick3Button11PressedStatus "DISCRETE";
BA_ "SPN" SG_ 2365446910 Joystick3Button11PressedStatus 2769;
BA_ "SigType" SG_ 2365446910 Joystick3Button12PressedStatus "DISCRETE";
BA_ "SPN" SG_ 2365446910 Joystick3Button12PressedStatus 2770;
BA_ "SigType" SG_ 2365446910 Joystick3YAxisDetentPosStatus "DISCRETE";
BA_ "SPN" SG_ 2365446910 Joystick3YAxisDetentPosStatus 2755;
BA_ "SigType" SG_ 2365446910 Joystick3YAxisPos "RANGE";
BA_ "SPN" SG_ 2365446910 Joystick3YAxisPos 2735;
BA_ "SigType" SG_ 2365446910 Jystck3YAxsLvrFrwrdPstvPsStatus "DISCRETE";
BA_ "SPN" SG_ 2365446910 Jystck3YAxsLvrFrwrdPstvPsStatus 2740;
BA_ "SigType" SG_ 2365446910 Jystck3YAxsLvrBckNgtvePosStatus "DISCRETE";
BA_ "SPN" SG_ 2365446910 Jystck3YAxsLvrBckNgtvePosStatus 2745;
BA_ "SigType" SG_ 2365446910 Joystick3YAxisNeutralPosStatus "DISCRETE";
BA_ "SPN" SG_ 2365446910 Joystick3YAxisNeutralPosStatus 2750;
BA_ "SigType" SG_ 2365446910 Joystick3XAxisPos "RANGE";
BA_ "SPN" SG_ 2365446910 Joystick3XAxisPos 2734;
BA_ "SigType" SG_ 2365446910 Jystck3XAxsLvrRghtPstvPosStatus "DISCRETE";
BA_ "SPN" SG_ 2365446910 Jystck3XAxsLvrRghtPstvPosStatus 2739;
BA_ "SigType" SG_ 2365446910 Jystck3XAxsLvrLftNgtvePosStatus "DISCRETE";
BA_ "SPN" SG_ 2365446910 Jystck3XAxsLvrLftNgtvePosStatus 2744;
BA_ "SigType" SG_ 2365446910 Joystick3XAxisNeutralPosStatus "DISCRETE";
BA_ "SPN" SG_ 2365446910 Joystick3XAxisNeutralPosStatus 2749;
BA_ "SigType" SG_ 2365446910 Joystick3Button5PressedStatus "DISCRETE";
BA_ "SPN" SG_ 2365446910 Joystick3Button5PressedStatus 2763;
BA_ "SigType" SG_ 2365446910 Joystick3Button6PressedStatus "DISCRETE";
BA_ "SPN" SG_ 2365446910 Joystick3Button6PressedStatus 2764;
BA_ "SigType" SG_ 2365446910 Joystick3Button7PressedStatus "DISCRETE";
BA_ "SPN" SG_ 2365446910 Joystick3Button7PressedStatus 2765;
BA_ "SigType" SG_ 2365446910 Joystick3Button8PressedStatus "DISCRETE";
BA_ "SPN" SG_ 2365446910 Joystick3Button8PressedStatus 2766;
BA_ "SigType" SG_ 2365446910 Joystick3Button1PressedStatus "DISCRETE";
BA_ "SPN" SG_ 2365446910 Joystick3Button1PressedStatus 2759;
BA_ "SigType" SG_ 2365446910 Joystick3Button2PressedStatus "DISCRETE";
BA_ "SPN" SG_ 2365446910 Joystick3Button2PressedStatus 2760;
BA_ "SigType" SG_ 2365446910 Joystick3Button3PressedStatus "DISCRETE";
BA_ "SPN" SG_ 2365446910 Joystick3Button3PressedStatus 2761;
BA_ "SigType" SG_ 2365446910 Joystick3Button4PressedStatus "DISCRETE";
BA_ "SPN" SG_ 2365446910 Joystick3Button4PressedStatus 2762;
BA_ "SigType" SG_ 2365446398 Joystick2XAxisDetentPosStatus "DISCRETE";
BA_ "SPN" SG_ 2365446398 Joystick2XAxisDetentPosStatus 2717;
BA_ "SigType" SG_ 2365446398 Joystick2YAxisDetentPosStatus "DISCRETE";
BA_ "SPN" SG_ 2365446398 Joystick2YAxisDetentPosStatus 2718;
BA_ "SigType" SG_ 2365446398 Joystick2YAxisPos "RANGE";
BA_ "SPN" SG_ 2365446398 Joystick2YAxisPos 2698;
BA_ "SigType" SG_ 2365446398 Jystck2YAxsLvrFrwrdPstvPsStatus "DISCRETE";
BA_ "SPN" SG_ 2365446398 Jystck2YAxsLvrFrwrdPstvPsStatus 2703;
BA_ "SigType" SG_ 2365446398 Jystck2YAxsLvrBckNgtvePosStatus "DISCRETE";
BA_ "SPN" SG_ 2365446398 Jystck2YAxsLvrBckNgtvePosStatus 2708;
BA_ "SigType" SG_ 2365446398 Joystick2YAxisNeutralPosStatus "DISCRETE";
BA_ "SPN" SG_ 2365446398 Joystick2YAxisNeutralPosStatus 2713;
BA_ "SigType" SG_ 2365446398 Joystick2XAxisPos "RANGE";
BA_ "SPN" SG_ 2365446398 Joystick2XAxisPos 2697;
BA_ "SigType" SG_ 2365446398 Jystck2XAxsLvrRghtPstvPosStatus "DISCRETE";
BA_ "SPN" SG_ 2365446398 Jystck2XAxsLvrRghtPstvPosStatus 2702;
BA_ "SigType" SG_ 2365446398 Jystck2XAxsLvrLftNgtvePosStatus "DISCRETE";
BA_ "SPN" SG_ 2365446398 Jystck2XAxsLvrLftNgtvePosStatus 2707;
BA_ "SigType" SG_ 2365446398 Joystick2XAxisNeutralPosStatus "DISCRETE";
BA_ "SPN" SG_ 2365446398 Joystick2XAxisNeutralPosStatus 2712;
BA_ "SigType" SG_ 2365446398 Joystick2Button9PressedStatus "DISCRETE";
BA_ "SPN" SG_ 2365446398 Joystick2Button9PressedStatus 2730;
BA_ "SigType" SG_ 2365446398 Joystick2Button10PressedStatus "DISCRETE";
BA_ "SPN" SG_ 2365446398 Joystick2Button10PressedStatus 2731;
BA_ "SigType" SG_ 2365446398 Joystick2Button11PressedStatus "DISCRETE";
BA_ "SPN" SG_ 2365446398 Joystick2Button11PressedStatus 2732;
BA_ "SigType" SG_ 2365446398 Joystick2Button12PressedStatus "DISCRETE";
BA_ "SPN" SG_ 2365446398 Joystick2Button12PressedStatus 2733;
BA_ "SigType" SG_ 2365446398 Joystick2Button5PressedStatus "DISCRETE";
BA_ "SPN" SG_ 2365446398 Joystick2Button5PressedStatus 2726;
BA_ "SigType" SG_ 2365446398 Joystick2Button6PressedStatus "DISCRETE";
BA_ "SPN" SG_ 2365446398 Joystick2Button6PressedStatus 2727;
BA_ "SigType" SG_ 2365446398 Joystick2Button7PressedStatus "DISCRETE";
BA_ "SPN" SG_ 2365446398 Joystick2Button7PressedStatus 2728;
BA_ "SigType" SG_ 2365446398 Joystick2Button8PressedStatus "DISCRETE";
BA_ "SPN" SG_ 2365446398 Joystick2Button8PressedStatus 2729;
BA_ "SigType" SG_ 2365446398 Joystick2Button1PressedStatus "DISCRETE";
BA_ "SPN" SG_ 2365446398 Joystick2Button1PressedStatus 2722;
BA_ "SigType" SG_ 2365446398 Joystick2Button2PressedStatus "DISCRETE";
BA_ "SPN" SG_ 2365446398 Joystick2Button2PressedStatus 2723;
BA_ "SigType" SG_ 2365446398 Joystick2Button3PressedStatus "DISCRETE";
BA_ "SPN" SG_ 2365446398 Joystick2Button3PressedStatus 2724;
BA_ "SigType" SG_ 2365446398 Joystick2Button4PressedStatus "DISCRETE";
BA_ "SPN" SG_ 2365446398 Joystick2Button4PressedStatus 2725;
BA_ "SigType" SG_ 2365445886 Joystick1XAxisDetentPosStatus "DISCRETE";
BA_ "SPN" SG_ 2365445886 Joystick1XAxisDetentPosStatus 2680;
BA_ "SigType" SG_ 2365445886 Joystick1YAxisDetentPosStatus "DISCRETE";
BA_ "SPN" SG_ 2365445886 Joystick1YAxisDetentPosStatus 2681;
BA_ "SigType" SG_ 2365445886 Joystick1YAxisPos "RANGE";
BA_ "SPN" SG_ 2365445886 Joystick1YAxisPos 2661;
BA_ "SigType" SG_ 2365445886 Jystck1YAxsLvrFrwrdPstvPsStatus "DISCRETE";
BA_ "SPN" SG_ 2365445886 Jystck1YAxsLvrFrwrdPstvPsStatus 2666;
BA_ "SigType" SG_ 2365445886 Jystck1YAxsLvrBckNgtvePosStatus "DISCRETE";
BA_ "SPN" SG_ 2365445886 Jystck1YAxsLvrBckNgtvePosStatus 2671;
BA_ "SigType" SG_ 2365445886 Joystick1YAxisNeutralPosStatus "DISCRETE";
BA_ "SPN" SG_ 2365445886 Joystick1YAxisNeutralPosStatus 2676;
BA_ "SigType" SG_ 2365445886 Joystick1XAxisPos "RANGE";
BA_ "SPN" SG_ 2365445886 Joystick1XAxisPos 2660;
BA_ "SigType" SG_ 2365445886 Joystick1Button9PressedStatus "DISCRETE";
BA_ "SPN" SG_ 2365445886 Joystick1Button9PressedStatus 2693;
BA_ "SigType" SG_ 2365445886 Joystick1Button10PressedStatus "DISCRETE";
BA_ "SPN" SG_ 2365445886 Joystick1Button10PressedStatus 2694;
BA_ "SigType" SG_ 2365445886 Joystick1Button11PressedStatus "DISCRETE";
BA_ "SPN" SG_ 2365445886 Joystick1Button11PressedStatus 2695;
BA_ "SigType" SG_ 2365445886 Joystick1Button12PressedStatus "DISCRETE";
BA_ "SPN" SG_ 2365445886 Joystick1Button12PressedStatus 2696;
BA_ "SigType" SG_ 2365445886 Joystick1Button5PressedStatus "DISCRETE";
BA_ "SPN" SG_ 2365445886 Joystick1Button5PressedStatus 2689;
BA_ "SigType" SG_ 2365445886 Joystick1Button6PressedStatus "DISCRETE";
BA_ "SPN" SG_ 2365445886 Joystick1Button6PressedStatus 2690;
BA_ "SigType" SG_ 2365445886 Joystick1Button7PressedStatus "DISCRETE";
BA_ "SPN" SG_ 2365445886 Joystick1Button7PressedStatus 2691;
BA_ "SigType" SG_ 2365445886 Joystick1Button8PressedStatus "DISCRETE";
BA_ "SPN" SG_ 2365445886 Joystick1Button8PressedStatus 2692;
BA_ "SigType" SG_ 2365445886 Joystick1Button1PressedStatus "DISCRETE";
BA_ "SPN" SG_ 2365445886 Joystick1Button1PressedStatus 2685;
BA_ "SigType" SG_ 2365445886 Joystick1Button2PressedStatus "DISCRETE";
BA_ "SPN" SG_ 2365445886 Joystick1Button2PressedStatus 2686;
BA_ "SigType" SG_ 2365445886 Joystick1Button3PressedStatus "DISCRETE";
BA_ "SPN" SG_ 2365445886 Joystick1Button3PressedStatus 2687;
BA_ "SigType" SG_ 2365445886 Joystick1Button4PressedStatus "DISCRETE";
BA_ "SPN" SG_ 2365445886 Joystick1Button4PressedStatus 2688;
BA_ "SigType" SG_ 2365445886 Jystck1XAxsLvrRghtPstvPosStatus "DISCRETE";
BA_ "SPN" SG_ 2365445886 Jystck1XAxsLvrRghtPstvPosStatus 2665;
BA_ "SigType" SG_ 2365445886 Jystck1XAxsLvrLftNgtvePosStatus "DISCRETE";
BA_ "SPN" SG_ 2365445886 Jystck1XAxsLvrLftNgtvePosStatus 2670;
BA_ "SigType" SG_ 2365445886 Joystick1XAxisNeutralPosStatus "DISCRETE";
BA_ "SPN" SG_ 2365445886 Joystick1XAxisNeutralPosStatus 2675;
BA_ "SigType" SG_ 2566847230 ParkingBrakeActuator "DISCRETE";
BA_ "SPN" SG_ 2566847230 ParkingBrakeActuator 619;
BA_ "SigType" SG_ 2566847230 BrakeSecondPress "RANGE";
BA_ "SPN" SG_ 2566847230 BrakeSecondPress 118;
BA_ "SigType" SG_ 2566847230 BrakePrimaryPress "RANGE";
BA_ "SPN" SG_ 2566847230 BrakePrimaryPress 117;
BA_ "SigType" SG_ 2566847230 BrakeAppPress "RANGE";
BA_ "SPN" SG_ 2566847230 BrakeAppPress 116;
BA_ "SigType" SG_ 2566848254 AuxPumpPress "RANGE";
BA_ "SPN" SG_ 2566848254 AuxPumpPress 73;
BA_ "SigType" SG_ 2566838782 AuxI_OChannel2 "RANGE";
BA_ "SPN" SG_ 2566838782 AuxI_OChannel2 1084;
BA_ "SigType" SG_ 2566838782 AuxI_OChannel1 "RANGE";
BA_ "SPN" SG_ 2566838782 AuxI_OChannel1 1083;
BA_ "SigType" SG_ 2566838782 AuxI_O13 "DISCRETE";
BA_ "SPN" SG_ 2566838782 AuxI_O13 713;
BA_ "SigType" SG_ 2566838782 AuxI_O14 "DISCRETE";
BA_ "SPN" SG_ 2566838782 AuxI_O14 714;
BA_ "SigType" SG_ 2566838782 AuxI_O15 "DISCRETE";
BA_ "SPN" SG_ 2566838782 AuxI_O15 715;
BA_ "SigType" SG_ 2566838782 AuxI_O16 "DISCRETE";
BA_ "SPN" SG_ 2566838782 AuxI_O16 716;
BA_ "SigType" SG_ 2566838782 AuxI_O09 "DISCRETE";
BA_ "SPN" SG_ 2566838782 AuxI_O09 709;
BA_ "SigType" SG_ 2566838782 AuxI_O10 "DISCRETE";
BA_ "SPN" SG_ 2566838782 AuxI_O10 710;
BA_ "SigType" SG_ 2566838782 AuxI_O11 "DISCRETE";
BA_ "SPN" SG_ 2566838782 AuxI_O11 711;
BA_ "SigType" SG_ 2566838782 AuxI_O12 "DISCRETE";
BA_ "SPN" SG_ 2566838782 AuxI_O12 712;
BA_ "SigType" SG_ 2566838782 AuxI_O05 "DISCRETE";
BA_ "SPN" SG_ 2566838782 AuxI_O05 705;
BA_ "SigType" SG_ 2566838782 AuxI_O06 "DISCRETE";
BA_ "SPN" SG_ 2566838782 AuxI_O06 706;
BA_ "SigType" SG_ 2566838782 AuxI_O07 "DISCRETE";
BA_ "SPN" SG_ 2566838782 AuxI_O07 707;
BA_ "SigType" SG_ 2566838782 AuxI_O08 "DISCRETE";
BA_ "SPN" SG_ 2566838782 AuxI_O08 708;
BA_ "SigType" SG_ 2566838782 AuxI_O01 "DISCRETE";
BA_ "SPN" SG_ 2566838782 AuxI_O01 701;
BA_ "SigType" SG_ 2566838782 AuxI_O02 "DISCRETE";
BA_ "SPN" SG_ 2566838782 AuxI_O02 702;
BA_ "SigType" SG_ 2566838782 AuxI_O03 "DISCRETE";
BA_ "SPN" SG_ 2566838782 AuxI_O03 703;
BA_ "SigType" SG_ 2566838782 AuxI_O04 "DISCRETE";
BA_ "SPN" SG_ 2566838782 AuxI_O04 704;
BA_ "SigType" SG_ 2631728894 AntitheftRandomNumber "RANGE";
BA_ "SPN" SG_ 2631728894 AntitheftRandomNumber 1198;
BA_ "SigType" SG_ 2631728894 AntitheftComponentStatusStates "DISCRETE";
BA_ "SPN" SG_ 2631728894 AntitheftComponentStatusStates 1196;
BA_ "SigType" SG_ 2631728894 AntthftEncryptnSdPrsntIndicator "DISCRETE";
BA_ "SPN" SG_ 2631728894 AntthftEncryptnSdPrsntIndicator 1194;
BA_ "SigType" SG_ 2631728894 AntitheftModifyPwdStates "DISCRETE";
BA_ "SPN" SG_ 2631728894 AntitheftModifyPwdStates 1197;
BA_ "SigType" SG_ 2631728894 AntitheftPwdValidIndicator "DISCRETE";
BA_ "SPN" SG_ 2631728894 AntitheftPwdValidIndicator 1195;
BA_ "SigType" SG_ 2631794430 AntitheftPasswordRepresentation "RANGE";
BA_ "SPN" SG_ 2631794430 AntitheftPasswordRepresentation 1202;
BA_ "SigType" SG_ 2631794430 AntitheftCmdStates "DISCRETE";
BA_ "SPN" SG_ 2631794430 AntitheftCmdStates 1201;
BA_ "SigType" SG_ 2631794430 AntitheftDesiredExitModeStates "DISCRETE";
BA_ "SPN" SG_ 2631794430 AntitheftDesiredExitModeStates 1200;
BA_ "SigType" SG_ 2631794430 AntthftEncryptonIndicatorStates "DISCRETE";
BA_ "SPN" SG_ 2631794430 AntthftEncryptonIndicatorStates 1199;
BA_ "SigType" SG_ 2566763006 PrtcltTrpIntkGsTmpPrliminaryFMI "RANGE";
BA_ "SPN" SG_ 2566763006 PrtcltTrpIntkGsTmpPrliminaryFMI 3244;
BA_ "SigType" SG_ 2566763006 ParticulateTrapIntakeGasTemp "RANGE";
BA_ "SPN" SG_ 2566763006 ParticulateTrapIntakeGasTemp 3242;
BA_ "SigType" SG_ 2566763006 ExhaustGasTemp1PreliminaryFMI "RANGE";
BA_ "SPN" SG_ 2566763006 ExhaustGasTemp1PreliminaryFMI 3243;
BA_ "SigType" SG_ 2566763006 ExhaustGasTemp1 "RANGE";
BA_ "SPN" SG_ 2566763006 ExhaustGasTemp1 3241;
BA_ "SigType" SG_ 2633934846 EngAltWinding3Temp "RANGE";
BA_ "SPN" SG_ 2633934846 EngAltWinding3Temp 1126;
BA_ "SigType" SG_ 2633934846 EngAltWinding2Temp "RANGE";
BA_ "SPN" SG_ 2633934846 EngAltWinding2Temp 1125;
BA_ "SigType" SG_ 2633934846 EngAltWinding1Temp "RANGE";
BA_ "SPN" SG_ 2633934846 EngAltWinding1Temp 1124;
BA_ "SigType" SG_ 2633934846 EngAltBearing2Temp "RANGE";
BA_ "SPN" SG_ 2633934846 EngAltBearing2Temp 1123;
BA_ "SigType" SG_ 2633934846 EngAltBearing1Temp "RANGE";
BA_ "SPN" SG_ 2633934846 EngAltBearing1Temp 1122;
BA_ "SigType" SG_ 2362572542 LevelPresetRearAxleRight "RANGE";
BA_ "SPN" SG_ 2362572542 LevelPresetRearAxleRight 1735;
BA_ "SigType" SG_ 2362572542 LevelPresetRearAxleLeft "RANGE";
BA_ "SPN" SG_ 2362572542 LevelPresetRearAxleLeft 1758;
BA_ "SigType" SG_ 2362572542 LevelPresetFrontAxleRight "RANGE";
BA_ "SPN" SG_ 2362572542 LevelPresetFrontAxleRight 1757;
BA_ "SigType" SG_ 2362572542 LevelPresetFrontAxleLeft "RANGE";
BA_ "SPN" SG_ 2362572542 LevelPresetFrontAxleLeft 1732;
BA_ "SigType" SG_ 2365478910 ElctrncShckAbsrbrCtrlMdLft_TgAxl "DISCRETE";
BA_ "SPN" SG_ 2365478910 ElctrncShckAbsrbrCtrlMdLft_TgAxl 1831;
BA_ "SigType" SG_ 2365478910 ElctrncShckAbsrbrCtrlMdRearAxle "DISCRETE";
BA_ "SPN" SG_ 2365478910 ElctrncShckAbsrbrCtrlMdRearAxle 1832;
BA_ "SigType" SG_ 2365478910 ElctrncShckAbsrbrCtrlMdFrntAxle "DISCRETE";
BA_ "SPN" SG_ 2365478910 ElctrncShckAbsrbrCtrlMdFrntAxle 1833;
BA_ "SigType" SG_ 2365478910 DamperStiffnessLift_TagAxle "RANGE";
BA_ "SPN" SG_ 2365478910 DamperStiffnessLift_TagAxle 1731;
BA_ "SigType" SG_ 2365478910 DamperStiffnessRearAxle "RANGE";
BA_ "SPN" SG_ 2365478910 DamperStiffnessRearAxle 1730;
BA_ "SigType" SG_ 2365478910 DamperStiffnessFrontAxle "RANGE";
BA_ "SPN" SG_ 2365478910 DamperStiffnessFrontAxle 1729;
BA_ "SigType" SG_ 2566805758 BellowPressRearAxleRight "RANGE";
BA_ "SPN" SG_ 2566805758 BellowPressRearAxleRight 1728;
BA_ "SigType" SG_ 2566805758 BellowPressRearAxleLeft "RANGE";
BA_ "SPN" SG_ 2566805758 BellowPressRearAxleLeft 1727;
BA_ "SigType" SG_ 2566805758 BellowPressFrontAxleRight "RANGE";
BA_ "SPN" SG_ 2566805758 BellowPressFrontAxleRight 1726;
BA_ "SigType" SG_ 2566805758 BellowPressFrontAxleLeft "RANGE";
BA_ "SPN" SG_ 2566805758 BellowPressFrontAxleLeft 1725;
BA_ "SigType" SG_ 2566806014 RelativeLevelRearAxleRight "RANGE";
BA_ "SPN" SG_ 2566806014 RelativeLevelRearAxleRight 1723;
BA_ "SigType" SG_ 2566806014 RelativeLevelRearAxleLeft "RANGE";
BA_ "SPN" SG_ 2566806014 RelativeLevelRearAxleLeft 1724;
BA_ "SigType" SG_ 2566806014 RelativeLevelFrontAxleRight "RANGE";
BA_ "SPN" SG_ 2566806014 RelativeLevelFrontAxleRight 1722;
BA_ "SigType" SG_ 2566806014 RelativeLevelFrontAxleLeft "RANGE";
BA_ "SPN" SG_ 2566806014 RelativeLevelFrontAxleLeft 1721;
BA_ "SigType" SG_ 2362638078 ProhibitAirSuspensionCtrl "DISCRETE";
BA_ "SPN" SG_ 2362638078 ProhibitAirSuspensionCtrl 3215;
BA_ "SigType" SG_ 2362638078 KneelingCmdRearAxle "DISCRETE";
BA_ "SPN" SG_ 2362638078 KneelingCmdRearAxle 1829;
BA_ "SigType" SG_ 2362638078 KneelingCmdFrontAxle "DISCRETE";
BA_ "SPN" SG_ 2362638078 KneelingCmdFrontAxle 1830;
BA_ "SigType" SG_ 2362638078 DamperStiffnessRqLift_TagAxle "RANGE";
BA_ "SPN" SG_ 2362638078 DamperStiffnessRqLift_TagAxle 1720;
BA_ "SigType" SG_ 2362638078 DamperStiffnessRqRearAxle "RANGE";
BA_ "SPN" SG_ 2362638078 DamperStiffnessRqRearAxle 1719;
BA_ "SigType" SG_ 2362638078 DamperStiffnessRqFrontAxle "RANGE";
BA_ "SPN" SG_ 2362638078 DamperStiffnessRqFrontAxle 1718;
BA_ "SigType" SG_ 2362638078 LevelCtrlModeRq "DISCRETE";
BA_ "SPN" SG_ 2362638078 LevelCtrlModeRq 1753;
BA_ "SigType" SG_ 2362638078 NominalLevelRqRearAxle "DISCRETE";
BA_ "SPN" SG_ 2362638078 NominalLevelRqRearAxle 1750;
BA_ "SigType" SG_ 2362638078 NominalLevelRqFrontAxle "DISCRETE";
BA_ "SPN" SG_ 2362638078 NominalLevelRqFrontAxle 1751;
BA_ "SigType" SG_ 2362638078 KneelingCtrlModeRq "DISCRETE";
BA_ "SPN" SG_ 2362638078 KneelingCtrlModeRq 1747;
BA_ "SigType" SG_ 2362638078 KneelingRqRightSide "DISCRETE";
BA_ "SPN" SG_ 2362638078 KneelingRqRightSide 1748;
BA_ "SigType" SG_ 2362638078 KneelingRqLeftSide "DISCRETE";
BA_ "SPN" SG_ 2362638078 KneelingRqLeftSide 1749;
BA_ "SigType" SG_ 2362638078 AutomaticTractionHelp "DISCRETE";
BA_ "SPN" SG_ 2362638078 AutomaticTractionHelp 2984;
BA_ "SigType" SG_ 2362638078 LiftAxle2PosCmd "DISCRETE";
BA_ "SPN" SG_ 2362638078 LiftAxle2PosCmd 1828;
BA_ "SigType" SG_ 2362638078 LiftAxle1PosCmd "DISCRETE";
BA_ "SPN" SG_ 2362638078 LiftAxle1PosCmd 1752;
BA_ "SigType" SG_ 2365479678 SspensionCtrlRefusalInformation "DISCRETE";
BA_ "SPN" SG_ 2365479678 SspensionCtrlRefusalInformation 1827;
BA_ "SigType" SG_ 2365479678 SuspensionRemoteCtrl2 "DISCRETE";
BA_ "SPN" SG_ 2365479678 SuspensionRemoteCtrl2 1825;
BA_ "SigType" SG_ 2365479678 SuspensionRemoteCtrl1 "DISCRETE";
BA_ "SPN" SG_ 2365479678 SuspensionRemoteCtrl1 1826;
BA_ "SigType" SG_ 2365479678 RearAxleInBumperRange "DISCRETE";
BA_ "SPN" SG_ 2365479678 RearAxleInBumperRange 1823;
BA_ "SigType" SG_ 2365479678 FrontAxleInBumperRange "DISCRETE";
BA_ "SPN" SG_ 2365479678 FrontAxleInBumperRange 1824;
BA_ "SigType" SG_ 2365479678 DoorRelease "DISCRETE";
BA_ "SPN" SG_ 2365479678 DoorRelease 1744;
BA_ "SigType" SG_ 2365479678 VehicleMotionInhibit "DISCRETE";
BA_ "SPN" SG_ 2365479678 VehicleMotionInhibit 1745;
BA_ "SigType" SG_ 2365479678 SecurityDevice "DISCRETE";
BA_ "SPN" SG_ 2365479678 SecurityDevice 1746;
BA_ "SigType" SG_ 2365479678 LevelCtrlMode "DISCRETE";
BA_ "SPN" SG_ 2365479678 LevelCtrlMode 1741;
BA_ "SigType" SG_ 2365479678 KneelingInformation "DISCRETE";
BA_ "SPN" SG_ 2365479678 KneelingInformation 1742;
BA_ "SigType" SG_ 2365479678 LiftingCtrlModeRearAxle "DISCRETE";
BA_ "SPN" SG_ 2365479678 LiftingCtrlModeRearAxle 1756;
BA_ "SigType" SG_ 2365479678 LiftingCtrlModeFrontAxle "DISCRETE";
BA_ "SPN" SG_ 2365479678 LiftingCtrlModeFrontAxle 1739;
BA_ "SigType" SG_ 2365479678 LoweringCtrlModeRearAxle "DISCRETE";
BA_ "SPN" SG_ 2365479678 LoweringCtrlModeRearAxle 1755;
BA_ "SigType" SG_ 2365479678 LoweringCtrlModeFrontAxle "DISCRETE";
BA_ "SPN" SG_ 2365479678 LoweringCtrlModeFrontAxle 1740;
BA_ "SigType" SG_ 2365479678 AboveNominalLevelRearAxle "DISCRETE";
BA_ "SPN" SG_ 2365479678 AboveNominalLevelRearAxle 1736;
BA_ "SigType" SG_ 2365479678 AboveNominalLevelFrontAxle "DISCRETE";
BA_ "SPN" SG_ 2365479678 AboveNominalLevelFrontAxle 1737;
BA_ "SigType" SG_ 2365479678 BelowNominalLevelRearAxle "DISCRETE";
BA_ "SPN" SG_ 2365479678 BelowNominalLevelRearAxle 1754;
BA_ "SigType" SG_ 2365479678 BelowNominalLevelFrontAxle "DISCRETE";
BA_ "SPN" SG_ 2365479678 BelowNominalLevelFrontAxle 1738;
BA_ "SigType" SG_ 2365479678 NominalLevelRearAxle "DISCRETE";
BA_ "SPN" SG_ 2365479678 NominalLevelRearAxle 1733;
BA_ "SigType" SG_ 2365479678 NominalLevelFrontAxle "DISCRETE";
BA_ "SPN" SG_ 2365479678 NominalLevelFrontAxle 1734;
BA_ "SigType" SG_ 2365479678 LiftAxle2Pos "DISCRETE";
BA_ "SPN" SG_ 2365479678 LiftAxle2Pos 1822;
BA_ "SigType" SG_ 2365479678 LiftAxle1Pos "DISCRETE";
BA_ "SPN" SG_ 2365479678 LiftAxle1Pos 1743;
BA_ "SigType" SG_ 2566837758 Alt4Status "DISCRETE";
BA_ "SPN" SG_ 2566837758 Alt4Status 3356;
BA_ "SigType" SG_ 2566837758 Alt3Status "DISCRETE";
BA_ "SPN" SG_ 2566837758 Alt3Status 3355;
BA_ "SigType" SG_ 2566837758 Alt2Status "DISCRETE";
BA_ "SPN" SG_ 2566837758 Alt2Status 3354;
BA_ "SigType" SG_ 2566837758 Alt1Status "DISCRETE";
BA_ "SPN" SG_ 2566837758 Alt1Status 3353;
BA_ "SigType" SG_ 2566837758 AltSpeed "RANGE";
BA_ "SPN" SG_ 2566837758 AltSpeed 589;
BA_ "SigType" SG_ 2633922558 AuxAbsPressReading "RANGE";
BA_ "SPN" SG_ 2633922558 AuxAbsPressReading 138;
BA_ "SigType" SG_ 2633922558 AuxGagePressReading1 "RANGE";
BA_ "SPN" SG_ 2633922558 AuxGagePressReading1 137;
BA_ "SigType" SG_ 2633922558 AuxVacuumPressReading "RANGE";
BA_ "SPN" SG_ 2633922558 AuxVacuumPressReading 136;
BA_ "SigType" SG_ 2566775038 SolarSensorMax "RANGE";
BA_ "SPN" SG_ 2566775038 SolarSensorMax 2611;
BA_ "SigType" SG_ 2566775038 SolarIntensityPercent "RANGE";
BA_ "SPN" SG_ 2566775038 SolarIntensityPercent 2610;
BA_ "SigType" SG_ 2566836478 TestLimitMinimum "RANGE";
BA_ "SPN" SG_ 2566836478 TestLimitMinimum 1228;
BA_ "SigType" SG_ 2566836478 TestLimitMaximum "RANGE";
BA_ "SPN" SG_ 2566836478 TestLimitMaximum 1227;
BA_ "SigType" SG_ 2566836478 TestValue "RANGE";
BA_ "SPN" SG_ 2566836478 TestValue 1226;
BA_ "SigType" SG_ 2566836478 TestType "RANGE";
BA_ "SPN" SG_ 2566836478 TestType 1225;
BA_ "SigType" SG_ 2566836478 TestIdentifier "RANGE";
BA_ "SPN" SG_ 2566836478 TestIdentifier 1224;
BA_ "SigType" SG_ 2565078782 TestIdentifier "RANGE";
BA_ "SPN" SG_ 2565078782 TestIdentifier 1224;
BA_ "SPN" SG_ 2566836222 FlashRedStopLamp 3039;
BA_ "SPN" SG_ 2566836222 FlashProtectLamp 3041;
BA_ "SigType" SG_ 2566836222 FlashMalfuncIndicatorLamp "DISCRETE";
BA_ "SPN" SG_ 2566836222 FlashMalfuncIndicatorLamp 3038;
BA_ "SPN" SG_ 2566836222 FlashAmberWarningLamp 3040;
BA_ "SigType" SG_ 2566836222 OccurenceCount5 "RANGE";
BA_ "SigType" SG_ 2566836222 OccurenceCount4 "RANGE";
BA_ "SigType" SG_ 2566836222 OccurenceCount3 "RANGE";
BA_ "SigType" SG_ 2566836222 OccurenceCount2 "RANGE";
BA_ "SigType" SG_ 2566836222 OccurenceCount1 "RANGE";
BA_ "SPN" SG_ 2566836222 OccurenceCount1 1216;
BA_ "SPN" SG_ 2566836222 SPNConversionMethod1 1706;
BA_ "SPN" SG_ 2566836222 FailureModeIdentifier1 1215;
BA_ "SPN" SG_ 2566836222 SPN1 1214;
BA_ "SigType" SG_ 2566836222 MalfunctionIndicatorLampStatus "DISCRETE";
BA_ "SPN" SG_ 2566836222 MalfunctionIndicatorLampStatus 1213;
BA_ "SigType" SG_ 2566836222 RedStopLampState "DISCRETE";
BA_ "SPN" SG_ 2566836222 RedStopLampState 623;
BA_ "SigType" SG_ 2566836222 AmberWarningLampStatus "DISCRETE";
BA_ "SPN" SG_ 2566836222 AmberWarningLampStatus 624;
BA_ "SigType" SG_ 2566836222 ProtectLampStatus "DISCRETE";
BA_ "SPN" SG_ 2566836222 ProtectLampStatus 987;
BA_ "SPN" SG_ 2566836222 SPN1High 1214;
BA_ "SPN" SG_ 2566835966 MisfireMonitoringSupport 1221;
BA_ "SigType" SG_ 2566835966 OBDCompliance "RANGE";
BA_ "SPN" SG_ 2566835966 OBDCompliance 1220;
BA_ "SigType" SG_ 2566835966 PreviouslyActiveTroubleCodes "RANGE";
BA_ "SPN" SG_ 2566835966 PreviouslyActiveTroubleCodes 1219;
BA_ "SigType" SG_ 2566835966 ActiveTroubleCodes "RANGE";
BA_ "SPN" SG_ 2566835966 ActiveTroubleCodes 1218;
BA_ "SPN" SG_ 2566835966 SecondAirSystemMonStatus 1223;
BA_ "SPN" SG_ 2566835966 EvaporativeSystemMonStatus 1223;
BA_ "SPN" SG_ 2566835966 ACSystemRefrigerantMonStatus 1223;
BA_ "SPN" SG_ 2566835966 OxygenSensorHeaterMonStatus 1223;
BA_ "SPN" SG_ 2566835966 OxygenSensorMonStatus 1223;
BA_ "SPN" SG_ 2566835966 EGRSystemMonitoringStatus 1223;
BA_ "SPN" SG_ 2566835966 CatalystMonStatus 1223;
BA_ "SPN" SG_ 2566835966 ColdStartAidSystemMonStatus 1223;
BA_ "SPN" SG_ 2566835966 HeatedCatalystMonStatus 1223;
BA_ "SPN" SG_ 2566835966 CatalystMonSupp 1222;
BA_ "SPN" SG_ 2566835966 ColdStartAidSystemMonSupp 1222;
BA_ "SPN" SG_ 2566835966 HeatedCatalystMonSupp 1222;
BA_ "SPN" SG_ 2566835966 EvaporativeSystemMonSupp 1222;
BA_ "SPN" SG_ 2566835966 SecondAirSystemMonSupp 1222;
BA_ "SPN" SG_ 2566835966 ACSystemRefrigerantMonSupp 1222;
BA_ "SPN" SG_ 2566835966 OxygenSensorMonSupp 1222;
BA_ "SPN" SG_ 2566835966 OxygenSensorHeaterMonSupp 1222;
BA_ "SPN" SG_ 2566835966 EGRSystemMonitoringSupp 1222;
BA_ "SPN" SG_ 2566835966 MisfireMonitoringStatus 1221;
BA_ "SPN" SG_ 2566835966 ComprehensiveCompMonStatus 1221;
BA_ "SPN" SG_ 2566835966 FuelSystemMonitoringStatus 1221;
BA_ "SPN" SG_ 2566835966 ComprehensiveComponentMonSupp 1221;
BA_ "SPN" SG_ 2566835966 FuelSystemMonitoringSupport 1221;
BA_ "SigType" SG_ 2566835710 OccurenceCount1 "RANGE";
BA_ "SPN" SG_ 2566835710 OccurenceCount1 1216;
BA_ "SPN" SG_ 2566835710 SPNConversionMethod1 1706;
BA_ "SPN" SG_ 2566835710 FailureModeIdentifier1 1215;
BA_ "SPN" SG_ 2566835710 SPN1 1214;
BA_ "SPN" SG_ 2566835710 FreezeFrameLength 1217;
BA_ "SigType" SG_ 2566835710 EngSpeed "RANGE";
BA_ "SPN" SG_ 2566835710 EngSpeed 190;
BA_ "SigType" SG_ 2566835710 EngTorqueMode "DISCRETE";
BA_ "SPN" SG_ 2566835710 EngTorqueMode 899;
BA_ "SigType" SG_ 2566835710 EngTurboBoostPress "RANGE";
BA_ "SPN" SG_ 2566835710 EngTurboBoostPress 102;
BA_ "SigType" SG_ 2566835710 WheelBasedVehicleSpeed "RANGE";
BA_ "SPN" SG_ 2566835710 WheelBasedVehicleSpeed 84;
BA_ "SigType" SG_ 2566835710 EngPercentLoadAtCurrentSpeed "RANGE";
BA_ "SPN" SG_ 2566835710 EngPercentLoadAtCurrentSpeed 92;
BA_ "SigType" SG_ 2566835710 EngineCoolantTemperature "RANGE";
BA_ "SPN" SG_ 2566835710 EngineCoolantTemperature 110;
BA_ "SPN" SG_ 2566835710 SPN1High 1214;
VAL_ 2364539902 VhclAccelerationRateLimitStatus 3 "NotAvailable" 2 "Reserved" 1 "LimitActive" 0 "LimitNotActive" ;
VAL_ 2364539902 AccelPedal2LowIdleSwitch 3 "NotAvailable" 2 "Error" 1 "AccelPedal2InLowIdleCondition" 0 "AcclPedal2NotInLowIdleCondition" ;
VAL_ 2364539902 RoadSpeedLimitStatus 3 "NotAvailable" 2 "Error" 1 "NotActive" 0 "Active" ;
VAL_ 2364539902 AccelPedalKickdownSwitch 3 "NotAvailable" 2 "Error" 1 "KickdownActive" 0 "KickdownPassive" ;
VAL_ 2364539902 AccelPedal1LowIdleSwitch 3 "NotAvailable" 2 "Error" 1 "AccelPedal1InLowIdleCondition" 0 "AcclPedal1NotInLowIdleCondition" ;
VAL_ 2364540158 EngStarterMode 15 "notAvailable" 14 "error" 12 "starterInhibitedReasonUnknown" 9 "1011Reserved" 8 "strtrInhbtdDueToStarterOvertemp" 7 "strtrInhbtdDToActiveImmobilizer" 6 "strtrInhbtdDTDrvlnEnggdOthrTrns" 5 "strtrInhbtdDTEngNtReadyForStart" 4 "strtrInhbtdDToEngAlreadyRunning" 3 "strtFnshdStrtrNtActvAftrHvngBnA" 2 "starterActiveGearEngaged" 1 "starterActiveGearNotEngaged" 0 "startNotRqed" ;
VAL_ 2364540158 EngTorqueMode 15 "Not available" 11 "Remote accelerator" 10 "Braking system" 9 "High speed governor" 8 "Torque limiting" 7 "ABS control" 6 "Transmission control" 5 "ASR control" 4 "Road speed governor" 3 "PTO governor" 2 "Cruise control" 1 "Accelerator pedal/operator selec" 0 "Low idle governor/no request (de" ;
VAL_ 2566841342 SupportTSC1CtrlPurposeGroup4Of4 1 "P25ReservedForAssignmentBySAE" ;
VAL_ 2566841342 SupportVariableRateTSC1Message 1 "MsTransRate" ;
VAL_ 2566841342 SupportTSC1CtrlPurposeGroup3Of4 1 "P17ReservedForAssignmentBySAE" ;
VAL_ 2566841342 SupportTSC1CtrlPurposeGroup2Of4 1 "P9ReservedForAssignmentBySAE" ;
VAL_ 2566841342 SupportTSC1CtrlPurposeGroup1Of4 1 "P1AccelPedal_OperatorSelection" ;
VAL_ 2566767870 XBRActiveCtrlMode 15 "NotAvailable" 4 "1110ReservedForSAEAssignment" 3 "MxMdOfXBRAcclrtnCtrlBngExecuted" 2 "AddtnMdOfXBRAcclrtnCtrlBngExctd" 1 "DrvrsBrkDmndBngExctdNExtlBrkDmn" 0 "NoBrakeDemandBeingExecuted" ;
VAL_ 2566767870 XBRSystemState 3 "NotAvailable" 2 "NoExtlBrakeDemandWillBeAccepted" 1 "OnlyExtlBrkDmndOfHghstXBRPrrtyW" 0 "AnyExtlBrkeDemandWillBeAccepted" ;
VAL_ 2566767870 FoundationBrakeUse 3 "NotAvailable" 2 "Reserved" 1 "FoundationBrakesInUse" 0 "FoundationBrakesNotInUse" ;
VAL_ 2566767870 HillHolderMode 7 "NotAvailable" 6 "Reserved" 3 "101NotDefined" 2 "ActvBtWllChngTInctvInAShortTime" 1 "Active" 0 "Inactive" ;
VAL_ 2566767870 HaltBrakeMode 7 "NotAvailable" 6 "Reserved" 3 "101NotDefined" 2 "ActiveButNotFunctioningProperly" 1 "Active" 0 "Inactive" ;
VAL_ 2565865982 TrctrMntdTrilerABSWarningSignal 3 "TakeNoAction" 2 "Reserved" 1 "On" 0 "Off" ;
VAL_ 2565865982 TrailerABSStatus 3 "TrlrABSSttsInfrmtnNtAvlblPrmtrN" 2 "Reserved" 1 "TrailerABSActive" 0 "TrlrABSSttsInfrmtnAvlblBtNtActv" ;
VAL_ 2565865982 HaltBrakeSwitch 3 "NotAvailable" 2 "Error" 1 "HaltBrakeSwitchActive" 0 "HaltBrakeSwitchPassive" ;
VAL_ 2565865982 ATC_ASRInformationSignal 3 "TakeNoAction" 2 "Reserved" 1 "On" 0 "Off" ;
VAL_ 2565865982 ABS_EBSAmberWarningSignal 3 "TakeNoAction" 2 "Reserved" 1 "On" 0 "Off" ;
VAL_ 2565865982 EBSRedWarningSignal 3 "TakeNoAction" 2 "Reserved" 1 "On" 0 "Off" ;
VAL_ 2565865982 ABSFullyOperational 3 "NotAvailable" 2 "Reserved" 1 "FullyOperational" 0 "NotFullyOperational" ;
VAL_ 2565865982 RemoteAccelEnableSwitch 3 "NotAvailable" 2 "Error" 1 "On" 0 "Off" ;
VAL_ 2565865982 EngAuxEngShutdownSwitch 3 "NotAvailable" 2 "Error" 1 "On" 0 "Off" ;
VAL_ 2565865982 EngDerateSwitch 3 "NotAvailable" 2 "Error" 1 "On" 0 "Off" ;
VAL_ 2565865982 AccelInterlockSwitch 3 "NotAvailable" 2 "Error" 1 "On" 0 "Off" ;
VAL_ 2565865982 TractionCtrlOverrideSwitch 3 "NotAvailableNotInstalled" 2 "Error" 1 "On" 0 "Off" ;
VAL_ 2565865982 ASRHillHolderSwitch 3 "NotAvailable" 2 "Error" 1 "ASRHillHolderSwitchActive" 0 "ASRHillHolderSwitchPassive" ;
VAL_ 2565865982 ASROffroadSwitch 2 "Error" 1 "ASROffroadSwitchActive" 0 "ASROffroadSwitchPassive" 3 "NotAvailable" ;
VAL_ 2565865982 ABSOffroadSwitch 3 "NotAvailable" 2 "Error" 1 "ABSOffroadSwitchActive" 0 "ABSOffroadSwitchPassive" ;
VAL_ 2565865982 EBSBrakeSwitch 3 "NotAvailable" 2 "Error" 1 "BrakePedalIsBeingPressed" 0 "BrakePedalIsNotBeingPressed" ;
VAL_ 2565865982 AntiLockBrakingActive 3 "NotAvailable" 2 "Reserved" 1 "ABSActive" 0 "ABSPassiveButInstalled" ;
VAL_ 2565865982 ASRBrakeCtrlActive 3 "NotAvailable" 2 "Reserved" 1 "ASRBrakeCtrlActive" 0 "ASRBrakeCtrlPassiveButInstalled" ;
VAL_ 2565865982 ASREngCtrlActive 3 "NotAvailable" 2 "Reserved" 1 "ASREngCtrlActive" 0 "ASREngCtrlPassiveButInstalled" ;
VAL_ 2565867262 DiffLockStateCentralRear 3 "NotAvailable" 2 "Error" 1 "DiffLockEngaged" 0 "DiffLockDisengaged" ;
VAL_ 2565867262 DiffLockStateCentralFront 3 "NotAvailable" 2 "Error" 1 "DiffLockEngaged" 0 "DiffLockDisengaged" ;
VAL_ 2565867262 DiffLockStateCentral 3 "NotAvailable" 2 "Error" 1 "DiffLockEngaged" 0 "DiffLockDisengaged" ;
VAL_ 2565867262 DiffLockStateRearAxle2 3 "NotAvailable" 2 "Error" 1 "DiffLockEngaged" 0 "DiffLockDisengaged" ;
VAL_ 2565867262 DiffLockStateRearAxle1 3 "NotAvailable" 2 "Error" 1 "DiffLockEngaged" 0 "DiffLockDisengaged" ;
VAL_ 2565867262 DiffLockStateFrontAxle2 3 "NotAvailable" 2 "Error" 1 "DiffLockEngaged" 0 "DiffLockDisengaged" ;
VAL_ 2565867262 DiffLockStateFrontAxle1 3 "NotAvailable" 2 "Error" 1 "DiffLockEngaged" 0 "DiffLockDisengaged" ;
VAL_ 2566768382 EngStartEnableDevice2Config 15 "NotAvailable" 5 "1110Reserved" 4 "ElectricInletAirHeaterInstalled" 3 "EtherInjectionInstalled" 2 "FuelledStartInstalled" 1 "GlowPlugsInstalled" 0 "NoStartEnableDevice2Installed" ;
VAL_ 2566768382 EngStartEnableDevice1Config 15 "NotAvailable" 5 "1110Reserved" 4 "ElectricInletAirHeaterInstalled" 3 "EtherInjectionInstalled" 2 "FuelledStartInstalled" 1 "GlowPlugsInstalled" 0 "NoStartEnableDevice1Installed" ;
VAL_ 2566768382 EngStartEnableDevice2 2 "Reserved" 1 "StartEnableON" 0 "StartEnableOFF" ;
VAL_ 2566768382 EngStartEnableDevice1 3 "NotAvailible" 2 "Reserved" 1 "StartEnableON" 0 "StartEnableOFF" ;
VAL_ 2566771966 FifthWheelReleaseCtrl 3 "NotAvailable" 2 "Error" 1 "CplrUnlckdTrlrCnBUnhtchdHitched" 0 "CouplerLocked" ;
VAL_ 2566771966 FfthWhlRlaseCtrlSecurityLockout 3 "NotAvailable" 2 "Error" 1 "FifthWheelReleaseEnabled" 0 "FifthWheelReleaseDisabled" ;
VAL_ 2566771966 TransferCaseSelectorSwitch 6 "ErrorIndicator" 3 "101ReservedForSAEAssignment" 2 "Neutral" 1 "Wheel" ;
VAL_ 2564882174 RqCabZoneHeating 3 "DontCare_TakeNoAction" 2 "Reserved" 1 "HeatCabZone" 0 "DoNotCabEngZone" ;
VAL_ 2564882174 RqEngZoneHeating 3 "DontCare_TakeNoAction" 2 "Reserved" 1 "HeatEngZone" 0 "DoNotHeatEngZone" ;
VAL_ 2564882174 AuxHeaterModeRq 15 "DontCare_TakeNoAction" 14 "Reserved" 4 "1101NotDefined" 3 "NormalMode" 2 "EconomyMode" 1 "OffDTADRPrErpnRgltnsFrTrnsprtOf" 0 "DeactivateAuxHeater" ;
VAL_ 2564882174 SeatBeltSwitch 3 "NotAvailable" 2 "ErrrSwtchStteCannotBeDetermined" 1 "OKSeatBeltIsBuckled" 0 "NOTBuckled" ;
VAL_ 2564882174 OperatorSeatDirectionSwitch 3 "NotAvailable" 2 "Error" 1 "OperatorSeatIsFacingForward" 0 "OperatorSeatNotFacingForward" ;
VAL_ 2564882174 BatteryMainSwitchHoldRq 3 "DontCare_TakeNoAction" 2 "undefined" 1 "HoldBatteryMainSwitch" 0 "ReleaseBatteryMainSwitch" ;
VAL_ 2564882174 AuxHeaterCoolantPumpRq 3 "DontCare_TakeNoAction" 2 "Reserved" 1 "ActivateWaterPump" 0 "DeactivateWaterPump" ;
VAL_ 2566844926 EngShutdownOverrideSwitch 3 "NotAvailable" 2 "Error" 1 "On" 0 "Off" ;
VAL_ 2566844926 EngTestModeSwitch 3 "NotAvailable" 2 "Error" 1 "On" 0 "Off" ;
VAL_ 2566844926 EngIdleDecrementSwitch 3 "NotAvailable" 2 "Error" 1 "On" 0 "Off" ;
VAL_ 2566844926 EngIdleIncrementSwitch 3 "NotAvailable" 2 "Error" 1 "On" 0 "Off" ;
VAL_ 2566844926 CruiseCtrlAccelerateSwitch 3 "NotAvailable" 2 "Error" 1 "CrsCtrlActivatorInPosAccelerate" 0 "CrsCtrlActvtrNotInPosAccelerate" ;
VAL_ 2566844926 CruiseCtrlResumeSwitch 3 "NotAvailable" 2 "Error" 1 "CruiseCtrlActivatorInPosResume" 0 "CrseCtrlActivatorNotInPosResume" ;
VAL_ 2566844926 CruiseCtrlCoastSwitch 3 "NotAvailable" 2 "Error" 1 "CruiseCtrlActivatorInPosCoast" 0 "CriseCtrlActivatorNotInPosCoast" ;
VAL_ 2566844926 CruiseCtrlSetSwitch 3 "NotAvailable" 2 "Error" 1 "CruiseCtrlActivatorInPosSet" 0 "CruiseCtrlActivatorNotInPosSet" ;
VAL_ 2566844926 ClutchSwitch 3 "NotAvailable" 2 "Error" 1 "ClutchPedalDepressed" 0 "ClutchPedalReleased" ;
VAL_ 2566844926 BrakeSwitch 3 "NotAvailable" 2 "Error" 1 "BrakePedalDepressed" 0 "BrakePedalReleased" ;
VAL_ 2566844926 CruiseCtrlEnableSwitch 3 "NotAvailable" 2 "Error" 1 "CruiseCtrlEnabled" 0 "CruiseCtrlDisabled" ;
VAL_ 2566844926 CruiseCtrlActive 3 "NotAvailable" 2 "Error" 1 "CruiseCtrlSwitchedOn" 0 "CruiseCtrlSwitchedOff" ;
VAL_ 2566844926 CruiseCtrlPauseSwitch 3 "TakeNoAction" 2 "ErrorIndicator" 1 "On" 0 "Off" ;
VAL_ 2566844926 ParkingBrakeSwitch 3 "NotAvailable" 2 "Error" 1 "ParkingBrakeSet" 0 "ParkingBrakeNotSet" ;
VAL_ 2566844926 TwoSpeedAxleSwitch 3 "NotAvailable" 2 "Error" 1 "HighSpeedRange" 0 "LowSpeedRange" ;
VAL_ 2566809342 BatteryMainSwitchHoldState 3 "DontCare_TakeNoAction" 2 "Reserved" 1 "BatteryMainSwitchHeld" 0 "BatteryMainSwitchNotHeld" ;
VAL_ 2365446910 Joystick3XAxisDetentPosStatus 3 "NotAvailable" 2 "ErrorIndicator" 1 "InDetentPos" 0 "NotInDetentPos" ;
VAL_ 2365446910 Joystick3Button9PressedStatus 3 "NotAvailable" 2 "ErrorIndicator" 1 "ButtonPressed" 0 "ButtonNotPressed" ;
VAL_ 2365446910 Joystick3Button10PressedStatus 3 "NotAvailable" 2 "ErrorIndicator" 1 "ButtonPressed" 0 "ButtonNotPressed" ;
VAL_ 2365446910 Joystick3Button11PressedStatus 3 "NotAvailable" 2 "ErrorIndicator" 1 "ButtonPressed" 0 "ButtonNotPressed" ;
VAL_ 2365446910 Joystick3Button12PressedStatus 3 "NotAvailable" 2 "ErrorIndicator" 1 "ButtonPressed" 0 "ButtonNotPressed" ;
VAL_ 2365446910 Joystick3YAxisDetentPosStatus 3 "NotAvailable" 2 "ErrorIndicator" 1 "InDetentPos" 0 "NotInDetentPos" ;
VAL_ 2365446910 Jystck3YAxsLvrFrwrdPstvPsStatus 3 "NotAvailable" 2 "ErrorIndicator" 1 "OnPositiveSideOfNeutral" 0 "NotOnPositiveSideOfNeutral" ;
VAL_ 2365446910 Jystck3YAxsLvrBckNgtvePosStatus 3 "NotAvailable" 2 "ErrorIndicator" 1 "OnNegativeSideOfNeutral" 0 "NotOnNegativeSideOfNeutral" ;
VAL_ 2365446910 Joystick3YAxisNeutralPosStatus 3 "NotAvailable" 2 "ErrorIndicator" 1 "InNeutralPos" 0 "NotInNeutralPos" ;
VAL_ 2365446910 Jystck3XAxsLvrRghtPstvPosStatus 3 "NotAvailable" 2 "ErrorIndicator" 1 "OnPositiveSideOfNeutral" 0 "NotOnPositiveSideOfNeutral" ;
VAL_ 2365446910 Jystck3XAxsLvrLftNgtvePosStatus 2 "ErrorIndicator" 1 "OnNegativeSideOfNeutral" 0 "NotOnNegativeSideOfNeutral" 3 "NotAvailable" ;
VAL_ 2365446910 Joystick3XAxisNeutralPosStatus 3 "NotAvailable" 2 "ErrorIndicator" 1 "InNeutralPos" 0 "NotInNeutralPos" ;
VAL_ 2365446910 Joystick3Button5PressedStatus 3 "NotAvailable" 2 "ErrorIndicator" 1 "ButtonPressed" 0 "ButtonNotPressed" ;
VAL_ 2365446910 Joystick3Button6PressedStatus 3 "NotAvailable" 2 "ErrorIndicator" 1 "ButtonPressed" 0 "ButtonNotPressed" ;
VAL_ 2365446910 Joystick3Button7PressedStatus 3 "NotAvailable" 2 "ErrorIndicator" 1 "ButtonPressed" 0 "ButtonNotPressed" ;
VAL_ 2365446910 Joystick3Button8PressedStatus 3 "NotAvailable" 2 "ErrorIndicator" 1 "ButtonPressed" 0 "ButtonNotPressed" ;
VAL_ 2365446910 Joystick3Button1PressedStatus 3 "NotAvailable" 2 "ErrorIndicator" 1 "ButtonPressed" 0 "ButtonNotPressed" ;
VAL_ 2365446910 Joystick3Button2PressedStatus 3 "NotAvailable" 2 "ErrorIndicator" 1 "ButtonPressed" 0 "ButtonNotPressed" ;
VAL_ 2365446910 Joystick3Button3PressedStatus 3 "NotAvailable" 2 "ErrorIndicator" 1 "ButtonPressed" 0 "ButtonNotPressed" ;
VAL_ 2365446910 Joystick3Button4PressedStatus 3 "NotAvailable" 2 "ErrorIndicator" 1 "ButtonPressed" 0 "ButtonNotPressed" ;
VAL_ 2365446398 Joystick2XAxisDetentPosStatus 3 "NotAvailable" 2 "ErrorIndicator" 1 "InDetentPos" 0 "NotInDetentPos" ;
VAL_ 2365446398 Joystick2YAxisDetentPosStatus 3 "NotAvailable" 2 "ErrorIndicator" 1 "InDetentPos" 0 "NotInDetentPos" ;
VAL_ 2365446398 Jystck2YAxsLvrFrwrdPstvPsStatus 3 "NotAvailable" 2 "ErrorIndicator" 1 "OnPositiveSideOfNeutral" 0 "NotOnPositiveSideOfNeutral" ;
VAL_ 2365446398 Jystck2YAxsLvrBckNgtvePosStatus 3 "NotAvailable" 2 "ErrorIndicator" 1 "OnNegativeSideOfNeutral" 0 "NotOnNegativeSideOfNeutral" ;
VAL_ 2365446398 Joystick2YAxisNeutralPosStatus 3 "NotAvailable" 2 "ErrorIndicator" 1 "InNeutralPos" 0 "NotInNeutralPos" ;
VAL_ 2365446398 Jystck2XAxsLvrRghtPstvPosStatus 3 "NotAvailable" 2 "ErrorIndicator" 1 "OnPositiveSideOfNeutral" 0 "NotOnPositiveSideOfNeutral" ;
VAL_ 2365446398 Jystck2XAxsLvrLftNgtvePosStatus 3 "NotAvailable" 2 "ErrorIndicator" 1 "OnNegativeSideOfNeutral" 0 "NotOnNegativeSideOfNeutral" ;
VAL_ 2365446398 Joystick2XAxisNeutralPosStatus 3 "NotAvailable" 2 "ErrorIndicator" 1 "InNeutralPos" 0 "NotInNeutralPos" ;
VAL_ 2365446398 Joystick2Button9PressedStatus 3 "NotAvailable" 2 "ErrorIndicator" 1 "ButtonPressed" 0 "ButtonNotPressed" ;
VAL_ 2365446398 Joystick2Button10PressedStatus 3 "NotAvailable" 2 "ErrorIndicator" 1 "ButtonPressed" 0 "ButtonNotPressed" ;
VAL_ 2365446398 Joystick2Button11PressedStatus 3 "NotAvailable" 2 "ErrorIndicator" 1 "ButtonPressed" 0 "ButtonNotPressed" ;
VAL_ 2365446398 Joystick2Button12PressedStatus 3 "NotAvailable" 2 "ErrorIndicator" 1 "ButtonPressed" 0 "ButtonNotPressed" ;
VAL_ 2365446398 Joystick2Button5PressedStatus 3 "NotAvailable" 2 "ErrorIndicator" 1 "ButtonPressed" 0 "ButtonNotPressed" ;
VAL_ 2365446398 Joystick2Button6PressedStatus 3 "NotAvailable" 2 "ErrorIndicator" 1 "ButtonPressed" 0 "ButtonNotPressed" ;
VAL_ 2365446398 Joystick2Button7PressedStatus 3 "NotAvailable" 2 "ErrorIndicator" 1 "ButtonPressed" 0 "ButtonNotPressed" ;
VAL_ 2365446398 Joystick2Button8PressedStatus 3 "NotAvailable" 2 "ErrorIndicator" 1 "ButtonPressed" 0 "ButtonNotPressed" ;
VAL_ 2365446398 Joystick2Button1PressedStatus 3 "NotAvailable" 2 "ErrorIndicator" 1 "ButtonPressed" 0 "ButtonNotPressed" ;
VAL_ 2365446398 Joystick2Button2PressedStatus 3 "NotAvailable" 2 "ErrorIndicator" 1 "ButtonPressed" 0 "ButtonNotPressed" ;
VAL_ 2365446398 Joystick2Button3PressedStatus 3 "NotAvailable" 2 "ErrorIndicator" 1 "ButtonPressed" 0 "ButtonNotPressed" ;
VAL_ 2365446398 Joystick2Button4PressedStatus 3 "NotAvailable" 2 "ErrorIndicator" 1 "ButtonPressed" 0 "ButtonNotPressed" ;
VAL_ 2365445886 Joystick1XAxisDetentPosStatus 3 "NotAvailable" 2 "ErrorIndicator" 1 "InDetentPos" 0 "NotInDetentPos" ;
VAL_ 2365445886 Joystick1YAxisDetentPosStatus 3 "NotAvailable" 2 "ErrorIndicator" 1 "InDetentPos" 0 "NotInDetentPos" ;
VAL_ 2365445886 Jystck1YAxsLvrFrwrdPstvPsStatus 1 "OnPositiveSideOfNeutral" 0 "NotOnPositiveSideOfNeutral" 3 "NotAvailable" 2 "ErrorIndicator" ;
VAL_ 2365445886 Jystck1YAxsLvrBckNgtvePosStatus 3 "NotAvailable" 2 "ErrorIndicator" 1 "OnNegativeSideOfNeutral" 0 "NotOnNegativeSideOfNeutral" ;
VAL_ 2365445886 Joystick1YAxisNeutralPosStatus 3 "NotAvailable" 2 "ErrorIndicator" 1 "InNeutralPos" 0 "NotInNeutralPos" ;
VAL_ 2365445886 Joystick1Button9PressedStatus 3 "NotAvailable" 2 "ErrorIndicator" 1 "ButtonPressed" 0 "ButtonNotPressed" ;
VAL_ 2365445886 Joystick1Button10PressedStatus 3 "NotAvailable" 2 "ErrorIndicator" 1 "ButtonPressed" 0 "ButtonNotPressed" ;
VAL_ 2365445886 Joystick1Button11PressedStatus 3 "NotAvailable" 2 "ErrorIndicator" 1 "ButtonPressed" 0 "ButtonNotPressed" ;
VAL_ 2365445886 Joystick1Button12PressedStatus 3 "NotAvailable" 2 "ErrorIndicator" 1 "ButtonPressed" 0 "ButtonNotPressed" ;
VAL_ 2365445886 Joystick1Button5PressedStatus 3 "NotAvailable" 2 "ErrorIndicator" 1 "ButtonPressed" 0 "ButtonNotPressed" ;
VAL_ 2365445886 Joystick1Button6PressedStatus 3 "NotAvailable" 2 "ErrorIndicator" 1 "ButtonPressed" 0 "ButtonNotPressed" ;
VAL_ 2365445886 Joystick1Button7PressedStatus 3 "NotAvailable" 2 "ErrorIndicator" 1 "ButtonPressed" 0 "ButtonNotPressed" ;
VAL_ 2365445886 Joystick1Button8PressedStatus 3 "NotAvailable" 2 "ErrorIndicator" 1 "ButtonPressed" 0 "ButtonNotPressed" ;
VAL_ 2365445886 Joystick1Button1PressedStatus 3 "NotAvailable" 2 "ErrorIndicator" 1 "ButtonPressed" 0 "ButtonNotPressed" ;
VAL_ 2365445886 Joystick1Button2PressedStatus 3 "NotAvailable" 2 "ErrorIndicator" 1 "ButtonPressed" 0 "ButtonNotPressed" ;
VAL_ 2365445886 Joystick1Button3PressedStatus 3 "NotAvailable" 2 "ErrorIndicator" 1 "ButtonPressed" 0 "ButtonNotPressed" ;
VAL_ 2365445886 Joystick1Button4PressedStatus 3 "NotAvailable" 2 "ErrorIndicator" 1 "ButtonPressed" 0 "ButtonNotPressed" ;
VAL_ 2365445886 Jystck1XAxsLvrRghtPstvPosStatus 3 "NotAvailable" 2 "ErrorIndicator" 1 "OnPositiveSideOfNeutral" 0 "NotOnPositiveSideOfNeutral" ;
VAL_ 2365445886 Jystck1XAxsLvrLftNgtvePosStatus 3 "NotAvailable" 2 "ErrorIndicator" 1 "OnNegativeSideOfNeutral" 0 "NotOnNegativeSideOfNeutral" ;
VAL_ 2365445886 Joystick1XAxisNeutralPosStatus 3 "NotAvailable" 2 "ErrorIndicator" 1 "InNeutralPos" 0 "NotInNeutralPos" ;
VAL_ 2566847230 ParkingBrakeActuator 3 "NotAvailable" 2 "Error" 1 "ParkingBrakeActuatorActive" 0 "ParkingBrakeActuatorInactive" ;
VAL_ 2566838782 AuxI_O13 3 "NotAvailable" 2 "Error" 1 "AuxChannelOn" 0 "AuxChannelOff" ;
VAL_ 2566838782 AuxI_O14 3 "NotAvailable" 2 "Error" 1 "AuxChannelOn" 0 "AuxChannelOff" ;
VAL_ 2566838782 AuxI_O15 3 "NotAvailable" 2 "Error" 1 "AuxChannelOn" 0 "AuxChannelOff" ;
VAL_ 2566838782 AuxI_O16 3 "NotAvailable" 2 "Error" 1 "AuxChannelOn" 0 "AuxChannelOff" ;
VAL_ 2566838782 AuxI_O09 3 "NotAvailable" 2 "Error" 1 "AuxChannelOn" 0 "AuxChannelOff" ;
VAL_ 2566838782 AuxI_O10 3 "NotAvailable" 2 "Error" 1 "AuxChannelOn" 0 "AuxChannelOff" ;
VAL_ 2566838782 AuxI_O11 3 "NotAvailable" 2 "Error" 1 "AuxChannelOn" 0 "AuxChannelOff" ;
VAL_ 2566838782 AuxI_O12 3 "NotAvailable" 2 "Error" 1 "AuxChannelOn" 0 "AuxChannelOff" ;
VAL_ 2566838782 AuxI_O05 3 "NotAvailable" 2 "Error" 1 "AuxChannelOn" 0 "AuxChannelOff" ;
VAL_ 2566838782 AuxI_O06 3 "NotAvailable" 2 "Error" 1 "AuxChannelOn" 0 "AuxChannelOff" ;
VAL_ 2566838782 AuxI_O07 3 "NotAvailable" 2 "Error" 1 "AuxChannelOn" 0 "AuxChannelOff" ;
VAL_ 2566838782 AuxI_O08 3 "NotAvailable" 2 "Error" 1 "AuxChannelOn" 0 "AuxChannelOff" ;
VAL_ 2566838782 AuxI_O01 3 "NotAvailable" 2 "Error" 1 "AuxChannelOn" 0 "AuxChannelOff" ;
VAL_ 2566838782 AuxI_O02 3 "NotAvailable" 2 "Error" 1 "AuxChannelOn" 0 "AuxChannelOff" ;
VAL_ 2566838782 AuxI_O03 3 "NotAvailable" 2 "Error" 1 "AuxChannelOn" 0 "AuxChannelOff" ;
VAL_ 2566838782 AuxI_O04 3 "NotAvailable" 2 "Error" 1 "AuxChannelOn" 0 "AuxChannelOff" ;
VAL_ 2631728894 AntitheftComponentStatusStates 3 "NotDefined" 2 "BlckdThsSttIndctsThtALckUnlckCm" 1 "Locked" 0 "UnlckdThsSttIndctsThtCmpnntCnBS" ;
VAL_ 2631728894 AntthftEncryptnSdPrsntIndicator 3 "NotAvailable" 2 "Error" 1 "RandomNumberIsPresent" 0 "RandomNumberIsNotPresent" ;
VAL_ 2631728894 AntitheftModifyPwdStates 3 "Notvalid" 2 "EmptyOfPwdsThsSttIndctsThtCmpnn" 1 "FullofPwds" 0 "OkThsSttIndctsThtRqWsSccssfllyP" ;
VAL_ 2631728894 AntitheftPwdValidIndicator 3 "NotAvailable" 2 "Error" 1 "PwdIsAValidatedPassword" 0 "PwdIsNotAValidatedPassword" ;
VAL_ 2631794430 AntitheftCmdStates 6 "111NotDefined" 5 "Login" 4 "ChckSttsThsSttRprsntsARqTChckTS" 3 "LockorUnlock" 2 "ChngPwdThsSttRprsntsARqTCmpnntT" 1 "DeletePwd" 0 "AddPwdThsSttRprsntsARqTCmpnntTA" ;
VAL_ 2631794430 AntitheftDesiredExitModeStates 3 "NotAvailable" 2 "NotDefined" 1 "LockWhenKeyOff" 0 "LckUpnOprtrRqThsSttIsUsdTIndctT" ;
VAL_ 2631794430 AntthftEncryptonIndicatorStates 3 "NotAvailable" 2 "NotDefined" 1 "EncryptedCodePresent" 0 "EncryptnSdRqThsSttRprsntsARqstT" ;
VAL_ 2365478910 ElctrncShckAbsrbrCtrlMdLft_TgAxl 3 "NotAvailable" 2 "Error" 1 "NormalOperationDampersActive" 0 "NormalOperationDampersPassive" ;
VAL_ 2365478910 ElctrncShckAbsrbrCtrlMdRearAxle 3 "NotAvailable" 2 "Error" 1 "NormalOperationDampersActive" 0 "NormalOperationDampersPassive" ;
VAL_ 2365478910 ElctrncShckAbsrbrCtrlMdFrntAxle 3 "NotAvailable" 2 "Error" 1 "NormalOperationDampersActive" 0 "NormalOperationDampersPassive" ;
VAL_ 2362638078 ProhibitAirSuspensionCtrl 3 "NotAvailable" 2 "ErrorIndicator" 1 "RqProhibitAirSuspensionCtrl" 0 "NoRq" ;
VAL_ 2362638078 KneelingCmdRearAxle 3 "DontCare_TakeNoAction" 2 "Reserved" 1 "ActivateKneeling" 0 "DeactivateKneeling" ;
VAL_ 2362638078 KneelingCmdFrontAxle 3 "DontCare_TakeNoAction" 2 "Reserved" 1 "ActivateKneeling" 0 "DeactivateKneeling" ;
VAL_ 2362638078 LevelCtrlModeRq 15 "DontCare_TakeNoAction" 14 "Reserved" 9 "1101NotDefined" 8 "ExhaustBellows" 7 "TractionHelpLoadReduce" 6 "OptmmTrctn2IPrssAtThDrvnAxlIsCt" 5 "OptmmTrctn1IPrssAtThDrvnAxlIsCt" 4 "PrssRt2IRtBtwnThPrssrsAtThDrvnA" 3 "PrssRt1IRtBtwnThPrssrsAtThDrvnA" 2 "LdFxngIDrvnAxlnIsLddTAVlDfndByT" 1 "TrctnHlpIDrvnAxlIsLddTAMxVlGvnB" 0 "NrmlOprtnISystmPrfrmsAPrCtrlOfT" ;
VAL_ 2362638078 NominalLevelRqRearAxle 15 "DontCare_TakeNoAction" 14 "Reserved" 9 "1101NotDefined" 8 "StopLevelChange" 7 "LowerLevel" 6 "UpperLevel" 5 "CustomerLevel" 4 "PresetLevel" 3 "NormalLevel3" 2 "NormalLevel2" 1 "NormalLevel1" 0 "NoLevelRq" ;
VAL_ 2362638078 NominalLevelRqFrontAxle 15 "DontCare_TakeNoAction" 14 "Reserved" 9 "1101NotDefined" 8 "StopLevelChange" 7 "LowerLevel" 6 "UpperLevel" 5 "CustomerLevel" 4 "PresetLevel" 3 "NormalLevel3" 2 "NormalLevel2" 1 "NormalLevel1" 0 "NoLevelRq" ;
VAL_ 2362638078 KneelingCtrlModeRq 3 "DontCare_TakeNoAction" 2 "Reserved" 1 "ManuallyActuated" 0 "AutomaticallyActuated" ;
VAL_ 2362638078 KneelingRqRightSide 3 "DontCare_TakeNoAction" 2 "Reserved" 1 "KneelingRq" 0 "NoKneelingRq" ;
VAL_ 2362638078 KneelingRqLeftSide 3 "DontCare_TakeNoAction" 2 "Reserved" 1 "KneelingRq" 0 "NoKneelingRq" ;
VAL_ 2362638078 AutomaticTractionHelp 3 "DontCare" 2 "Reserved" 1 "EnableAutomaticTractionHelp" 0 "DisableAutomaticTractionHelp" ;
VAL_ 2362638078 LiftAxle2PosCmd 3 "DontCare_TakeNoAction" 2 "Reserved" 1 "LiftAxlePosUp_TagAxleUnladen" 0 "LiftAxlePosDown_TagAxleLaden" ;
VAL_ 2362638078 LiftAxle1PosCmd 3 "DontCare_TakeNoAction" 2 "Reserved" 1 "LiftAxlePosUp_TagAxleUnladen" 0 "LiftAxlePosDown_TagAxleLaden" ;
VAL_ 2365479678 SspensionCtrlRefusalInformation 7 "1101NotDefined" 15 "NotAvailable" 14 "Error" 6 "GnrlRjctINSpcifiedReasonApplies" 5 "BelowSpeedLimit" 4 "AboveSpeedLimit" 3 "BogieDiffNotLocked" 2 "WouldExceedAxleLoadLimit" 1 "AxleLoadLimitReached" 0 "ActualRqNotRefused" ;
VAL_ 2365479678 SuspensionRemoteCtrl2 3 "NotAvailable" 2 "Error" 1 "Active" 0 "NotActive" ;
VAL_ 2365479678 SuspensionRemoteCtrl1 3 "NotAvailable" 2 "Error" 1 "Active" 0 "NotActive" ;
VAL_ 2365479678 RearAxleInBumperRange 3 "NotAvailable" 2 "Error" 1 "ActualLevelWithinBumperRange" 0 "ActualLevelOutOfBumperRange" ;
VAL_ 2365479678 FrontAxleInBumperRange 3 "NotAvailable" 2 "Error" 1 "ActualLevelWithinBumperRange" 0 "ActualLevelOutOfBumperRange" ;
VAL_ 2365479678 DoorRelease 3 "NotAvailable" 2 "Error" 1 "DoorsMayBeOpened" 0 "DoorsMayNotBeOpened" ;
VAL_ 2365479678 VehicleMotionInhibit 3 "NotAvailable" 2 "Error" 1 "VehicleMotionIsInhibited" 0 "VehicleMayBeMoved" ;
VAL_ 2365479678 SecurityDevice 3 "NotAvailable" 2 "Error" 1 "Active" 0 "NotActive" ;
VAL_ 2365479678 LevelCtrlMode 10 "1101NotDefined" 15 "NotAvailable" 14 "Error" 9 "AirSuspensionCtrlProhibited" 8 "ExhstngBllwFnctnIBllwsArExhstdT" 7 "TractionHelpLoadReduce" 6 "OptmmTrctn2IPrssAtThDrvnAxlIsCt" 5 "OptmmTrctn1IPrssAtThDrvnAxlIsCt" 4 "PrssRt2IRtBtwnThPrssrsAtThDrvnA" 3 "PrssRt1IRtBtwnThPrssrsAtThDrvnA" 2 "LdFxngIDrvnAxlnIsLddTAVlDfndByT" 1 "TrctnHlpIDrvnAxlIsLddTAMxVlGvnB" 0 "NrmlOprtnISystmPrfrmsAPrCtrlOfT" ;
VAL_ 2365479678 KneelingInformation 15 "NotAvailable" 14 "Error" 5 "1101NotDefined" 4 "KneelingAborted" 3 "LiftingActive" 2 "KneelingLevelReached" 0 "NotActive" ;
VAL_ 2365479678 LiftingCtrlModeRearAxle 3 "NotAvailable" 2 "Error" 1 "LiftingActive" 0 "LiftingNotActive" ;
VAL_ 2365479678 LiftingCtrlModeFrontAxle 3 "NotAvailable" 2 "Error" 1 "LiftingActive" 0 "LiftingNotActive" ;
VAL_ 2365479678 LoweringCtrlModeRearAxle 3 "NotAvailable" 2 "Error" 1 "LoweringActive" 0 "LoweringNotActive" ;
VAL_ 2365479678 LoweringCtrlModeFrontAxle 3 "NotAvailable" 2 "Error" 1 "LoweringActive" 0 "LoweringNotActive" ;
VAL_ 2365479678 AboveNominalLevelRearAxle 3 "NotAvailable" 2 "Error" 1 "Above" 0 "NotAbove" ;
VAL_ 2365479678 AboveNominalLevelFrontAxle 3 "NotAvailable" 2 "Error" 1 "Above" 0 "NotAbove" ;
VAL_ 2365479678 BelowNominalLevelRearAxle 3 "NotAvailable" 2 "Error" 1 "Below" 0 "NotBelow" ;
VAL_ 2365479678 BelowNominalLevelFrontAxle 3 "NotAvailable" 2 "Error" 1 "Below" 0 "NotBelow" ;
VAL_ 2365479678 NominalLevelRearAxle 15 "NotAvailable" 14 "Error" 8 "1101NotDefined" 7 "LowerLevel" 6 "UpperLevel" 5 "CustomerLevel" 4 "PresetLevel" 3 "NormalLevel3" 2 "NormalLevel2" 1 "NormalLevel1" 0 "LevelNotSpecified" ;
VAL_ 2365479678 NominalLevelFrontAxle 15 "NotAvailable" 14 "Error" 8 "1101NotDefined" 7 "LowerLevel" 6 "UpperLevel" 5 "CustomerLevel" 4 "PresetLevel" 3 "NormalLevel3" 2 "NormalLevel2" 1 "NormalLevel1" 0 "LevelNotSpecified" ;
VAL_ 2365479678 LiftAxle2Pos 3 "NotAvailable" 2 "Error" 1 "LiftAxlePosUp_TagAxleUnladen" 0 "LiftAxlePosDown_TagAxleLaden" ;
VAL_ 2365479678 LiftAxle1Pos 3 "NotAvailable" 2 "Error" 1 "LiftAxlePosUp_TagAxleUnladen" 0 "LiftAxlePosDown_TagAxleLaden" ;
VAL_ 2566837758 Alt4Status 3 "notAvailable" 2 "error" 1 "Alt4Charging" 0 "Alt4NotCharging" ;
VAL_ 2566837758 Alt3Status 3 "notAvailable" 2 "error" 1 "Alt3Charging" 0 "Alt3NotCharging" ;
VAL_ 2566837758 Alt2Status 3 "notAvailable" 2 "error" 1 "Alt2Charging" 0 "Alt2NotCharging" ;
VAL_ 2566837758 Alt1Status 3 "notAvailable" 2 "error" 1 "Alt1Charging" 0 "Alt1NotCharging" ;
VAL_ 2566836222 FailureModeIdentifier5 31 "Not available" 19 "Received network data in error" 18 "Below normal (moderately severe)" 17 "Below normal (least severe)" 16 "Above normal (moderately severe)" 15 "Above normal (least severe)" 14 "Special intstructions" 13 "Out of calibration" 12 "Bad intelligent device" 11 "Root cause not known" 10 "Abnormal rate of change" 9 "Abnormal update rate" 8 "Abnormal frequency" 7 "Mechanical system not responding" 6 "Current above normal" 5 "Current below normal" 4 "Voltage below normal" 3 "Voltage above normal" 2 "Data erratic" 1 "Below normal (most severe)" 0 "Above normal (most severe)" ;
VAL_ 2566836222 FailureModeIdentifier4 31 "Not available" 19 "Received network data in error" 18 "Below normal (moderately severe)" 17 "Below normal (least severe)" 16 "Above normal (moderately severe)" 15 "Above normal (least severe)" 14 "Special intstructions" 13 "Out of calibration" 12 "Bad intelligent device" 11 "Root cause not known" 10 "Abnormal rate of change" 9 "Abnormal update rate" 8 "Abnormal frequency" 7 "Mechanical system not responding" 6 "Current above normal" 5 "Current below normal" 4 "Voltage below normal" 3 "Voltage above normal" 2 "Data erratic" 1 "Below normal (most severe)" 0 "Above normal (most severe)" ;
VAL_ 2566836222 FlashRedStopLamp 3 "Unavailable / Do Not Flash" 2 "Reserved" 1 "Fast Flash" 0 "Slow Flash" ;
VAL_ 2566836222 FlashProtectLamp 3 "Unavailable / Do Not Flash" 2 "Reserved" 1 "Fast Flash" 0 "Slow Flash" ;
VAL_ 2566836222 FlashMalfuncIndicatorLamp 3 "Unavailable / Do Not Flash" 2 "Reserved" 1 "Fast Flash" 0 "Slow Flash" ;
VAL_ 2566836222 FlashAmberWarningLamp 3 "Unavailable / Do Not Flash" 2 "Reserved" 1 "Fast Flash" 0 "Slow Flash" ;
VAL_ 2566836222 FailureModeIdentifier3 31 "Not available" 19 "Received network data in error" 18 "Below normal (moderately severe)" 17 "Below normal (least severe)" 16 "Above normal (moderately severe)" 15 "Above normal (least severe)" 14 "Special intstructions" 13 "Out of calibration" 12 "Bad intelligent device" 11 "Root cause not known" 10 "Abnormal rate of change" 9 "Abnormal update rate" 8 "Abnormal frequency" 7 "Mechanical system not responding" 6 "Current above normal" 5 "Current below normal" 4 "Voltage below normal" 3 "Voltage above normal" 2 "Data erratic" 1 "Below normal (most severe)" 0 "Above normal (most severe)" ;
VAL_ 2566836222 FailureModeIdentifier2 31 "Not available" 19 "Received network data in error" 18 "Below normal (moderately severe)" 17 "Below normal (least severe)" 16 "Above normal (moderately severe)" 15 "Above normal (least severe)" 14 "Special intstructions" 13 "Out of calibration" 12 "Bad intelligent device" 11 "Root cause not known" 10 "Abnormal rate of change" 9 "Abnormal update rate" 8 "Abnormal frequency" 7 "Mechanical system not responding" 6 "Current above normal" 5 "Current below normal" 4 "Voltage below normal" 3 "Voltage above normal" 2 "Data erratic" 1 "Below normal (most severe)" 0 "Above normal (most severe)" ;
VAL_ 2566836222 FailureModeIdentifier1 31 "Not available" 19 "Received network data in error" 18 "Below normal (moderately severe)" 17 "Below normal (least severe)" 16 "Above normal (moderately severe)" 15 "Above normal (least severe)" 14 "Special intstructions" 13 "Out of calibration" 12 "Bad intelligent device" 11 "Root cause not known" 10 "Abnormal rate of change" 9 "Abnormal update rate" 8 "Abnormal frequency" 7 "Mechanical system not responding" 6 "Current above normal" 5 "Current below normal" 4 "Voltage below normal" 3 "Voltage above normal" 2 "Data erratic" 1 "Below normal (most severe)" 0 "Above normal (most severe)" ;
VAL_ 2566836222 MalfunctionIndicatorLampStatus 3 "Not available" 2 "Reserved" 1 "Lamp on" 0 "Lamp off" ;
VAL_ 2566836222 RedStopLampState 3 "Not available" 2 "Reserved" 1 "Lamp on" 0 "Lamp off" ;
VAL_ 2566836222 AmberWarningLampStatus 3 "Not available" 2 "Reserved" 1 "Lamp on" 0 "Lamp off" ;
VAL_ 2566836222 ProtectLampStatus 3 "Not available" 2 "Reserved" 1 "Lamp on" 0 "Lamp off" ;
VAL_ 2566835966 MisfireMonitoringSupport 3 "Not available" 2 "Reserved" 1 "test supported" 0 "test not supported" ;
VAL_ 2566835966 OBDCompliance 5 "Not intended to meet OBD II requ" 4 "OBD I" 3 "OBD and OBD II" 2 "OBD (Federal, EPA)" 1 "OBD II (California, ARB)" 0 "Reserver for assignment by SAE" ;
VAL_ 2566835966 SecondAirSystemMonStatus 1 "TestNotComplete" 0 "TestComplete" ;
VAL_ 2566835966 EvaporativeSystemMonStatus 1 "TestNotComplete" 0 "TestComplete" ;
VAL_ 2566835966 ACSystemRefrigerantMonStatus 1 "TestNotComplete" 0 "TestComplete" ;
VAL_ 2566835966 OxygenSensorHeaterMonStatus 1 "TestNotComplete" 0 "TestComplete" ;
VAL_ 2566835966 OxygenSensorMonStatus 1 "test not complete" 0 "test complete" ;
VAL_ 2566835966 EGRSystemMonitoringStatus 1 "TestNotComplete" 0 "TestComplete" ;
VAL_ 2566835966 CatalystMonStatus 0 "TestComplete" 1 "TestNotComplete" ;
VAL_ 2566835966 ColdStartAidSystemMonStatus 1 "TestNotComplete" 0 "TestComplete" ;
VAL_ 2566835966 HeatedCatalystMonStatus 1 "TestNotComplete" 0 "TestComplete" ;
VAL_ 2566835966 CatalystMonSupp 1 "TestSupported" 0 "TestNotSupported" ;
VAL_ 2566835966 ColdStartAidSystemMonSupp 1 "TestSupported" 0 "TestNotSupported" ;
VAL_ 2566835966 HeatedCatalystMonSupp 1 "TestSupported" 0 "TestNotSupported" ;
VAL_ 2566835966 EvaporativeSystemMonSupp 1 "TestSupported" 0 "TestNotSupported" ;
VAL_ 2566835966 SecondAirSystemMonSupp 1 "TestSupported" 0 "TestNotSupported" ;
VAL_ 2566835966 ACSystemRefrigerantMonSupp 1 "TestSupported" 0 "TestNotSupported" ;
VAL_ 2566835966 OxygenSensorMonSupp 1 "TestSupported" 0 "TestNotSupported" ;
VAL_ 2566835966 OxygenSensorHeaterMonSupp 1 "TestSupported" 0 "TestNotSupported" ;
VAL_ 2566835966 EGRSystemMonitoringSupp 1 "TestSupported" 0 "TestNotSupported" ;
VAL_ 2566835966 MisfireMonitoringStatus 1 "test not complete" 0 "test complete" ;
VAL_ 2566835966 ComprehensiveCompMonStatus 1 "test not complete" 0 "test complete" ;
VAL_ 2566835966 FuelSystemMonitoringStatus 1 "test not complete" 0 "test complete" ;
VAL_ 2566835966 ComprehensiveComponentMonSupp 3 "Not available" 2 "Reserved" 1 "test supported" 0 "test not supported" ;
VAL_ 2566835966 FuelSystemMonitoringSupport 1 "test supported" 0 "test not supported" ;
VAL_ 2566835710 FailureModeIdentifier1 31 "Not available" 19 "Received network data in error" 18 "Below normal (moderately severe)" 17 "Below normal (least severe)" 16 "Above normal (moderately severe)" 15 "Above normal (least severe)" 14 "Special intstructions" 13 "Out of calibration" 12 "Bad intelligent device" 11 "Root cause not known" 10 "Abnormal rate of change" 9 "Abnormal update rate" 8 "Abnormal frequency" 7 "Mechanical system not responding" 6 "Current above normal" 5 "Current below normal" 4 "Voltage below normal" 3 "Voltage above normal" 2 "Data erratic" 1 "Below normal (most severe)" 0 "Above normal (most severe)" ;
VAL_ 2566835710 EngTorqueMode 15 "Not available" 11 "Remote accelerator" 10 "Braking system" 9 "High speed governor" 8 "Torque limiting" 7 "ABS control" 6 "Transmission control" 5 "ASR control" 4 "Road speed governor" 3 "PTO governor" 2 "Cruise control" 1 "Accelerator pedal/operator selec" 0 "Low idle governor/no request (de" ;
